VERSION "12.2.3"

NS_ :

BS_:

BU_: AVAS EPS FCAM_Chassis IDB_Chassis PAS_Chassis RCU_Chassis VCU_Chassis XGW_Chassis YSS

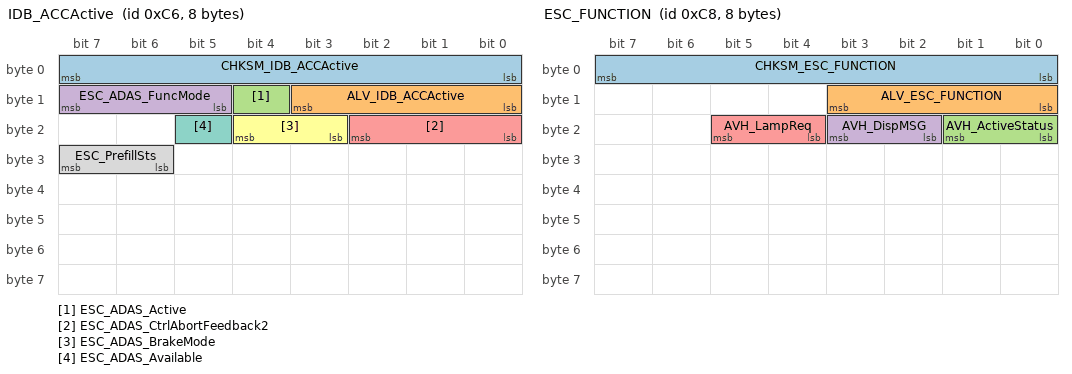
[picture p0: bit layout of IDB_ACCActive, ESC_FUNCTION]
BO_ 198 IDB_ACCActive: 8 IDB_Chassis
 SG_ CHKSM_IDB_ACCActive : 7|8@0+ (1,0) [0|255] ""  FCAM_Chassis,PAS_Chassis,VCU_Chassis
 SG_ ALV_IDB_ACCActive : 11|4@0+ (1,0) [0|14] ""  FCAM_Chassis,PAS_Chassis,VCU_Chassis
 SG_ ESC_ADAS_Active : 12|1@0+ (1,0) [0|1] ""  FCAM_Chassis,PAS_Chassis
 SG_ ESC_ADAS_FuncMode : 15|3@0+ (1,0) [0|7] ""  FCAM_Chassis,PAS_Chassis
 SG_ ESC_ADAS_CtrlAbortFeedback2 : 18|3@0+ (1,0) [0|7] ""  FCAM_Chassis,PAS_Chassis
 SG_ ESC_ADAS_BrakeMode : 20|2@0+ (1,0) [0|3] ""  FCAM_Chassis,PAS_Chassis
 SG_ ESC_ADAS_Available : 21|1@0+ (1,0) [0|1] ""  FCAM_Chassis,PAS_Chassis,VCU_Chassis
 SG_ ESC_PrefillSts : 31|2@0+ (1,0) [0|3] ""  FCAM_Chassis,PAS_Chassis

BO_ 200 ESC_FUNCTION: 8 IDB_Chassis
 SG_ CHKSM_ESC_FUNCTION : 7|8@0+ (1,0) [0|255] ""  VCU_Chassis,XGW_Chassis,RCU_Chassis
 SG_ ALV_ESC_FUNCTION : 11|4@0+ (1,0) [0|14] ""  VCU_Chassis,XGW_Chassis,RCU_Chassis
 SG_ AVH_ActiveStatus : 17|2@0+ (1,0) [0|3] ""  VCU_Chassis,XGW_Chassis,RCU_Chassis
 SG_ AVH_DispMSG : 19|2@0+ (1,0) [0|3] ""  VCU_Chassis,XGW_Chassis,RCU_Chassis
 SG_ AVH_LampReq : 21|2@0+ (1,0) [0|3] ""  VCU_Chassis,XGW_Chassis,RCU_Chassis

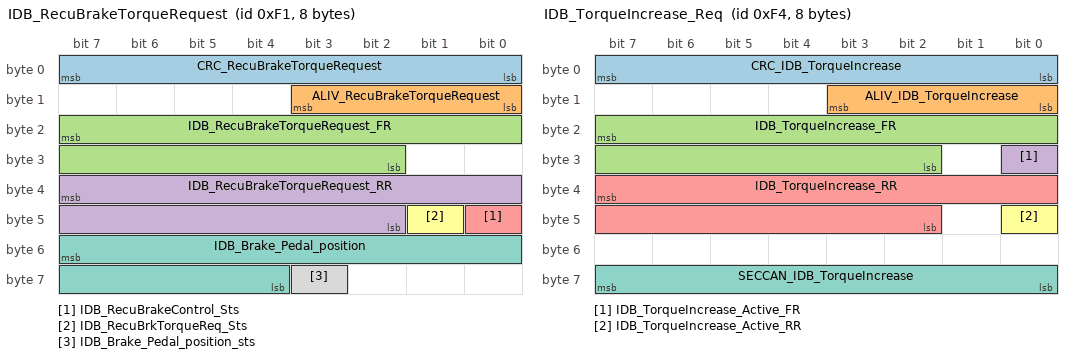
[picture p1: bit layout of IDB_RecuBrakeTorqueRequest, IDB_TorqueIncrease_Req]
BO_ 241 IDB_RecuBrakeTorqueRequest: 8 IDB_Chassis
 SG_ CRC_RecuBrakeTorqueRequest : 7|8@0+ (1,0) [0|255] ""  FCAM_Chassis,PAS_Chassis,RCU_Chassis,VCU_Chassis
 SG_ ALIV_RecuBrakeTorqueRequest : 11|4@0+ (1,0) [0|14] ""  FCAM_Chassis,PAS_Chassis,RCU_Chassis,VCU_Chassis
 SG_ IDB_RecuBrakeTorqueRequest_FR : 23|14@0+ (1,0) [0|8000] "Nm"  RCU_Chassis,VCU_Chassis
 SG_ IDB_RecuBrakeTorqueRequest_RR : 39|14@0+ (1,0) [0|8000] "Nm"  RCU_Chassis,VCU_Chassis
 SG_ IDB_RecuBrakeControl_Sts : 40|1@0+ (1,0) [0|1] ""  RCU_Chassis,VCU_Chassis
 SG_ IDB_RecuBrkTorqueReq_Sts : 41|1@0+ (1,0) [0|1] ""  VCU_Chassis
 SG_ IDB_Brake_Pedal_position : 55|12@0+ (0.0625,0) [0|100] "%"  FCAM_Chassis,RCU_Chassis,VCU_Chassis
 SG_ IDB_Brake_Pedal_position_sts : 59|1@0+ (1,0) [0|1] ""  FCAM_Chassis,PAS_Chassis,RCU_Chassis,VCU_Chassis

BO_ 244 IDB_TorqueIncrease_Req: 8 IDB_Chassis
 SG_ CRC_IDB_TorqueIncrease : 7|8@0+ (1,0) [0|255] ""  VCU_Chassis
 SG_ ALIV_IDB_TorqueIncrease : 11|4@0+ (1,0) [0|14] ""  VCU_Chassis
 SG_ IDB_TorqueIncrease_FR : 23|14@0- (1,0) [-8000|8000] "Nm"  VCU_Chassis
 SG_ IDB_TorqueIncrease_Active_FR : 24|1@0+ (1,0) [0|1] ""  VCU_Chassis
 SG_ IDB_TorqueIncrease_RR : 39|14@0- (1,0) [-8000|8000] "Nm"  VCU_Chassis
 SG_ IDB_TorqueIncrease_Active_RR : 40|1@0+ (1,0) [0|1] ""  VCU_Chassis
 SG_ SECCAN_IDB_TorqueIncrease : 63|8@0+ (1,0) [0|255] ""  VCU_Chassis

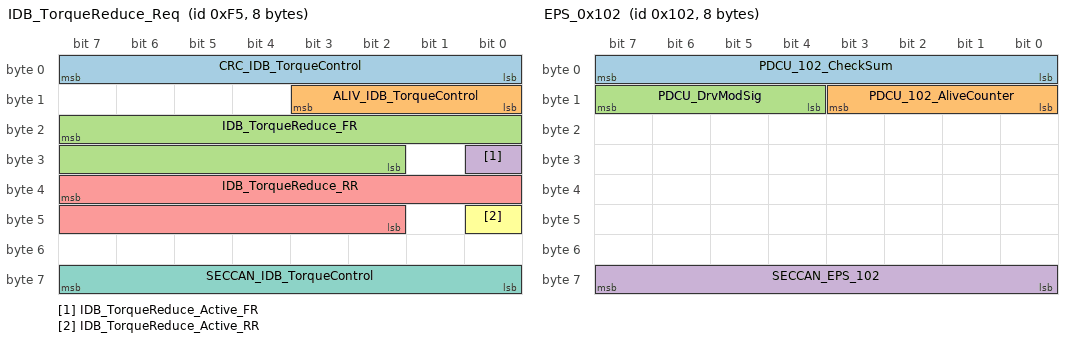
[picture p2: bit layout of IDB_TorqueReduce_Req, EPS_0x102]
BO_ 245 IDB_TorqueReduce_Req: 8 IDB_Chassis
 SG_ CRC_IDB_TorqueControl : 7|8@0+ (1,0) [0|255] ""  VCU_Chassis
 SG_ ALIV_IDB_TorqueControl : 11|4@0+ (1,0) [0|14] ""  VCU_Chassis
 SG_ IDB_TorqueReduce_FR : 23|14@0- (1,0) [-8000|8000] "Nm"  VCU_Chassis
 SG_ IDB_TorqueReduce_Active_FR : 24|1@0+ (1,0) [0|1] ""  VCU_Chassis
 SG_ IDB_TorqueReduce_RR : 39|14@0- (1,0) [-8000|8000] "Nm"  VCU_Chassis
 SG_ IDB_TorqueReduce_Active_RR : 40|1@0+ (1,0) [0|1] ""  VCU_Chassis
 SG_ SECCAN_IDB_TorqueControl : 63|8@0+ (1,0) [0|255] ""  VCU_Chassis

BO_ 257 MHU_DMS_DriverAttentionWarn: 8 XGW_Chassis
  SG_ DrowsDistractionLvl : 4|5@0+ (1,0) [0|31] "" Vector__XXX
  SG_ DriverAttentionWarn : 7|3@0+ (1,0) [0|7] "" Vector_XXX
  SG_ Haptic_Warning : 9|2@0+ (1,0) [0|3] "" EPS

BO_ 258 EPS_0x102: 8 VCU_Chassis
 SG_ PDCU_102_CheckSum : 7|8@0+ (1,0) [0|255] ""  EPS,FCAM_Chassis
 SG_ PDCU_102_AliveCounter : 11|4@0+ (1,0) [0|14] ""  EPS,FCAM_Chassis
 SG_ PDCU_DrvModSig : 15|4@0+ (1,0) [0|15] ""  EPS,FCAM_Chassis
 SG_ SECCAN_EPS_102 : 63|8@0+ (1,0) [0|255] ""  EPS

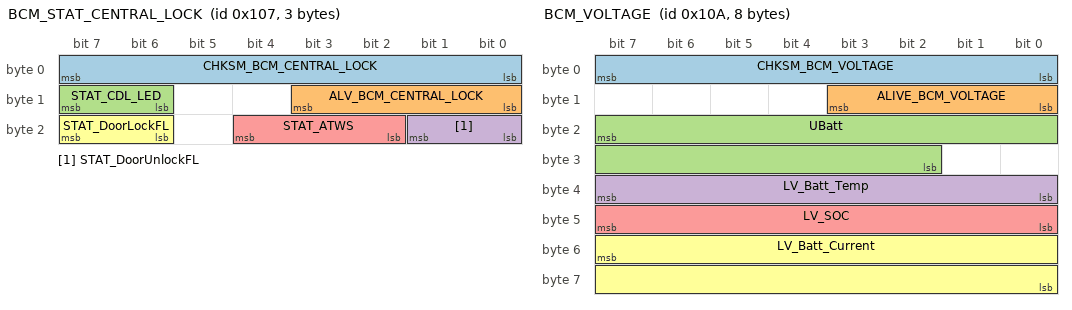
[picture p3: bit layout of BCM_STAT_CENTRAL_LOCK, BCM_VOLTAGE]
BO_ 263 BCM_STAT_CENTRAL_LOCK: 3 XGW_Chassis
 SG_ CHKSM_BCM_CENTRAL_LOCK : 7|8@0+ (1,0) [0|255] ""  VCU_Chassis
 SG_ ALV_BCM_CENTRAL_LOCK : 11|4@0+ (1,0) [0|14] ""  VCU_Chassis
 SG_ STAT_CDL_LED : 15|2@0+ (1,0) [0|3] ""  VCU_Chassis
 SG_ STAT_DoorUnlockFL : 17|2@0+ (1,0) [0|3] "Bit"  VCU_Chassis
 SG_ STAT_ATWS : 20|3@0+ (1,0) [0|7] "Bit"  VCU_Chassis
 SG_ STAT_DoorLockFL : 23|2@0+ (1,0) [0|3] "Bit"  VCU_Chassis

BO_ 266 BCM_VOLTAGE: 8 XGW_Chassis
 SG_ CHKSM_BCM_VOLTAGE : 7|8@0+ (1,0) [0|255] ""  AVAS,EPS,IDB_Chassis,RCU_Chassis,VCU_Chassis,YSS
 SG_ ALIVE_BCM_VOLTAGE : 11|4@0+ (1,0) [0|14] ""  AVAS,EPS,IDB_Chassis,RCU_Chassis,VCU_Chassis,YSS
 SG_ UBatt : 23|14@0+ (0.0009777,3) [3|18] "V"  AVAS,EPS,IDB_Chassis,RCU_Chassis,VCU_Chassis,YSS
 SG_ LV_Batt_Temp : 39|8@0+ (1,-40) [-40|105] "Degree C"  AVAS,EPS,IDB_Chassis,RCU_Chassis,VCU_Chassis,YSS
 SG_ LV_SOC : 47|8@0+ (1,0) [0|100] "%"  AVAS,EPS,IDB_Chassis,RCU_Chassis,VCU_Chassis,YSS
 SG_ LV_Batt_Current : 55|16@0+ (0.03125,-1536) [-1536|511.90625] "A"  AVAS,EPS,IDB_Chassis,RCU_Chassis,VCU_Chassis,YSS

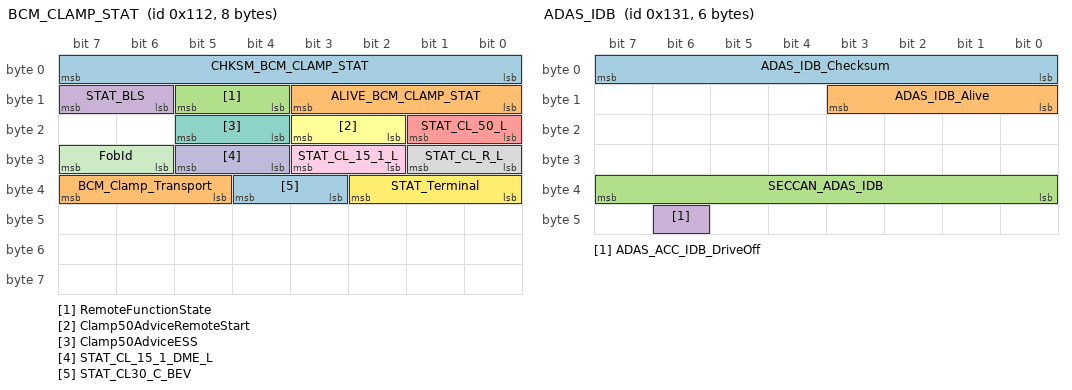
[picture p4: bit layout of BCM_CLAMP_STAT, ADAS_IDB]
BO_ 274 BCM_CLAMP_STAT: 8 XGW_Chassis
 SG_ CHKSM_BCM_CLAMP_STAT : 7|8@0+ (1,0) [0|255] ""  AVAS,EPS,IDB_Chassis,RCU_Chassis,VCU_Chassis,YSS
 SG_ ALIVE_BCM_CLAMP_STAT : 11|4@0+ (1,0) [0|14] ""  AVAS,EPS,IDB_Chassis,RCU_Chassis,VCU_Chassis,YSS
 SG_ RemoteFunctionState : 13|2@0+ (1,0) [0|3] ""  AVAS,EPS,IDB_Chassis,RCU_Chassis,VCU_Chassis,YSS
 SG_ STAT_BLS : 15|2@0+ (1,0) [0|3] ""  AVAS,EPS,IDB_Chassis,RCU_Chassis,VCU_Chassis,YSS
 SG_ STAT_CL_50_L : 17|2@0+ (1,0) [0|3] ""  AVAS,EPS,IDB_Chassis,RCU_Chassis,VCU_Chassis,YSS
 SG_ Clamp50AdviceRemoteStart : 19|2@0+ (1,0) [0|3] ""  AVAS,EPS,IDB_Chassis,RCU_Chassis,VCU_Chassis,YSS
 SG_ Clamp50AdviceESS : 21|2@0+ (1,0) [0|3] ""  AVAS,EPS,IDB_Chassis,RCU_Chassis,VCU_Chassis,YSS
 SG_ STAT_CL_R_L : 25|2@0+ (1,0) [0|3] ""  AVAS,EPS,IDB_Chassis,RCU_Chassis,VCU_Chassis,YSS
 SG_ STAT_CL_15_1_L : 27|2@0+ (1,0) [0|3] ""  AVAS,EPS,IDB_Chassis,RCU_Chassis,VCU_Chassis,YSS
 SG_ STAT_CL_15_1_DME_L : 29|2@0+ (1,0) [0|3] ""  AVAS,EPS,IDB_Chassis,RCU_Chassis,VCU_Chassis,YSS
 SG_ FobId : 31|2@0+ (1,0) [0|3] "Bit"  AVAS,EPS,IDB_Chassis,RCU_Chassis,VCU_Chassis,YSS
 SG_ STAT_Terminal : 34|3@0+ (1,0) [0|7] "Bit"  AVAS,EPS,IDB_Chassis,RCU_Chassis,VCU_Chassis,YSS
 SG_ STAT_CL30_C_BEV : 36|2@0+ (1,0) [0|3] "Bit"  AVAS,EPS,IDB_Chassis,RCU_Chassis,VCU_Chassis,YSS
 SG_ BCM_Clamp_Transport : 39|3@0+ (1,0) [0|7] ""  AVAS,EPS,IDB_Chassis,RCU_Chassis,VCU_Chassis,YSS

BO_ 275 IDB_BRAKE_PRESSURE: 5 IDB_Chassis
 SG_ MainCylinderPres : 7|16@0+ (0.01,0) [0|250] "bar"  FCAM_Chassis,VCU_Chassis
 SG_ STAT_MainCylinderPresValid : 21|2@0+ (1,0) [0|3] ""  FCAM_Chassis,VCU_Chassis
 SG_ BreakeVacuumPressure : 31|12@0- (0.1,0) [-100|10] "kPa"  VCU_Chassis

BO_ 305 ADAS_IDB: 6 FCAM_Chassis
 SG_ ADAS_IDB_Checksum : 7|8@0+ (1,0) [0|255] ""  IDB_Chassis
 SG_ ADAS_IDB_Alive : 11|4@0+ (1,0) [0|14] ""  IDB_Chassis
 SG_ SECCAN_ADAS_IDB : 39|8@0+ (1,0) [0|255] ""  IDB_Chassis
 SG_ ADAS_ACC_IDB_DriveOff : 46|1@0+ (1,0) [0|1] ""  IDB_Chassis

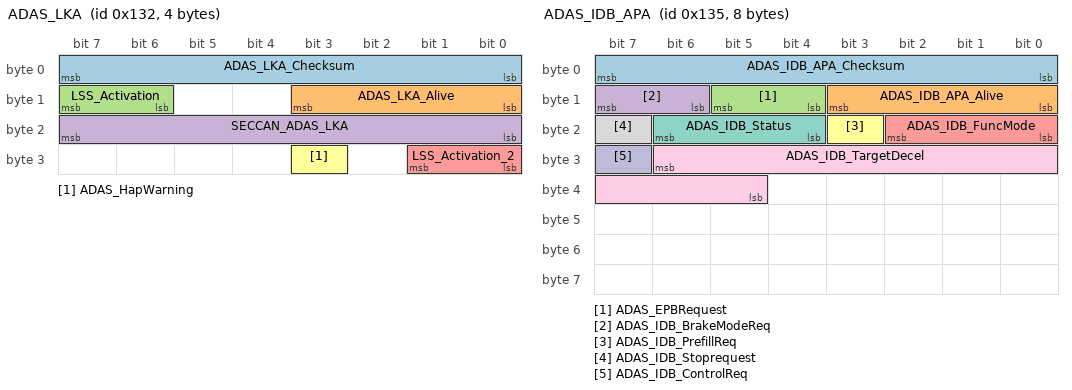
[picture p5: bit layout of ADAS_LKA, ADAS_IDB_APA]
BO_ 306 ADAS_LKA: 4 FCAM_Chassis
 SG_ ADAS_LKA_Checksum : 7|8@0+ (1,0) [0|255] ""  EPS
 SG_ ADAS_LKA_Alive : 11|4@0+ (1,0) [0|14] ""  EPS
 SG_ LSS_Activation : 15|2@0+ (1,0) [0|3] ""  EPS
 SG_ SECCAN_ADAS_LKA : 23|8@0+ (1,0) [0|255] ""  EPS
 SG_ LSS_Activation_2 : 25|2@0+ (1,0) [0|3] ""  EPS
 SG_ ADAS_HapWarning : 27|1@0+ (1,0) [0|1] ""  EPS

BO_ 309 ADAS_IDB_APA: 8 PAS_Chassis
 SG_ ADAS_IDB_APA_Checksum : 7|8@0+ (1,0) [0|255] ""  FCAM_Chassis,IDB_Chassis,RCU_Chassis,VCU_Chassis
 SG_ ADAS_IDB_APA_Alive : 11|4@0+ (1,0) [0|14] ""  FCAM_Chassis,IDB_Chassis,RCU_Chassis,VCU_Chassis
 SG_ ADAS_EPBRequest : 13|2@0+ (1,0) [0|3] ""  IDB_Chassis,RCU_Chassis,VCU_Chassis
 SG_ ADAS_IDB_BrakeModeReq : 15|2@0+ (1,0) [0|3] ""  IDB_Chassis
 SG_ ADAS_IDB_FuncMode : 18|3@0+ (1,0) [0|7] ""  IDB_Chassis
 SG_ ADAS_IDB_PrefillReq : 19|1@0+ (1,0) [0|1] ""  IDB_Chassis
 SG_ ADAS_IDB_Status : 22|3@0+ (1,0) [0|7] ""  FCAM_Chassis,IDB_Chassis
 SG_ ADAS_IDB_Stoprequest : 23|1@0+ (1,0) [0|1] ""  IDB_Chassis
 SG_ ADAS_IDB_TargetDecel : 30|10@0+ (0.01,0) [0|2.55] "m/s2"  IDB_Chassis
 SG_ ADAS_IDB_ControlReq : 31|1@0+ (1,0) [0|1] ""  IDB_Chassis

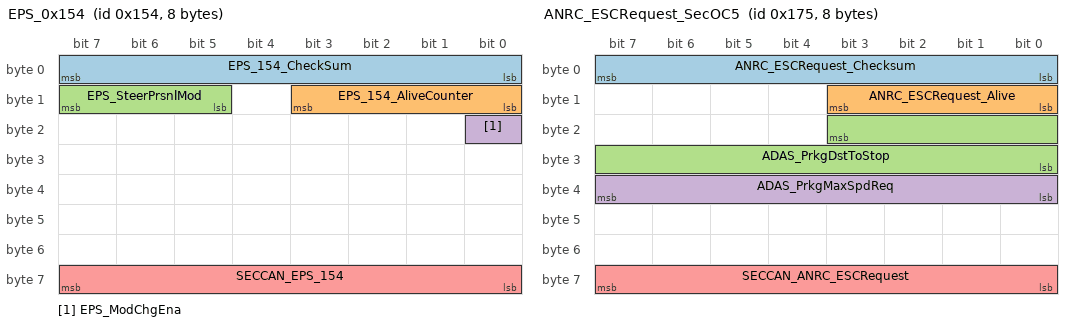
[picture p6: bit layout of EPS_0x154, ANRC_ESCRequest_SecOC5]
BO_ 340 EPS_0x154: 8 EPS
 SG_ EPS_154_CheckSum : 7|8@0+ (1,0) [0|255] ""  VCU_Chassis
 SG_ EPS_154_AliveCounter : 11|4@0+ (1,0) [0|14] ""  VCU_Chassis
 SG_ EPS_SteerPrsnlMod : 15|3@0+ (1,0) [0|7] ""  VCU_Chassis
 SG_ EPS_ModChgEna : 16|1@0+ (1,0) [0|1] ""  VCU_Chassis
 SG_ SECCAN_EPS_154 : 63|8@0+ (1,0) [0|255] ""  VCU_Chassis

BO_ 373 ANRC_ESCRequest_SecOC5: 8 PAS_Chassis
 SG_ ANRC_ESCRequest_Checksum : 7|8@0+ (1,0) [0|255] ""  IDB_Chassis
 SG_ ANRC_ESCRequest_Alive : 11|4@0+ (1,0) [0|14] ""  IDB_Chassis
 SG_ ADAS_PrkgDstToStop : 19|12@0+ (1,-100) [-100|3995] "cm"  IDB_Chassis
 SG_ ADAS_PrkgMaxSpdReq : 39|8@0+ (0.036,0) [0|9.18] "km/h"  IDB_Chassis
 SG_ SECCAN_ANRC_ESCRequest : 63|8@0+ (1,0) [0|255] ""  IDB_Chassis

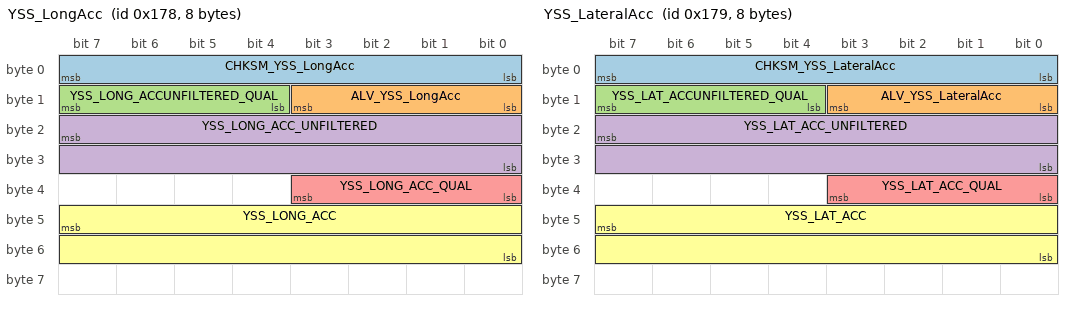
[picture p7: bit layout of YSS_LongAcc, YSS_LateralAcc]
BO_ 376 YSS_LongAcc: 8 YSS
 SG_ CHKSM_YSS_LongAcc : 7|8@0+ (1,0) [0|255] ""  FCAM_Chassis,IDB_Chassis,RCU_Chassis,VCU_Chassis,XGW_Chassis
 SG_ ALV_YSS_LongAcc : 11|4@0+ (1,0) [0|14] ""  FCAM_Chassis,IDB_Chassis,RCU_Chassis,VCU_Chassis,XGW_Chassis
 SG_ YSS_LONG_ACCUNFILTERED_QUAL : 15|4@0+ (1,0) [0|15] ""  FCAM_Chassis,IDB_Chassis,RCU_Chassis,VCU_Chassis,XGW_Chassis
 SG_ YSS_LONG_ACC_UNFILTERED : 23|16@0+ (0.002,-65.532) [-65.532|65.532] "m/s2"  FCAM_Chassis,IDB_Chassis,RCU_Chassis,VCU_Chassis,XGW_Chassis
 SG_ YSS_LONG_ACC_QUAL : 35|4@0+ (1,0) [0|15] ""  FCAM_Chassis,IDB_Chassis,RCU_Chassis,VCU_Chassis,XGW_Chassis
 SG_ YSS_LONG_ACC : 47|16@0+ (0.002,-65.532) [-65.532|65.532] "m/s2"  FCAM_Chassis,IDB_Chassis,RCU_Chassis,VCU_Chassis,XGW_Chassis

BO_ 377 YSS_LateralAcc: 8 YSS
 SG_ CHKSM_YSS_LateralAcc : 7|8@0+ (1,0) [0|255] ""  EPS,FCAM_Chassis,IDB_Chassis,RCU_Chassis,VCU_Chassis,XGW_Chassis
 SG_ ALV_YSS_LateralAcc : 11|4@0+ (1,0) [0|14] ""  EPS,FCAM_Chassis,IDB_Chassis,RCU_Chassis,VCU_Chassis,XGW_Chassis
 SG_ YSS_LAT_ACCUNFILTERED_QUAL : 15|4@0+ (1,0) [0|15] ""  EPS,FCAM_Chassis,IDB_Chassis,RCU_Chassis,VCU_Chassis,XGW_Chassis
 SG_ YSS_LAT_ACC_UNFILTERED : 23|16@0+ (0.002,-65.532) [-65.532|65.532] "m/s2"  EPS,FCAM_Chassis,IDB_Chassis,RCU_Chassis,VCU_Chassis,XGW_Chassis
 SG_ YSS_LAT_ACC_QUAL : 35|4@0+ (1,0) [0|15] ""  EPS,FCAM_Chassis,IDB_Chassis,RCU_Chassis,VCU_Chassis,XGW_Chassis
 SG_ YSS_LAT_ACC : 47|16@0+ (0.002,-65.532) [-65.532|65.532] "m/s2"  EPS,FCAM_Chassis,IDB_Chassis,RCU_Chassis,VCU_Chassis,XGW_Chassis

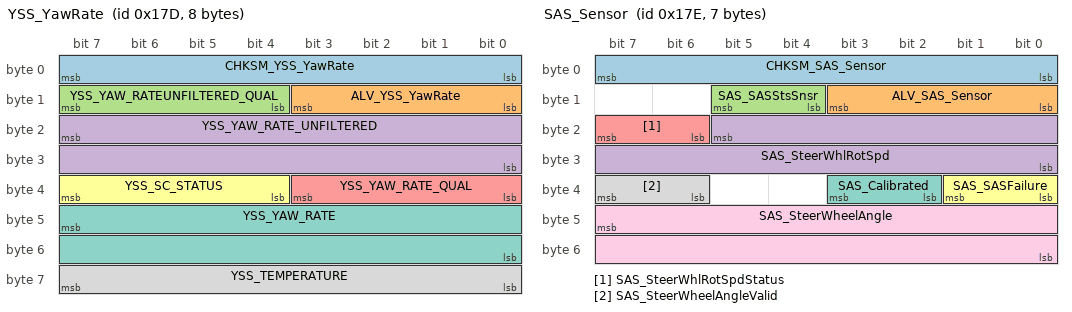
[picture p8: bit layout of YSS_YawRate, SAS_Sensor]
BO_ 381 YSS_YawRate: 8 YSS
 SG_ CHKSM_YSS_YawRate : 7|8@0+ (1,0) [0|255] ""  EPS,FCAM_Chassis,IDB_Chassis,PAS_Chassis,RCU_Chassis,VCU_Chassis,XGW_Chassis
 SG_ ALV_YSS_YawRate : 11|4@0+ (1,0) [0|14] ""  EPS,FCAM_Chassis,IDB_Chassis,PAS_Chassis,RCU_Chassis,VCU_Chassis,XGW_Chassis
 SG_ YSS_YAW_RATEUNFILTERED_QUAL : 15|4@0+ (1,0) [0|15] ""  EPS,FCAM_Chassis,IDB_Chassis,RCU_Chassis,VCU_Chassis,XGW_Chassis
 SG_ YSS_YAW_RATE_UNFILTERED : 23|16@0+ (0.005,-163.83) [-163.83|163.83] "°/s"  EPS,FCAM_Chassis,IDB_Chassis,RCU_Chassis,VCU_Chassis,XGW_Chassis
 SG_ YSS_YAW_RATE_QUAL : 35|4@0+ (1,0) [0|15] ""  EPS,FCAM_Chassis,IDB_Chassis,RCU_Chassis,VCU_Chassis,XGW_Chassis
 SG_ YSS_SC_STATUS : 39|4@0+ (1,0) [0|15] ""  EPS,FCAM_Chassis,IDB_Chassis,RCU_Chassis,VCU_Chassis,XGW_Chassis
 SG_ YSS_YAW_RATE : 47|16@0+ (0.005,-163.83) [-163.83|163.83] "°/s"  EPS,FCAM_Chassis,IDB_Chassis,PAS_Chassis,RCU_Chassis,VCU_Chassis,XGW_Chassis
 SG_ YSS_TEMPERATURE : 63|8@0+ (1,-40) [-40|115] "°C"  EPS,IDB_Chassis,RCU_Chassis,VCU_Chassis,XGW_Chassis

BO_ 382 SAS_Sensor: 7 EPS
 SG_ CHKSM_SAS_Sensor : 7|8@0+ (1,0) [0|255] ""  FCAM_Chassis,PAS_Chassis,IDB_Chassis,VCU_Chassis,XGW_Chassis
 SG_ ALV_SAS_Sensor : 11|4@0+ (1,0) [0|14] ""  FCAM_Chassis,PAS_Chassis,IDB_Chassis,VCU_Chassis,XGW_Chassis
 SG_ SAS_SASStsSnsr : 13|2@0+ (1,0) [0|1] ""  FCAM_Chassis,IDB_Chassis,VCU_Chassis,XGW_Chassis
 SG_ SAS_SteerWhlRotSpd : 21|14@0+ (0.125,-1024) [-1024|1023.875] "degree/s"  FCAM_Chassis,IDB_Chassis,VCU_Chassis,XGW_Chassis
 SG_ SAS_SteerWhlRotSpdStatus : 23|2@0+ (1,0) [0|1] ""  FCAM_Chassis,IDB_Chassis,VCU_Chassis,XGW_Chassis
 SG_ SAS_SASFailure : 33|2@0+ (1,0) [0|1] ""  FCAM_Chassis,PAS_Chassis,IDB_Chassis,VCU_Chassis,XGW_Chassis
 SG_ SAS_Calibrated : 35|2@0+ (1,0) [0|1] ""  FCAM_Chassis,PAS_Chassis,IDB_Chassis,VCU_Chassis,XGW_Chassis
 SG_ SAS_SteerWheelAngleValid : 39|2@0+ (1,0) [0|1] ""  FCAM_Chassis,PAS_Chassis,IDB_Chassis,VCU_Chassis,XGW_Chassis
 SG_ SAS_SteerWheelAngle : 47|16@0+ (0.0238,-780) [-780|779.7] "deg"  FCAM_Chassis,PAS_Chassis,IDB_Chassis,VCU_Chassis,XGW_Chassis

BO_ 383 EPS_ADAS_TOI: 8 EPS
 SG_ EPS_ADAS_function_feed_2 : 21|2@0+ (1,0) [0|3] ""  FCAM_Chassis
 SG_ EPS_ADAS_function_feed : 23|2@0+ (1,0) [0|3] ""  FCAM_Chassis
 SG_ SECCAN_EPS_ADAS_TOI : 63|8@0+ (1,0) [0|255] ""  FCAM_Chassis

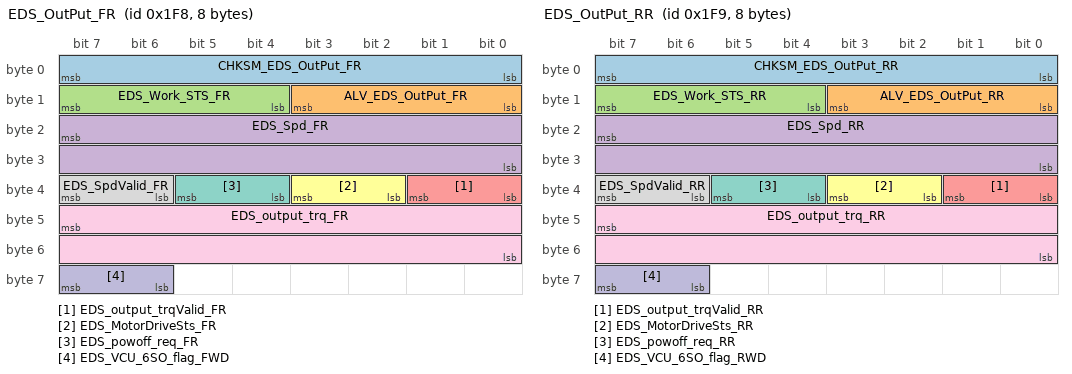
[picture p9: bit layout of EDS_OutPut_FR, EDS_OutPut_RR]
BO_ 504 EDS_OutPut_FR: 8 XGW_Chassis
 SG_ CHKSM_EDS_OutPut_FR : 7|8@0+ (1,0) [0|255] ""  AVAS,EPS,IDB_Chassis,RCU_Chassis,VCU_Chassis,YSS
 SG_ ALV_EDS_OutPut_FR : 11|4@0+ (1,0) [0|14] ""  AVAS,EPS,IDB_Chassis,RCU_Chassis,VCU_Chassis,YSS
 SG_ EDS_Work_STS_FR : 15|4@0+ (1,0) [0|15] ""  AVAS,EPS,IDB_Chassis,RCU_Chassis,VCU_Chassis,YSS
 SG_ EDS_Spd_FR : 23|16@0+ (1,-20000) [-20000|20000] "rpm"  AVAS,EPS,IDB_Chassis,RCU_Chassis,VCU_Chassis,YSS
 SG_ EDS_output_trqValid_FR : 33|2@0+ (1,0) [0|1] ""  AVAS,EPS,IDB_Chassis,RCU_Chassis,VCU_Chassis,YSS
 SG_ EDS_MotorDriveSts_FR : 35|2@0+ (1,0) [0|3] ""  AVAS,EPS,IDB_Chassis,RCU_Chassis,VCU_Chassis,YSS
 SG_ EDS_powoff_req_FR : 37|2@0+ (1,0) [0|1] ""  AVAS,EPS,IDB_Chassis,RCU_Chassis,VCU_Chassis,YSS
 SG_ EDS_SpdValid_FR : 39|2@0+ (1,0) [0|1] ""  AVAS,EPS,IDB_Chassis,RCU_Chassis,VCU_Chassis,YSS
 SG_ EDS_output_trq_FR : 47|16@0+ (1,-2000) [-2000|2000] "Nm"  AVAS,EPS,IDB_Chassis,RCU_Chassis,VCU_Chassis,YSS
 SG_ EDS_VCU_6SO_flag_FWD : 63|2@0+ (1,0) [0|1] ""  AVAS,EPS,IDB_Chassis,RCU_Chassis,VCU_Chassis,YSS

BO_ 505 EDS_OutPut_RR: 8 XGW_Chassis
 SG_ CHKSM_EDS_OutPut_RR : 7|8@0+ (1,0) [0|255] ""  AVAS,EPS,IDB_Chassis,RCU_Chassis,VCU_Chassis,YSS
 SG_ ALV_EDS_OutPut_RR : 11|4@0+ (1,0) [0|14] ""  AVAS,EPS,IDB_Chassis,RCU_Chassis,VCU_Chassis,YSS
 SG_ EDS_Work_STS_RR : 15|4@0+ (1,0) [0|15] ""  AVAS,EPS,IDB_Chassis,RCU_Chassis,VCU_Chassis,YSS
 SG_ EDS_Spd_RR : 23|16@0+ (1,-20000) [-20000|20000] "rpm"  AVAS,EPS,IDB_Chassis,RCU_Chassis,VCU_Chassis,YSS
 SG_ EDS_output_trqValid_RR : 33|2@0+ (1,0) [0|1] ""  AVAS,EPS,IDB_Chassis,RCU_Chassis,VCU_Chassis,YSS
 SG_ EDS_MotorDriveSts_RR : 35|2@0+ (1,0) [0|3] ""  AVAS,EPS,IDB_Chassis,RCU_Chassis,VCU_Chassis,YSS
 SG_ EDS_powoff_req_RR : 37|2@0+ (1,0) [0|1] ""  AVAS,EPS,IDB_Chassis,RCU_Chassis,VCU_Chassis,YSS
 SG_ EDS_SpdValid_RR : 39|2@0+ (1,0) [0|1] ""  AVAS,EPS,IDB_Chassis,RCU_Chassis,VCU_Chassis,YSS
 SG_ EDS_output_trq_RR : 47|16@0+ (1,-2000) [-2000|2000] "Nm"  AVAS,EPS,IDB_Chassis,RCU_Chassis,VCU_Chassis,YSS
 SG_ EDS_VCU_6SO_flag_RWD : 63|2@0+ (1,0) [0|1] ""  AVAS,EPS,IDB_Chassis,RCU_Chassis,VCU_Chassis,YSS

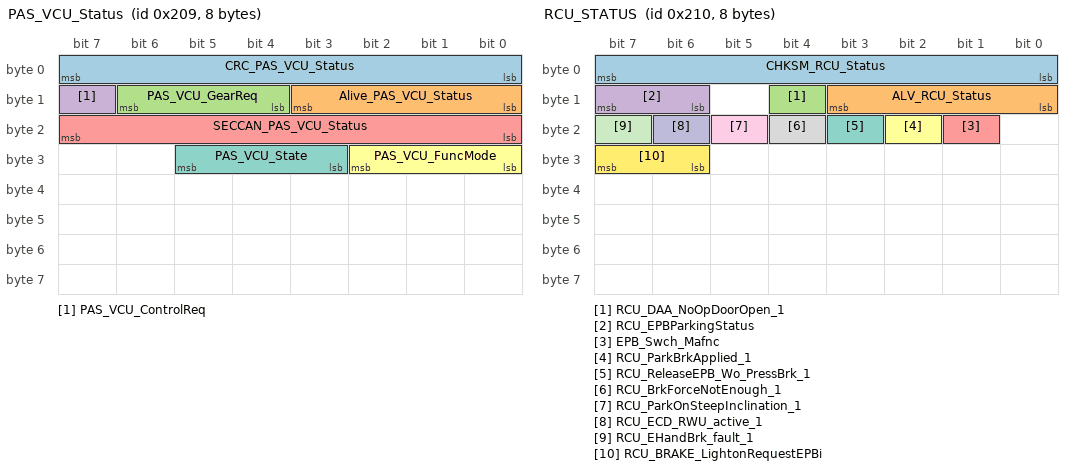
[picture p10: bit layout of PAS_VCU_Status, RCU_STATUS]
BO_ 521 PAS_VCU_Status: 8 PAS_Chassis
 SG_ CRC_PAS_VCU_Status : 7|8@0+ (1,0) [0|255] ""  VCU_Chassis
 SG_ Alive_PAS_VCU_Status : 11|4@0+ (1,0) [0|14] ""  VCU_Chassis
 SG_ PAS_VCU_GearReq : 14|3@0+ (1,0) [0|7] ""  VCU_Chassis
 SG_ PAS_VCU_ControlReq : 15|1@0+ (1,0) [0|1] ""  VCU_Chassis
 SG_ SECCAN_PAS_VCU_Status : 23|8@0+ (1,0) [0|255] ""  VCU_Chassis
 SG_ PAS_VCU_FuncMode : 26|3@0+ (1,0) [0|7] ""  VCU_Chassis
 SG_ PAS_VCU_State : 29|3@0+ (1,0) [0|7] ""  VCU_Chassis

BO_ 524 IC_ODO: 8 XGW_Chassis
 SG_ CHKSM_IC_ODO : 7|8@0+ (1,0) [0|255] ""  EPS,IDB_Chassis,RCU_Chassis,YSS
 SG_ ALIV_IC_ODO : 11|4@0+ (1,0) [0|14] ""  EPS,IDB_Chassis,RCU_Chassis,YSS
 SG_ MHU_Odometer_IC : 23|20@0+ (1,0) [0|999999] "km"  EPS,IDB_Chassis,RCU_Chassis,YSS

BO_ 525 IDB_STATUS: 8 IDB_Chassis
 SG_ CHKSM_IDB_STATUS : 7|8@0+ (1,0) [0|255] ""  AVAS,EPS,FCAM_Chassis,PAS_Chassis,RCU_Chassis,VCU_Chassis,XGW_Chassis,YSS
 SG_ ALV_IDB_STATUS : 11|4@0+ (1,0) [0|14] ""  AVAS,EPS,FCAM_Chassis,PAS_Chassis,RCU_Chassis,VCU_Chassis,XGW_Chassis,YSS
 SG_ ESPTransRequestType : 13|2@0+ (1,0) [0|3] ""  FCAM_Chassis,VCU_Chassis,XGW_Chassis
 SG_ ABSFault : 14|1@0+ (1,0) [0|1] ""  FCAM_Chassis,VCU_Chassis,XGW_Chassis
 SG_ ABSActive : 15|1@0+ (1,0) [0|1] ""  FCAM_Chassis,VCU_Chassis,XGW_Chassis
 SG_ VehicleSpd : 23|13@0+ (0.05625,0) [0|300] "km/h"  AVAS,EPS,FCAM_Chassis,PAS_Chassis,RCU_Chassis,VCU_Chassis,XGW_Chassis,YSS
 SG_ ESC_VehicleStandstill : 24|1@0+ (1,0) [0|1] ""  FCAM_Chassis,PAS_Chassis,XGW_Chassis
 SG_ MCPressureSts : 25|1@0+ (1,0) [0|1] ""  FCAM_Chassis,VCU_Chassis,XGW_Chassis
 SG_ VehicleSpdSts : 26|1@0+ (1,0) [0|1] ""  EPS,FCAM_Chassis,PAS_Chassis,VCU_Chassis,XGW_Chassis
 SG_ MCPressure : 39|8@0+ (2,-42.5) [-42.5|465.5] "bar"  FCAM_Chassis,VCU_Chassis,XGW_Chassis
 SG_ ESC_Braking_effort : 40|1@0+ (1,0) [0|1] ""  FCAM_Chassis,XGW_Chassis
 SG_ BRAKE_LightonRequestEPBi : 42|2@0+ (1,0) [0|3] ""  FCAM_Chassis,VCU_Chassis,XGW_Chassis
 SG_ VDCActive : 43|1@0+ (1,0) [0|1] ""  EPS,FCAM_Chassis,VCU_Chassis,XGW_Chassis
 SG_ TCSActive : 44|1@0+ (1,0) [0|1] ""  FCAM_Chassis,VCU_Chassis,XGW_Chassis
 SG_ TCSAvailable : 45|1@0+ (1,0) [0|1] ""  FCAM_Chassis,VCU_Chassis,XGW_Chassis
 SG_ IDBActive : 46|1@0+ (1,0) [0|1] ""  EPS,FCAM_Chassis,VCU_Chassis,XGW_Chassis
 SG_ IDBFault : 47|1@0+ (1,0) [0|1] ""  EPS,FCAM_Chassis,VCU_Chassis,XGW_Chassis
 SG_ ESC_VehicleHoldStat : 51|2@0+ (1,0) [0|3] ""  FCAM_Chassis,PAS_Chassis,XGW_Chassis
 SG_ IDB_Power_Stage : 55|4@0+ (1,0) [0|15] ""  FCAM_Chassis,VCU_Chassis,XGW_Chassis
 SG_ ESC_BrakeReleasedFailsafe : 56|1@0+ (1,0) [0|1] ""  FCAM_Chassis,XGW_Chassis

BO_ 528 RCU_STATUS: 8 RCU_Chassis
 SG_ CHKSM_RCU_Status : 7|8@0+ (1,0) [0|255] ""  FCAM_Chassis,IDB_Chassis,VCU_Chassis,PAS_Chassis,XGW_Chassis
 SG_ ALV_RCU_Status : 11|4@0+ (1,0) [0|14] ""  FCAM_Chassis,IDB_Chassis,PAS_Chassis,VCU_Chassis,XGW_Chassis
 SG_ RCU_DAA_NoOpDoorOpen_1 : 12|1@0+ (1,0) [0|1] ""  IDB_Chassis,XGW_Chassis
 SG_ RCU_EPBParkingStatus : 15|2@0+ (1,0) [0|3] ""  FCAM_Chassis,IDB_Chassis,PAS_Chassis,VCU_Chassis
 SG_ EPB_Swch_Mafnc : 17|1@0+ (1,0) [0|1] ""  IDB_Chassis,XGW_Chassis
 SG_ RCU_ParkBrkApplied_1 : 18|1@0+ (1,0) [0|1] ""  IDB_Chassis,XGW_Chassis
 SG_ RCU_ReleaseEPB_Wo_PressBrk_1 : 19|1@0+ (1,0) [0|1] ""  IDB_Chassis,XGW_Chassis
 SG_ RCU_BrkForceNotEnough_1 : 20|1@0+ (1,0) [0|1] ""  IDB_Chassis,XGW_Chassis
 SG_ RCU_ParkOnSteepInclination_1 : 21|1@0+ (1,0) [0|1] ""  IDB_Chassis,XGW_Chassis
 SG_ RCU_ECD_RWU_active_1 : 22|1@0+ (1,0) [0|1] ""  IDB_Chassis,XGW_Chassis
 SG_ RCU_EHandBrk_fault_1 : 23|1@0+ (1,0) [0|1] ""  IDB_Chassis,XGW_Chassis
 SG_ RCU_BRAKE_LightonRequestEPBi : 31|2@0+ (1,0) [0|3] ""  IDB_Chassis,VCU_Chassis,XGW_Chassis

BO_ 529 Post_Collision_Brake: 1 IDB_Chassis
 SG_ PcbCtrlFail : 6|1@0+ (1,0) [0|1] ""  RCU_Chassis
 SG_ PcbActiveFlg : 7|1@0+ (1,0) [0|1] ""  RCU_Chassis

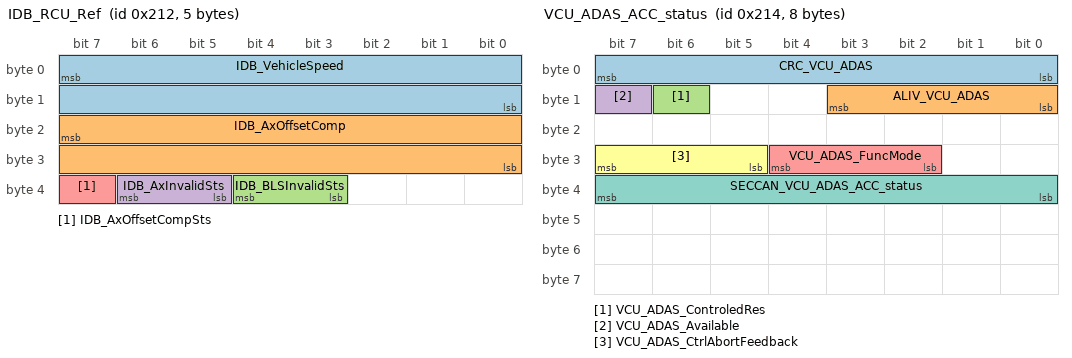
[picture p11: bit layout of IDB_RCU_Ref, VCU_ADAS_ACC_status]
BO_ 530 IDB_RCU_Ref: 5 IDB_Chassis
 SG_ IDB_VehicleSpeed : 7|16@0- (0.01563,0) [0|255] "km/h"  FCAM_Chassis,RCU_Chassis
 SG_ IDB_AxOffsetComp : 23|16@0- (0.00156,0) [-51.11808|51.11652] "g"  RCU_Chassis
 SG_ IDB_BLSInvalidSts : 36|2@0+ (1,0) [0|2] ""  RCU_Chassis
 SG_ IDB_AxInvalidSts : 38|2@0+ (1,0) [0|2] ""  RCU_Chassis
 SG_ IDB_AxOffsetCompSts : 39|1@0+ (1,0) [0|1] ""  RCU_Chassis

BO_ 532 VCU_ADAS_ACC_status: 8 VCU_Chassis
 SG_ CRC_VCU_ADAS : 7|8@0+ (1,0) [0|255] ""  PAS_Chassis
 SG_ ALIV_VCU_ADAS : 11|4@0+ (1,0) [0|14] ""  PAS_Chassis
 SG_ VCU_ADAS_ControledRes : 14|1@0+ (1,0) [0|1] ""  PAS_Chassis
 SG_ VCU_ADAS_Available : 15|1@0+ (1,0) [0|1] ""  PAS_Chassis
 SG_ VCU_ADAS_FuncMode : 28|3@0+ (1,0) [0|7] ""  PAS_Chassis
 SG_ VCU_ADAS_CtrlAbortFeedback : 31|3@0+ (1,0) [0|7] ""  PAS_Chassis
 SG_ SECCAN_VCU_ADAS_ACC_status : 39|8@0+ (1,0) [0|255] ""  PAS_Chassis

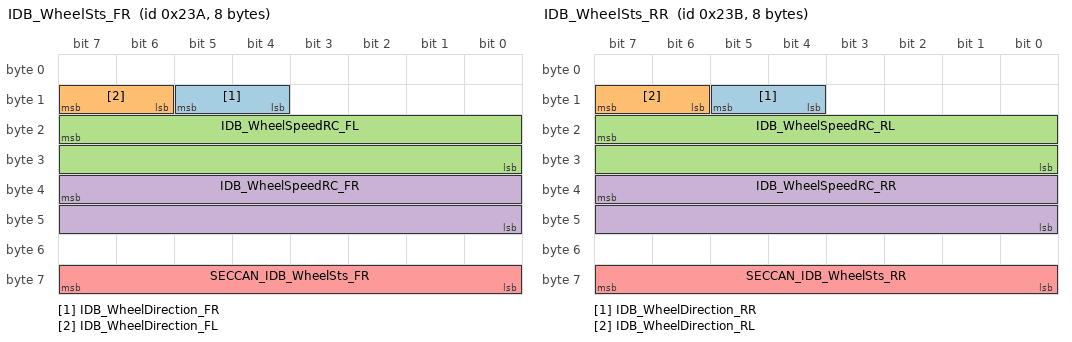
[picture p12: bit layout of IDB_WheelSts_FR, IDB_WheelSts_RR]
BO_ 570 IDB_WheelSts_FR: 8 IDB_Chassis
 SG_ IDB_WheelDirection_FR : 13|2@0+ (1,0) [0|3] ""  PAS_Chassis,XGW_Chassis
 SG_ IDB_WheelDirection_FL : 15|2@0+ (1,0) [0|3] ""  PAS_Chassis,XGW_Chassis
 SG_ IDB_WheelSpeedRC_FL : 23|16@0+ (1,0) [0|65534] ""  PAS_Chassis,XGW_Chassis
 SG_ IDB_WheelSpeedRC_FR : 39|16@0+ (1,0) [0|65534] ""  PAS_Chassis,XGW_Chassis
 SG_ SECCAN_IDB_WheelSts_FR : 63|8@0+ (1,0) [0|255] ""  PAS_Chassis,XGW_Chassis

BO_ 571 IDB_WheelSts_RR: 8 IDB_Chassis
 SG_ IDB_WheelDirection_RR : 13|2@0+ (1,0) [0|3] ""  PAS_Chassis,XGW_Chassis
 SG_ IDB_WheelDirection_RL : 15|2@0+ (1,0) [0|3] ""  PAS_Chassis,XGW_Chassis
 SG_ IDB_WheelSpeedRC_RL : 23|16@0+ (1,0) [0|65534] ""  PAS_Chassis,XGW_Chassis
 SG_ IDB_WheelSpeedRC_RR : 39|16@0+ (1,0) [0|65534] ""  PAS_Chassis,XGW_Chassis
 SG_ SECCAN_IDB_WheelSts_RR : 63|8@0+ (1,0) [0|255] ""  PAS_Chassis,XGW_Chassis

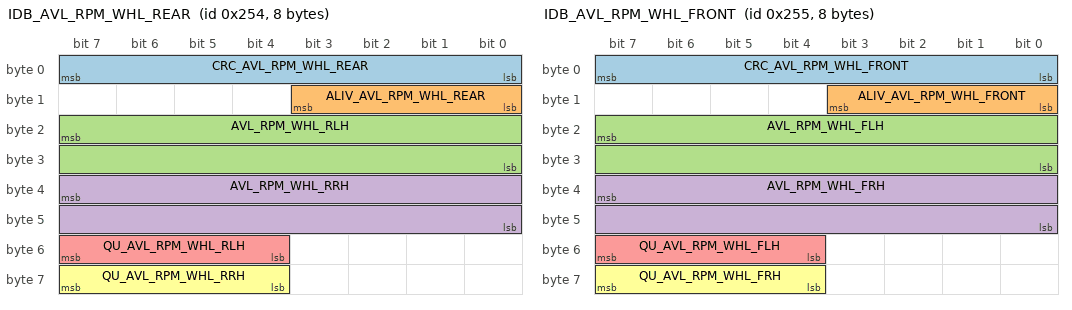
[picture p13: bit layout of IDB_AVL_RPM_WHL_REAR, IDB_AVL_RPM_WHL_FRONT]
BO_ 596 IDB_AVL_RPM_WHL_REAR: 8 IDB_Chassis
 SG_ CRC_AVL_RPM_WHL_REAR : 7|8@0+ (1,0) [0|255] ""  EPS,FCAM_Chassis,PAS_Chassis,RCU_Chassis,VCU_Chassis,XGW_Chassis
 SG_ ALIV_AVL_RPM_WHL_REAR : 11|4@0+ (1,0) [0|14] ""  EPS,FCAM_Chassis,PAS_Chassis,RCU_Chassis,VCU_Chassis,XGW_Chassis
 SG_ AVL_RPM_WHL_RLH : 23|16@0+ (0.0156,-511.9844) [-400|400] "rad/s"  EPS,FCAM_Chassis,RCU_Chassis,VCU_Chassis,XGW_Chassis
 SG_ AVL_RPM_WHL_RRH : 39|16@0+ (0.0156,-511.9844) [-400|400] "rad/s"  EPS,FCAM_Chassis,RCU_Chassis,VCU_Chassis,XGW_Chassis
 SG_ QU_AVL_RPM_WHL_RLH : 55|4@0+ (1,0) [0|15] "Bit"  EPS,FCAM_Chassis,PAS_Chassis,RCU_Chassis,VCU_Chassis,XGW_Chassis
 SG_ QU_AVL_RPM_WHL_RRH : 63|4@0+ (1,0) [0|15] "Bit"  EPS,FCAM_Chassis,PAS_Chassis,RCU_Chassis,VCU_Chassis,XGW_Chassis

BO_ 597 IDB_AVL_RPM_WHL_FRONT: 8 IDB_Chassis
 SG_ CRC_AVL_RPM_WHL_FRONT : 7|8@0+ (1,0) [0|255] ""  EPS,FCAM_Chassis,PAS_Chassis,RCU_Chassis,VCU_Chassis,XGW_Chassis
 SG_ ALIV_AVL_RPM_WHL_FRONT : 11|4@0+ (1,0) [0|14] ""  EPS,FCAM_Chassis,PAS_Chassis,RCU_Chassis,VCU_Chassis,XGW_Chassis
 SG_ AVL_RPM_WHL_FLH : 23|16@0+ (0.0156,-511.9844) [-400|400] "rad/s"  EPS,FCAM_Chassis,RCU_Chassis,VCU_Chassis,XGW_Chassis
 SG_ AVL_RPM_WHL_FRH : 39|16@0+ (0.0156,-511.9844) [-400|400] "rad/s"  EPS,FCAM_Chassis,RCU_Chassis,VCU_Chassis,XGW_Chassis
 SG_ QU_AVL_RPM_WHL_FLH : 55|4@0+ (1,0) [0|15] "Bit"  EPS,FCAM_Chassis,PAS_Chassis,RCU_Chassis,VCU_Chassis,XGW_Chassis
 SG_ QU_AVL_RPM_WHL_FRH : 63|4@0+ (1,0) [0|15] "Bit"  EPS,FCAM_Chassis,PAS_Chassis,RCU_Chassis,VCU_Chassis,XGW_Chassis

BO_ 617 VCU_HV_Status: 2 VCU_Chassis
 SG_ CHKSM_VCU_HV_Status : 7|8@0+ (1,0) [0|255] ""  EPS,FCAM_Chassis,IDB_Chassis,RCU_Chassis
 SG_ ALV_VCU_HV_Status : 11|4@0+ (1,0) [0|14] ""  EPS,FCAM_Chassis,IDB_Chassis,RCU_Chassis
 SG_ VCU_VehicleHVStatus : 15|2@0+ (1,0) [0|3] ""  EPS,FCAM_Chassis,IDB_Chassis,RCU_Chassis

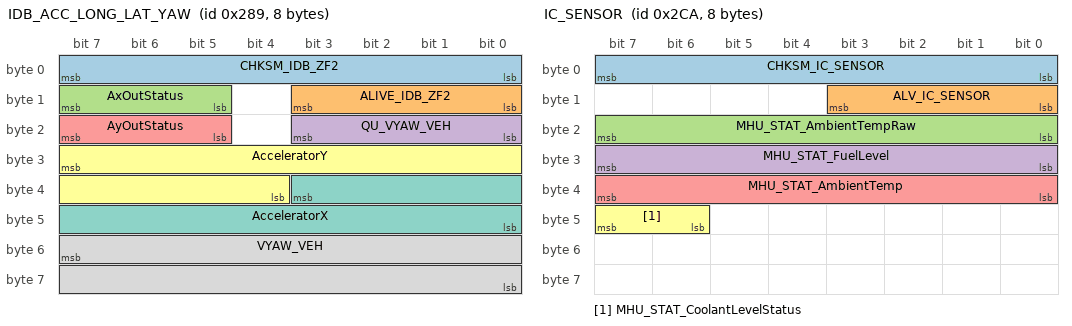
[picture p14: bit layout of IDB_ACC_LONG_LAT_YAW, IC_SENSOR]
BO_ 649 IDB_ACC_LONG_LAT_YAW: 8 IDB_Chassis
 SG_ CHKSM_IDB_ZF2 : 7|8@0+ (1,0) [0|255] ""  FCAM_Chassis,VCU_Chassis,XGW_Chassis
 SG_ ALIVE_IDB_ZF2 : 11|4@0+ (1,0) [0|14] ""  FCAM_Chassis,VCU_Chassis,XGW_Chassis
 SG_ AxOutStatus : 15|3@0+ (1,0) [0|7] ""  FCAM_Chassis,XGW_Chassis
 SG_ QU_VYAW_VEH : 19|4@0+ (1,0) [0|15] ""  XGW_Chassis
 SG_ AyOutStatus : 23|3@0+ (1,0) [0|7] ""  FCAM_Chassis,XGW_Chassis
 SG_ AcceleratorY : 31|12@0+ (0.02713,-21.5928) [-21.593|21.5928] "m/s²"  FCAM_Chassis,XGW_Chassis
 SG_ AcceleratorX : 35|12@0+ (0.02713,-21.5928) [-21.593|21.5928] "m/s²"  FCAM_Chassis,VCU_Chassis,XGW_Chassis
 SG_ VYAW_VEH : 55|16@0+ (0.005,-163.84) [-163.84|163.83] "°/s"  XGW_Chassis

BO_ 714 IC_SENSOR: 8 XGW_Chassis
 SG_ CHKSM_IC_SENSOR : 7|8@0+ (1,0) [0|255] ""  AVAS,EPS,IDB_Chassis,RCU_Chassis,VCU_Chassis,YSS
 SG_ ALV_IC_SENSOR : 11|4@0+ (1,0) [0|14] ""  AVAS,EPS,IDB_Chassis,RCU_Chassis,VCU_Chassis,YSS
 SG_ MHU_STAT_AmbientTempRaw : 23|8@0+ (0.5,-40) [-40|85] "°C"  AVAS,EPS,IDB_Chassis,RCU_Chassis,VCU_Chassis,YSS
 SG_ MHU_STAT_FuelLevel : 31|8@0+ (1,0) [0|100] "l"  AVAS,EPS,IDB_Chassis,RCU_Chassis,VCU_Chassis,YSS
 SG_ MHU_STAT_AmbientTemp : 39|8@0+ (0.5,-40) [-40|85] "Degree C"  AVAS,EPS,IDB_Chassis,RCU_Chassis,VCU_Chassis,YSS
 SG_ MHU_STAT_CoolantLevelStatus : 47|2@0+ (1,0) [0|3] ""  AVAS,EPS,IDB_Chassis,RCU_Chassis,VCU_Chassis,YSS

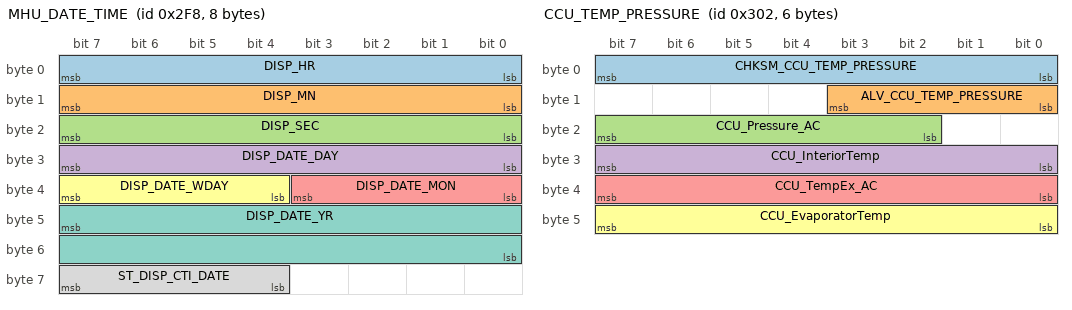
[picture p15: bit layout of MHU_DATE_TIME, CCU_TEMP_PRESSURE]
BO_ 760 MHU_DATE_TIME: 8 XGW_Chassis
 SG_ DISP_HR : 7|8@0+ (1,0) [0|23] "h"  AVAS,EPS,IDB_Chassis,RCU_Chassis,VCU_Chassis,YSS
 SG_ DISP_MN : 15|8@0+ (1,0) [0|59] "min"  AVAS,EPS,IDB_Chassis,RCU_Chassis,VCU_Chassis,YSS
 SG_ DISP_SEC : 23|8@0+ (1,0) [0|59] "s"  AVAS,EPS,IDB_Chassis,RCU_Chassis,VCU_Chassis,YSS
 SG_ DISP_DATE_DAY : 31|8@0+ (1,0) [1|31] "Day"  AVAS,EPS,IDB_Chassis,RCU_Chassis,VCU_Chassis,YSS
 SG_ DISP_DATE_MON : 35|4@0+ (1,0) [1|12] "Month"  AVAS,EPS,IDB_Chassis,RCU_Chassis,VCU_Chassis,YSS
 SG_ DISP_DATE_WDAY : 39|4@0+ (1,0) [0|15] ""  AVAS,EPS,IDB_Chassis,RCU_Chassis,VCU_Chassis,YSS
 SG_ DISP_DATE_YR : 47|16@0+ (1,0) [1|65534] "Year"  AVAS,EPS,IDB_Chassis,RCU_Chassis,VCU_Chassis,YSS
 SG_ ST_DISP_CTI_DATE : 63|4@0+ (1,0) [0|15] ""  AVAS,EPS,IDB_Chassis,RCU_Chassis,VCU_Chassis,YSS

BO_ 770 CCU_TEMP_PRESSURE: 6 XGW_Chassis
 SG_ CHKSM_CCU_TEMP_PRESSURE : 7|8@0+ (1,0) [0|255] ""  AVAS,EPS,IDB_Chassis,RCU_Chassis,VCU_Chassis,YSS
 SG_ ALV_CCU_TEMP_PRESSURE : 11|4@0+ (1,0) [0|14] ""  AVAS,EPS,IDB_Chassis,RCU_Chassis,VCU_Chassis,YSS
 SG_ CCU_Pressure_AC : 23|6@0+ (1,0) [0|62] "bar"  AVAS,EPS,IDB_Chassis,RCU_Chassis,VCU_Chassis,YSS
 SG_ CCU_InteriorTemp : 31|8@0+ (0.5,-40) [-40|85] "Degree C"  AVAS,EPS,IDB_Chassis,RCU_Chassis,VCU_Chassis,YSS
 SG_ CCU_TempEx_AC : 39|8@0+ (0.5,-40) [-40|85] "Degree C"  AVAS,EPS,IDB_Chassis,RCU_Chassis,VCU_Chassis,YSS
 SG_ CCU_EvaporatorTemp : 47|8@0+ (0.5,-40) [-40|85] "Degree C"  AVAS,EPS,IDB_Chassis,RCU_Chassis,VCU_Chassis,YSS

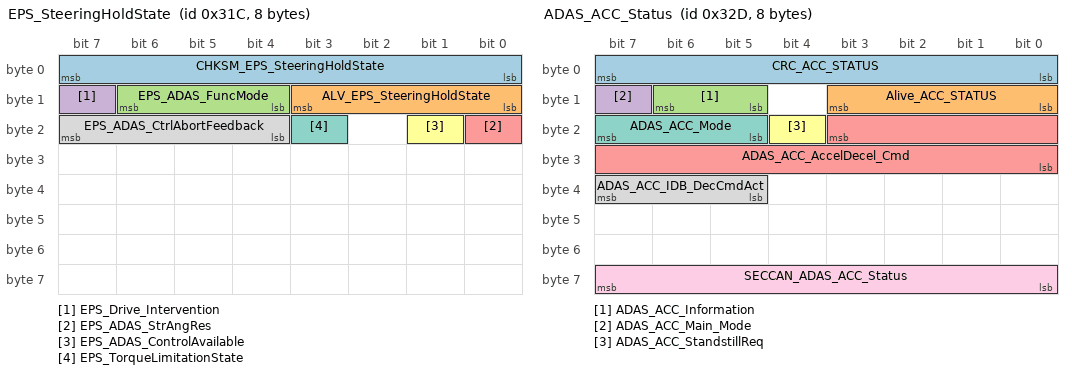
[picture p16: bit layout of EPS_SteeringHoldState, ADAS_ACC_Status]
BO_ 796 EPS_SteeringHoldState: 8 EPS
 SG_ CHKSM_EPS_SteeringHoldState : 7|8@0+ (1,0) [0|255] ""  FCAM_Chassis,PAS_Chassis
 SG_ ALV_EPS_SteeringHoldState : 11|4@0+ (1,0) [0|14] ""  FCAM_Chassis,PAS_Chassis
 SG_ EPS_ADAS_FuncMode : 14|3@0+ (1,0) [0|7] ""  FCAM_Chassis,PAS_Chassis
 SG_ EPS_Drive_Intervention : 15|1@0+ (1,0) [0|1] ""  FCAM_Chassis,PAS_Chassis
 SG_ EPS_ADAS_StrAngRes : 16|1@0+ (1,0) [0|1] ""  FCAM_Chassis,PAS_Chassis
 SG_ EPS_ADAS_ControlAvailable : 17|1@0+ (1,0) [0|1] ""  FCAM_Chassis,PAS_Chassis
 SG_ EPS_TorqueLimitationState : 19|1@0+ (1,0) [0|1] ""  FCAM_Chassis,PAS_Chassis
 SG_ EPS_ADAS_CtrlAbortFeedback : 23|4@0+ (1,0) [0|7] ""  FCAM_Chassis,PAS_Chassis

BO_ 813 ADAS_ACC_Status: 8 FCAM_Chassis
 SG_ CRC_ACC_STATUS : 7|8@0+ (1,0) [0|255] ""  IDB_Chassis
 SG_ Alive_ACC_STATUS : 11|4@0+ (1,0) [0|14] ""  IDB_Chassis
 SG_ ADAS_ACC_Information : 14|2@0+ (1,0) [0|3] ""  IDB_Chassis
 SG_ ADAS_ACC_Main_Mode : 15|1@0+ (1,0) [0|1] ""  IDB_Chassis
 SG_ ADAS_ACC_AccelDecel_Cmd : 19|12@0+ (0.005,-6) [-6|6] "m/s²"  IDB_Chassis
 SG_ ADAS_ACC_StandstillReq : 20|1@0+ (1,0) [0|1] ""  IDB_Chassis
 SG_ ADAS_ACC_Mode : 23|3@0+ (1,0) [0|7] ""  IDB_Chassis
 SG_ ADAS_ACC_IDB_DecCmdAct : 39|3@0+ (1,0) [0|1] ""  IDB_Chassis
 SG_ SECCAN_ADAS_ACC_Status : 63|8@0+ (1,0) [0|255] ""  IDB_Chassis

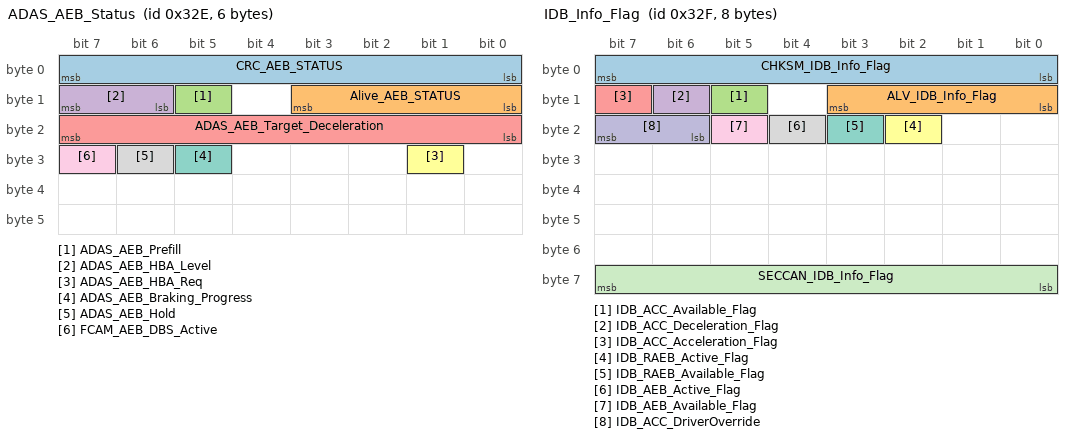
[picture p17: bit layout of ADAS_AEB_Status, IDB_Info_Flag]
BO_ 814 ADAS_AEB_Status: 6 FCAM_Chassis
 SG_ CRC_AEB_STATUS : 7|8@0+ (1,0) [0|255] ""  IDB_Chassis,XGW_Chassis
 SG_ Alive_AEB_STATUS : 11|4@0+ (1,0) [0|14] ""  IDB_Chassis,XGW_Chassis
 SG_ ADAS_AEB_Prefill : 13|1@0+ (1,0) [0|1] ""  IDB_Chassis
 SG_ ADAS_AEB_HBA_Level : 15|2@0+ (1,0) [0|3] ""  IDB_Chassis
 SG_ ADAS_AEB_Target_Deceleration : 23|8@0+ (0.1,-12.7) [-12.7|12.8] "m/s²"  IDB_Chassis
 SG_ ADAS_AEB_HBA_Req : 25|1@0+ (1,0) [0|1] ""  IDB_Chassis
 SG_ ADAS_AEB_Braking_Progress : 29|1@0+ (1,0) [0|1] ""  IDB_Chassis,PAS_Chassis,XGW_Chassis
 SG_ ADAS_AEB_Hold : 30|1@0+ (1,0) [0|1] ""  IDB_Chassis
 SG_ FCAM_AEB_DBS_Active : 31|1@0+ (1,0) [0|1] ""  IDB_Chassis

BO_ 815 IDB_Info_Flag: 8 IDB_Chassis
 SG_ CHKSM_IDB_Info_Flag : 7|8@0+ (1,0) [0|255] ""  FCAM_Chassis
 SG_ ALV_IDB_Info_Flag : 11|4@0+ (1,0) [0|14] ""  FCAM_Chassis
 SG_ IDB_ACC_Available_Flag : 13|1@0+ (1,0) [0|1] ""  FCAM_Chassis
 SG_ IDB_ACC_Deceleration_Flag : 14|1@0+ (1,0) [0|1] ""  FCAM_Chassis
 SG_ IDB_ACC_Acceleration_Flag : 15|1@0+ (1,0) [0|1] ""  FCAM_Chassis
 SG_ IDB_RAEB_Active_Flag : 18|1@0+ (1,0) [0|1] ""  FCAM_Chassis
 SG_ IDB_RAEB_Available_Flag : 19|1@0+ (1,0) [0|1] ""  FCAM_Chassis
 SG_ IDB_AEB_Active_Flag : 20|1@0+ (1,0) [0|1] ""  FCAM_Chassis
 SG_ IDB_AEB_Available_Flag : 21|1@0+ (1,0) [0|1] ""  FCAM_Chassis
 SG_ IDB_ACC_DriverOverride : 23|2@0+ (1,0) [0|3] ""  FCAM_Chassis
 SG_ SECCAN_IDB_Info_Flag : 63|8@0+ (1,0) [0|255] ""  FCAM_Chassis

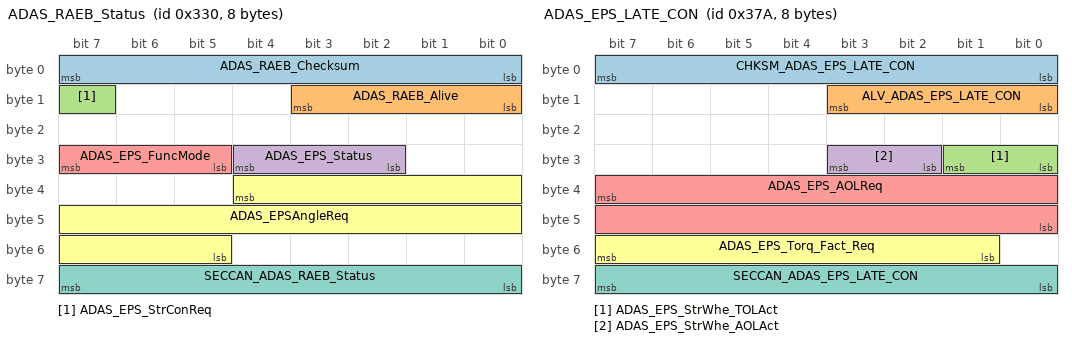
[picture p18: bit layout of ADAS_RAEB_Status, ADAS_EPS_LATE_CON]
BO_ 816 ADAS_RAEB_Status: 8 PAS_Chassis
 SG_ ADAS_RAEB_Checksum : 7|8@0+ (1,0) [0|255] ""  EPS
 SG_ ADAS_RAEB_Alive : 11|4@0+ (1,0) [0|14] ""  EPS
 SG_ ADAS_EPS_StrConReq : 15|1@0+ (1,0) [0|1] ""  EPS
 SG_ ADAS_EPS_Status : 28|3@0+ (1,0) [0|7] ""  EPS
 SG_ ADAS_EPS_FuncMode : 31|3@0+ (1,0) [0|7] ""  EPS
 SG_ ADAS_EPSAngleReq : 36|16@0+ (0.0238,-780) [-780|779.7] ""  EPS
 SG_ SECCAN_ADAS_RAEB_Status : 63|8@0+ (1,0) [0|255] ""  EPS

BO_ 817 IC_MILEAGE: 8 XGW_Chassis
 SG_ MILE_KM : 7|24@0+ (1,0) [0|999999] "km"  EPS
 SG_ FLLV_FUTA : 31|8@0+ (1,0) [0|254] "l"  EPS
 SG_ RNG : 51|12@0+ (1,0) [0|4094] "km"  EPS
 SG_ ST_FLLV_FUTA_SPAR : 55|2@0+ (1,0) [0|3] ""  EPS

BO_ 890 ADAS_EPS_LATE_CON: 8 FCAM_Chassis
 SG_ CHKSM_ADAS_EPS_LATE_CON : 7|8@0+ (1,0) [0|255] ""  EPS
 SG_ ALV_ADAS_EPS_LATE_CON : 11|4@0+ (1,0) [0|14] ""  EPS
 SG_ ADAS_EPS_StrWhe_TOLAct : 25|2@0+ (1,0) [0|3] ""  EPS
 SG_ ADAS_EPS_StrWhe_AOLAct : 27|2@0+ (1,0) [0|3] ""  EPS
 SG_ ADAS_EPS_AOLReq : 39|16@0+ (0.0238,-780) [-780|779.7] "deg"  EPS
 SG_ ADAS_EPS_Torq_Fact_Req : 55|7@0+ (0.01,0) [0|1] ""  EPS
 SG_ SECCAN_ADAS_EPS_LATE_CON : 63|8@0+ (1,0) [0|255] ""  EPS

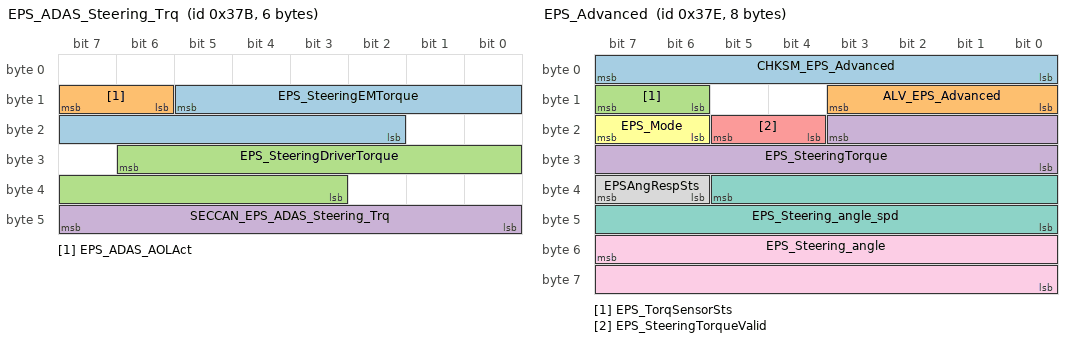
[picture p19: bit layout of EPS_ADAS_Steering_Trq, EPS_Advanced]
BO_ 891 EPS_ADAS_Steering_Trq: 6 EPS
 SG_ EPS_SteeringEMTorque : 13|12@0+ (0.01,-10.24) [-10.24|10.23] "Nm"  FCAM_Chassis
 SG_ EPS_ADAS_AOLAct : 15|2@0+ (1,0) [0|3] ""  FCAM_Chassis
 SG_ EPS_SteeringDriverTorque : 30|12@0+ (0.01,-10.24) [-10.24|10.23] "Nm"  FCAM_Chassis,PAS_Chassis
 SG_ SECCAN_EPS_ADAS_Steering_Trq : 47|8@0+ (1,0) [0|255] ""  FCAM_Chassis

BO_ 894 EPS_Advanced: 8 EPS
 SG_ CHKSM_EPS_Advanced : 7|8@0+ (1,0) [0|255] ""  FCAM_Chassis,IDB_Chassis
 SG_ ALV_EPS_Advanced : 11|4@0+ (1,0) [0|14] ""  FCAM_Chassis,IDB_Chassis
 SG_ EPS_TorqSensorSts : 15|2@0+ (1,0) [0|1] ""  IDB_Chassis
 SG_ EPS_SteeringTorque : 19|12@0+ (0.01,-10.24) [-10.24|10.23] "Nm"  FCAM_Chassis,IDB_Chassis
 SG_ EPS_SteeringTorqueValid : 21|2@0+ (1,0) [0|1] "" FCAM_Chassis
 SG_ EPS_Mode : 23|2@0+ (1,0) [0|3] ""  FCAM_Chassis,IDB_Chassis
 SG_ EPS_Steering_angle_spd : 37|14@0+ (0.125,-1024) [-1024|1023.875] "degree/s" FCAM_Chassis
 SG_ EPSAngRespSts : 39|2@0+ (1,0) [0|3] "" FCAM_Chassis
 SG_ EPS_Steering_angle : 55|16@0+ (0.0238,-780) [-780|779.733] "deg" FCAM_Chassis

CM_ "Chassis's communication database for FaceLift variant";
CM_ BU_ AVAS "Acoustic Vehicle Alarm System";
CM_ BU_ EPS "Electric power steering";
CM_ BU_ FCAM_Chassis "Front Camera ADAS Module";
CM_ BU_ IDB_Chassis "Intelligent Distribution Brake";
CM_ BU_ PAS_Chassis "Parking Assistant System";
CM_ BU_ RCU_Chassis "Redudant Control Unit";
CM_ BU_ VCU_Chassis "Vehicle Control Unit";
CM_ BU_ XGW_Chassis "Gateway";
CM_ BU_ YSS "Yaw-Rate Sensor";
CM_ BO_ 198 "IDB_ACCActive";
CM_ SG_ 198 CHKSM_IDB_ACCActive "Checksum.";
CM_ SG_ 198 ALV_IDB_ACCActive "Alive Counter.";
CM_ SG_ 198 ESC_ADAS_Active "ESC control state for APA";
CM_ SG_ 198 ESC_ADAS_FuncMode "ESC & APA Function Mode";
CM_ SG_ 198 ESC_ADAS_CtrlAbortFeedback2 "ESC Control Abort Reasons";
CM_ SG_ 198 ESC_ADAS_BrakeMode "ESC Displays the current brake mode";
CM_ SG_ 198 ESC_ADAS_Available "whether ESC can surpport APA contronl or not";
CM_ SG_ 198 ESC_PrefillSts "ESC Prefill Status";
CM_ BO_ 200 "Electronic Stability Control (ESC) function";
CM_ SG_ 200 CHKSM_ESC_FUNCTION "Checksum";
CM_ SG_ 200 ALV_ESC_FUNCTION "Alive Counter";
CM_ SG_ 200 AVH_ActiveStatus "Auto Hold Status";
CM_ SG_ 200 AVH_DispMSG "Auto Hold Text Message Display request";
CM_ SG_ 200 AVH_LampReq "Auto Hold Lamp (cluster tell-tale) request";
CM_ BO_ 241 "IDB Recu Brake Torque Request";
CM_ SG_ 241 CRC_RecuBrakeTorqueRequest "Checksum";
CM_ SG_ 241 ALIV_RecuBrakeTorqueRequest "Alive counter";
CM_ SG_ 241 IDB_RecuBrakeTorqueRequest_FR "The signal shows the recuperation torque request of the brake system (FR)";
CM_ SG_ 241 IDB_RecuBrakeTorqueRequest_RR "The signal shows the recuperation torque request of the brake system (RR)";
CM_ SG_ 241 IDB_RecuBrakeControl_Sts "Regen cooperation control enable status of IDB
This signal that IDB system is possible to regenerative braking cooperation control including status of VCU(Regen enable status of motor).";
CM_ SG_ 241 IDB_RecuBrkTorqueReq_Sts "Indicate Regenerative Braking function is active or not. This signal that regen cooperation is controlling(Target Regen Torque > 0)";
CM_ SG_ 241 IDB_Brake_Pedal_position "Brake pedal position";
CM_ SG_ 241 IDB_Brake_Pedal_position_sts "Qualifier for corresponding signal of Brake pedal position";
CM_ BO_ 244 "IDB Torque inscrease request";
CM_ SG_ 244 CRC_IDB_TorqueIncrease "Checksum";
CM_ SG_ 244 ALIV_IDB_TorqueIncrease "Alive counter";
CM_ SG_ 244 IDB_TorqueIncrease_FR "Target increased Emotor_Front torque (drag torque control)";
CM_ SG_ 244 IDB_TorqueIncrease_Active_FR "Emotor_Front torque increase active";
CM_ SG_ 244 IDB_TorqueIncrease_RR "Target increased Emotor_Rear torque (drag torque control)";
CM_ SG_ 244 IDB_TorqueIncrease_Active_RR "Emotor_Rear torque increase active";
CM_ SG_ 244 SECCAN_IDB_TorqueIncrease "Secret portion from Secure CAN algorithm";
CM_ BO_ 245 "IDB Torque Reduce request";
CM_ SG_ 245 CRC_IDB_TorqueControl "Checksum";
CM_ SG_ 245 ALIV_IDB_TorqueControl "Alive counter";
CM_ SG_ 245 IDB_TorqueReduce_FR "Target reduced Emotor_Front torque (TCS torque control)";
CM_ SG_ 245 IDB_TorqueReduce_Active_FR "Emotor_Front torque reduction active";
CM_ SG_ 245 IDB_TorqueReduce_RR "Target reduced Emotor_Rear torque (TCS torque control)";
CM_ SG_ 245 IDB_TorqueReduce_Active_RR "Emotor_Rear torque reduction active";
CM_ SG_ 245 SECCAN_IDB_TorqueControl "Secret portion from Secure CAN algorithm";
CM_ BO_ 257 "Driver Attention Monitoring System Warning Level";
CM_ SG_ 257 DrowsDistractionLvl "Drowsiness Distraction level";
CM_ SG_ 257 DriverAttentionWarn "Driver Attention Monitoring System Warning Level";
CM_ SG_ 257 Haptic_Warning "Haptic device operation command from DMS";
CM_ BO_ 258 "EPS_0x102";
CM_ SG_ 258 PDCU_102_CheckSum "CheckSum";
CM_ SG_ 258 PDCU_102_AliveCounter "AliveCounter";
CM_ SG_ 258 PDCU_DrvModSig "Driving Mode Signal";
CM_ SG_ 258 SECCAN_EPS_102 "Seed generated from Secure CAN algorithm";
CM_ BO_ 263 "BCM Status Central Lock";
CM_ SG_ 263 CHKSM_BCM_CENTRAL_LOCK "Checksum ";
CM_ SG_ 263 ALV_BCM_CENTRAL_LOCK "Alive counter";
CM_ SG_ 263 STAT_CDL_LED "Status of functional CDL button LED, value 2 represents implausible state";
CM_ SG_ 263 STAT_DoorUnlockFL "UnLock Status Driver Door not used for lock status";
CM_ SG_ 263 STAT_ATWS "Locking/UnLocking Status Anti theft Invalid value = 7";
CM_ SG_ 263 STAT_DoorLockFL "Lock Status Driver Door used as central lock information";
CM_ BO_ 266 "Low Voltage Battery";
CM_ SG_ 266 CHKSM_BCM_VOLTAGE "Checksum";
CM_ SG_ 266 ALIVE_BCM_VOLTAGE "Alive counter";
CM_ SG_ 266 UBatt "Battery Voltage";
CM_ SG_ 266 LV_Batt_Temp "Low voltage Battery Temperature";
CM_ SG_ 266 LV_SOC "State Of charge for Low Voltage Battery";
CM_ SG_ 266 LV_Batt_Current "Current of Low Voltage Battery";
CM_ BO_ 274 "Clamp status for BEV vehicle";
CM_ SG_ 274 CHKSM_BCM_CLAMP_STAT "Checksum";
CM_ SG_ 274 ALIVE_BCM_CLAMP_STAT "Alive counter";
CM_ SG_ 274 RemoteFunctionState "0x1(remote function) will be sent after PreRemoteStart=0x1 first time in ignition OFF state, and this signal will be kept 0x1 until SESAM exit remote state.";
CM_ SG_ 274 STAT_BLS "Signal represent plausibility of both HW Inputs for brake light switch.";
CM_ SG_ 274 STAT_CL_50_L "Logical clamp status";
CM_ SG_ 274 Clamp50AdviceRemoteStart "Engine Start announcement (Clamp 50) for remote start";
CM_ SG_ 274 Clamp50AdviceESS "Engine Start announcement (Clamp 50) for ESS";
CM_ SG_ 274 STAT_CL_R_L "Logical clamp status";
CM_ SG_ 274 STAT_CL_15_1_L "Logical clamp status";
CM_ SG_ 274 STAT_CL_15_1_DME_L "Logical clamp status";
CM_ SG_ 274 FobId "Information of FOB ID.";
CM_ SG_ 274 STAT_Terminal "Represent the status of physical terminal";
CM_ SG_ 274 STAT_CL30_C_BEV "Logical clamp status";
CM_ SG_ 274 BCM_Clamp_Transport "BCM_Clamp_Transport";
CM_ BO_ 275 "EPBi Brake presure";
CM_ SG_ 275 MainCylinderPres "Pressure of the braking system (Pressure if the master cylinder).";
CM_ SG_ 275 STAT_MainCylinderPresValid "Validity bit for the signal Brake Main Cylinder Presure";
CM_ SG_ 275 BreakeVacuumPressure "Breake vaccum pressure";
CM_ BO_ 305 "ADAS_IDB_1";
CM_ SG_ 305 ADAS_IDB_Checksum "Checksum";
CM_ SG_ 305 ADAS_IDB_Alive "Alive Counter";
CM_ SG_ 305 SECCAN_ADAS_IDB "Seed generated from Secure CAN algorithm";
CM_ SG_ 305 ADAS_ACC_IDB_DriveOff "DriveOff request flag";
CM_ BO_ 306 "ADAS Lane Keep Assist";
CM_ SG_ 306 ADAS_LKA_Checksum "Checksum";
CM_ SG_ 306 ADAS_LKA_Alive "Alive Counter";
CM_ SG_ 306 LSS_Activation "LSS Activation source";
CM_ SG_ 306 SECCAN_ADAS_LKA "Seed generated from Secure CAN algorithm";
CM_ SG_ 306 LSS_Activation_2 "Supplementory Lateral control mode signal";
CM_ SG_ 306 ADAS_HapWarning "Haptic device operation command";
CM_ BO_ 309 "ADAS IDB APA";
CM_ SG_ 309 ADAS_IDB_APA_Checksum "Checksum";
CM_ SG_ 309 ADAS_IDB_APA_Alive "Alive Counter";
CM_ SG_ 309 ADAS_EPBRequest "APA request IDB to apply the EPB,but not request release";
CM_ SG_ 309 ADAS_IDB_BrakeModeReq "APA request ESC carry out brake mode";
CM_ SG_ 309 ADAS_IDB_FuncMode "APA request IDB carry out function mode";
CM_ SG_ 309 ADAS_IDB_PrefillReq "APA request ESC carry out Prefill";
CM_ SG_ 309 ADAS_IDB_Status "ADAS_Status";
CM_ SG_ 309 ADAS_IDB_Stoprequest "ADAS request to stop the vehicle";
CM_ SG_ 309 ADAS_IDB_TargetDecel "APA send the target deceleration to IDB";
CM_ SG_ 309 ADAS_IDB_ControlReq "APA want to control ESC";
CM_ BO_ 340 "EPS_0x154";
CM_ SG_ 340 EPS_154_CheckSum "CheckSum";
CM_ SG_ 340 EPS_154_AliveCounter "AliveCounter";
CM_ SG_ 340 EPS_SteerPrsnlMod "Steer Personal Mode";
CM_ SG_ 340 EPS_ModChgEna "Mode Change Enable";
CM_ SG_ 340 SECCAN_EPS_154 "Seed generated from Secure CAN algorithm";
CM_ SG_ 373 ANRC_ESCRequest_Checksum "Checksum.";
CM_ SG_ 373 ANRC_ESCRequest_Alive "Alive Counter.";
CM_ SG_ 373 ADAS_PrkgDstToStop "Stopdistance request.";
CM_ SG_ 373 ADAS_PrkgMaxSpdReq "Target speed request.";
CM_ BO_ 376 "YSS_LongAcc";
CM_ SG_ 376 CHKSM_YSS_LongAcc "Checksum";
CM_ SG_ 376 ALV_YSS_LongAcc "Alive Counter";
CM_ SG_ 376 YSS_LONG_ACCUNFILTERED_QUAL "This signal contains the physical value of the Longitudinal acceleration with 0.002m/s2 LSB.";
CM_ SG_ 376 YSS_LONG_ACC_UNFILTERED "This signal contains the physical value of the Longitudinal acceleration with 0.002m/s2 LSB.";
CM_ SG_ 376 YSS_LONG_ACC_QUAL "This signal contains the qualifier of the Longitudinal acceleration.";
CM_ SG_ 376 YSS_LONG_ACC "This signal contains the physical value of the Longitudinal acceleration with 0.002m/s2 LSB.";
CM_ BO_ 377 "YSS_LateralAcc";
CM_ SG_ 377 CHKSM_YSS_LateralAcc "Checksum";
CM_ SG_ 377 ALV_YSS_LateralAcc "Alive Counter";
CM_ SG_ 377 YSS_LAT_ACCUNFILTERED_QUAL "This signal contains the qualifier of the Lateral acceleration.";
CM_ SG_ 377 YSS_LAT_ACC_UNFILTERED "This signal contains the physical value of the Lateral acceleration with 0.002m/s2 LSB.";
CM_ SG_ 377 YSS_LAT_ACC_QUAL "This signal contains the qualifier of the Lateral acceleration.";
CM_ SG_ 377 YSS_LAT_ACC "This signal contains the physical value of the Lateral acceleration with 0.002m/s2 LSB.";
CM_ BO_ 381 "YSS_YawRate";
CM_ SG_ 381 CHKSM_YSS_YawRate "Checksum";
CM_ SG_ 381 ALV_YSS_YawRate "Alive Counter";
CM_ SG_ 381 YSS_YAW_RATEUNFILTERED_QUAL "This signal contains the qualifier of the Yaw rate. ";
CM_ SG_ 381 YSS_YAW_RATE_UNFILTERED "This signal contains the physical value of the Yaw rate with 0.005°/s LSB.";
CM_ SG_ 381 YSS_YAW_RATE_QUAL "This signal contains the qualifier of the Yaw rate. ";
CM_ SG_ 381 YSS_SC_STATUS "This signal contains the state information for the SC. Each state has different priority, therefore the SC can have only one state at the same time.";
CM_ SG_ 381 YSS_YAW_RATE "This signal contains the physical value of the Yaw rate with 0.005°/s LSB. Table 2 contains some hexadecimal values with special meaning (e.g. initialization). The Yaw rate signal can have values from -163.830°/s (0x0000) to +163.830°/s (0xFFFC). The 0°/s value is assigned to (0x7FFE).";
CM_ SG_ 381 YSS_TEMPERATURE "This signal contains the physical value of the Temperature with 1°C LSB. Table 2 contains hexadecimal values with special meaning (e.g. initialization). The TEMPERATURE signal has no separate qualifier signal.";
CM_ BO_ 382 "Steering angle sensor";
CM_ SG_ 382 CHKSM_SAS_Sensor "Checksum";
CM_ SG_ 382 ALV_SAS_Sensor "Alive Counter";
CM_ SG_ 382 SAS_SASStsSnsr "The flag of  SAS status Punch Steering angle status";
CM_ SG_ 382 SAS_SteerWhlRotSpd "The current rotation speed of the steering wheel.";
CM_ SG_ 382 SAS_SteerWhlRotSpdStatus "The status of SteerWheelRotSpd";
CM_ SG_ 382 SAS_SASFailure "Angle sensor disabled.";
CM_ SG_ 382 SAS_Calibrated "SAS calibration state";
CM_ SG_ 382 SAS_SteerWheelAngleValid "Effective signal for steering angle";
CM_ SG_ 382 SAS_SteerWheelAngle "The current angle of the steering wheel(Positive, to left; Negative, to right)";
CM_ BO_ 383 "EPS ADAS TOI";
CM_ SG_ 383 EPS_ADAS_function_feed_2 "EPS_ADAS_function_feed";
CM_ SG_ 383 EPS_ADAS_function_feed "feedback of EPS on function activation";
CM_ SG_ 383 SECCAN_EPS_ADAS_TOI "Seed generated from Secure CAN algorithm";
CM_ BO_ 504 "MCU OutPut FR";
CM_ SG_ 504 CHKSM_EDS_OutPut_FR "Check sum";
CM_ SG_ 504 ALV_EDS_OutPut_FR "Alive Counter";
CM_ SG_ 504 EDS_Work_STS_FR "EDS Work status ";
CM_ SG_ 504 EDS_Spd_FR "Current motor speed";
CM_ SG_ 504 EDS_output_trqValid_FR "Indicate the valid flag of current motor torque";
CM_ SG_ 504 EDS_MotorDriveSts_FR "The drive state of EDS";
CM_ SG_ 504 EDS_powoff_req_FR "If there is a serious failure in the running process of EDS, the high voltage of VCU will be requested ";
CM_ SG_ 504 EDS_SpdValid_FR "Indicate the valid flag of current motor speed";
CM_ SG_ 504 EDS_output_trq_FR "Actual output torque of current EDS";
CM_ SG_ 504 EDS_VCU_6SO_flag_FWD "Indicate the valid flag of current front motor 6SO possible";
CM_ BO_ 505 "MCU OutPut RR";
CM_ SG_ 505 CHKSM_EDS_OutPut_RR "Check sum";
CM_ SG_ 505 ALV_EDS_OutPut_RR "Alive Counter";
CM_ SG_ 505 EDS_Work_STS_RR "Rear EDS Work status ";
CM_ SG_ 505 EDS_Spd_RR "current rear motor speed";
CM_ SG_ 505 EDS_output_trqValid_RR "Indicate the valid flag of current rear motor torque";
CM_ SG_ 505 EDS_MotorDriveSts_RR "The drive state of rear EDS";
CM_ SG_ 505 EDS_powoff_req_RR " If there is a serious failure in the running process of rear EDS, the high voltage of VCU will be requested ";
CM_ SG_ 505 EDS_SpdValid_RR "Indicate the valid flag of current rear motor speed";
CM_ SG_ 505 EDS_output_trq_RR "Actual output torque of current Rear motor ";
CM_ SG_ 505 EDS_VCU_6SO_flag_RWD "Indicate the valid flag of current rear motor 6SO possible";
CM_ SG_ 521 CRC_PAS_VCU_Status "Checksum.";
CM_ SG_ 521 Alive_PAS_VCU_Status "Alive Counter.";
CM_ SG_ 521 PAS_VCU_GearReq "APA Gear Position Request.";
CM_ SG_ 521 PAS_VCU_ControlReq "APA to VCU Handshake Request.";
CM_ SG_ 521 SECCAN_PAS_VCU_Status "Seed generated from Secure CAN algorithm.";
CM_ SG_ 521 PAS_VCU_FuncMode "APA request VCU carry out function mode.";
CM_ SG_ 521 PAS_VCU_State "APA Status.";
CM_ BO_ 524 "IC ODO";
CM_ SG_ 524 CHKSM_IC_ODO "Checksum";
CM_ SG_ 524 ALIV_IC_ODO "Alive Counter";
CM_ SG_ 524 MHU_Odometer_IC "Odometer information.";
CM_ BO_ 525 "IDB status";
CM_ SG_ 525 CHKSM_IDB_STATUS "Checksum";
CM_ SG_ 525 ALV_IDB_STATUS "Alive counter";
CM_ SG_ 525 ESPTransRequestType "ESP Request Type";
CM_ SG_ 525 ABSFault "ABS Fault Status";
CM_ SG_ 525 ABSActive "Further details when which bit will be set are defined within attached Excel file: Functions_Interventions File is at the moment under review at Bosch IDB side";
CM_ SG_ 525 VehicleSpd "Vehicle Speed";
CM_ SG_ 525 ESC_VehicleStandstill "Vehicle stationary detected";
CM_ SG_ 525 MCPressureSts "Main Cilinder Pressure Status";
CM_ SG_ 525 VehicleSpdSts "Vehicle Speed Status";
CM_ SG_ 525 MCPressure "MC Pressure";
CM_ SG_ 525 ESC_Braking_effort "Status of braking effort on wheel (used to know when the ESC need to apply a brake effort to ensure the deceleration)";
CM_ SG_ 525 BRAKE_LightonRequestEPBi "Brake lights on equested by EPBi";
CM_ SG_ 525 VDCActive "Vehicle dynamic control activation";
CM_ SG_ 525 TCSActive "Traction control system activation";
CM_ SG_ 525 TCSAvailable "Traction control system available";
CM_ SG_ 525 IDBActive "IDB activation";
CM_ SG_ 525 IDBFault "IDB fault ";
CM_ SG_ 525 ESC_VehicleHoldStat "Set if vehicle stationary for ACC is detected";
CM_ SG_ 525 IDB_Power_Stage "interchange prevention signal ";
CM_ SG_ 525 ESC_BrakeReleasedFailsafe "ESC has detected a skidding away and as a consequence is releasing the brakes. Driver is to be informed to take control over.";
CM_ BO_ 528 "RCU status";
CM_ SG_ 528 CHKSM_RCU_Status "Checksum";
CM_ SG_ 528 ALV_RCU_Status "Alive Counter";
CM_ SG_ 528 RCU_DAA_NoOpDoorOpen_1 "Drive Away Assist doesn't work due to Driver door?s open)";
CM_ SG_ 528 RCU_EPBParkingStatus "Electric Parking Brake Applied/Released";
CM_ SG_ 528 EPB_Swch_Mafnc "EPB switch is malfunction or brakes are incoherent";
CM_ SG_ 528 RCU_ParkBrkApplied_1 "Parking Brake applied";
CM_ SG_ 528 RCU_ReleaseEPB_Wo_PressBrk_1 "Driver Try to release EPB without press brake pedal. Alert driver press brake pedal to release EPB";
CM_ SG_ 528 RCU_BrkForceNotEnough_1 "Brake force not enough warning, Demand clamp force not achieved";
CM_ SG_ 528 RCU_ParkOnSteepInclination_1 "Vehicle parks on a steep inclination warning";
CM_ SG_ 528 RCU_ECD_RWU_active_1 "ECD/RWU active";
CM_ SG_ 528 RCU_EHandBrk_fault_1 "Park brake fault";
CM_ SG_ 528 RCU_BRAKE_LightonRequestEPBi "Brake lights on equested by EPBi";
CM_ BO_ 529 "Post_Collision_Brake";
CM_ SG_ 529 PcbCtrlFail "Post Collision Brake Control Failure";
CM_ SG_ 529 PcbActiveFlg "ESC PCB control activation";
CM_ BO_ 530 "Reference Values for RCU from IDB";
CM_ SG_ 530 IDB_VehicleSpeed "Estimated Reference Vehicle Speed";
CM_ SG_ 530 IDB_AxOffsetComp "Offset compensated longitudinal acceleration";
CM_ SG_ 530 IDB_BLSInvalidSts "BLS plausibiliy monitoring results from IDB.";
CM_ SG_ 530 IDB_AxInvalidSts "Longitudinal G plausibiliy monitoring results from IDB.";
CM_ SG_ 530 IDB_AxOffsetCompSts "Offset compensated longitudinal acceleration status";
CM_ BO_ 532 "VCU_ADAS_ACC_status";
CM_ SG_ 532 CRC_VCU_ADAS "Checksum";
CM_ SG_ 532 ALIV_VCU_ADAS "Alive counter";
CM_ SG_ 532 VCU_ADAS_ControledRes "VCU Handshake Request Feedback ";
CM_ SG_ 532 VCU_ADAS_Available "VCU Availability for APA Control ";
CM_ SG_ 532 VCU_ADAS_FuncMode "VCU & APA Function Mode";
CM_ SG_ 532 VCU_ADAS_CtrlAbortFeedback "VCU Active Abort Feedback ";
CM_ BO_ 570 "IDB Front Wheel Status";
CM_ SG_ 570 IDB_WheelDirection_FR "IDB Front Right Wheel Direction";
CM_ SG_ 570 IDB_WheelDirection_FL "IDB Front Left Wheel Direction";
CM_ SG_ 570 IDB_WheelSpeedRC_FL "IDB Front Left Wheel Speed Pulse";
CM_ SG_ 570 IDB_WheelSpeedRC_FR "IDB Front Right Wheel Speed Pulse";
CM_ SG_ 570 SECCAN_IDB_WheelSts_FR "Seed portion from Secure CAN algorithm.";
CM_ BO_ 571 "IDB Rear Wheel Status";
CM_ SG_ 571 IDB_WheelDirection_RR "IDB Rear Right Wheel Direction";
CM_ SG_ 571 IDB_WheelDirection_RL "IDB Rear Left Wheel Direction";
CM_ SG_ 571 IDB_WheelSpeedRC_RL "IDB Rear Left Wheel Speed Pulse";
CM_ SG_ 571 IDB_WheelSpeedRC_RR "IDB Rear Right Wheel Speed Pulse";
CM_ SG_ 571 SECCAN_IDB_WheelSts_RR "Seed portion from Secure CAN algorithm.";
CM_ BO_ 596 "Wheel Speed Rear";
CM_ SG_ 596 CRC_AVL_RPM_WHL_REAR "Checksum";
CM_ SG_ 596 ALIV_AVL_RPM_WHL_REAR "Alive Counter";
CM_ SG_ 596 AVL_RPM_WHL_RLH "Measured speed of the rear left single wheel.";
CM_ SG_ 596 AVL_RPM_WHL_RRH "Measured speed of the rear right single wheel.";
CM_ SG_ 596 QU_AVL_RPM_WHL_RLH "status qualifier to signal actual-value_RPM_wheel_HL.";
CM_ SG_ 596 QU_AVL_RPM_WHL_RRH "status qualifier to signal actual-value_RPM_wheel_HR.";
CM_ BO_ 597 "Wheel Speed Front";
CM_ SG_ 597 CRC_AVL_RPM_WHL_FRONT "Checksum";
CM_ SG_ 597 ALIV_AVL_RPM_WHL_FRONT "Alive Counter";
CM_ SG_ 597 AVL_RPM_WHL_FLH "Measured speed of the front left single wheel.";
CM_ SG_ 597 AVL_RPM_WHL_FRH "Measured speed of the front right single wheel.";
CM_ SG_ 597 QU_AVL_RPM_WHL_FLH "status qualifier to signal actual-value_RPM_wheel_VL.";
CM_ SG_ 597 QU_AVL_RPM_WHL_FRH "status qualifier to signal actual-value_RPM_wheel_VL.";
CM_ BO_ 617 "High voltage status";
CM_ SG_ 617 CHKSM_VCU_HV_Status "Checksum";
CM_ SG_ 617 ALV_VCU_HV_Status "Alive Counter";
CM_ SG_ 617 VCU_VehicleHVStatus "Vehicle High voltage Ready State";
CM_ BO_ 649 "Acc Long Lat yaw";
CM_ SG_ 649 CHKSM_IDB_ZF2 "Checksum";
CM_ SG_ 649 ALIVE_IDB_ZF2 "Alive counter";
CM_ SG_ 649 AxOutStatus "Longitudinal acceleration status";
CM_ SG_ 649 QU_VYAW_VEH "Qualifier yaw velocity vehicle. All not defined values are reserved.";
CM_ SG_ 649 AyOutStatus "Lateral acceleration status";
CM_ SG_ 649 AcceleratorY "Lateral acceleration";
CM_ SG_ 649 AcceleratorX "Longitudinal acceleration";
CM_ SG_ 649 VYAW_VEH "Yaw velocity vehicle";
CM_ BO_ 714 "Tester control BMS";
CM_ SG_ 714 CHKSM_IC_SENSOR "Checksum";
CM_ SG_ 714 ALV_IC_SENSOR "Alive Counter";
CM_ SG_ 714 MHU_STAT_AmbientTempRaw "Ambient Temperature Raw";
CM_ SG_ 714 MHU_STAT_FuelLevel "Fuel Level 3 to 63 l  (only for ICE)";
CM_ SG_ 714 MHU_STAT_AmbientTemp "Ambient Temperature filtered";
CM_ SG_ 714 MHU_STAT_CoolantLevelStatus "Low level coolant indicator";
CM_ BO_ 760 "MHU Date Time";
CM_ SG_ 760 DISP_HR "The signal / parameter indicates the current hour.";
CM_ SG_ 760 DISP_MN "The signal / parameter indicates the current minute.";
CM_ SG_ 760 DISP_SEC "The signal / parameter indicates the current second.";
CM_ SG_ 760 DISP_DATE_DAY "The signal / parameter indicates the current day.";
CM_ SG_ 760 DISP_DATE_MON "The signal / parameter indicates the current month.";
CM_ SG_ 760 DISP_DATE_WDAY "The signal   parameter indicates the current day of the week.";
CM_ SG_ 760 DISP_DATE_YR "The signal / parameter indicates the current year.";
CM_ SG_ 760 ST_DISP_CTI_DATE "The signal / parameter indicates the state of the switch summer winter time.";
CM_ BO_ 770 "CCU temprature and pressure";
CM_ SG_ 770 CHKSM_CCU_TEMP_PRESSURE "Checksum";
CM_ SG_ 770 ALV_CCU_TEMP_PRESSURE "Alive Counter";
CM_ SG_ 770 CCU_Pressure_AC "The compressor line pressure.";
CM_ SG_ 770 CCU_InteriorTemp "CCU interiour  temperature. Invalid = 251-255";
CM_ SG_ 770 CCU_TempEx_AC "Outside temperature calculated by CCU";
CM_ SG_ 770 CCU_EvaporatorTemp "Actual evaporator temperature of the HVAC unit. Invalid = 251-255";
CM_ BO_ 796 "EPS SteeringHoldState";
CM_ SG_ 796 CHKSM_EPS_SteeringHoldState "Checksum.";
CM_ SG_ 796 ALV_EPS_SteeringHoldState "Alive Counter.";
CM_ SG_ 796 EPS_ADAS_FuncMode "EPS & APA Function Mode";
CM_ SG_ 796 EPS_Drive_Intervention "The driver handle the Steering";
CM_ SG_ 796 EPS_ADAS_StrAngRes "EPS Response to APA";
CM_ SG_ 796 EPS_ADAS_ControlAvailable "EPS Status on FAPA Control Availability";
CM_ SG_ 796 EPS_TorqueLimitationState "Torque limitation state";
CM_ SG_ 796 EPS_ADAS_CtrlAbortFeedback "EPS Active Disengagement Reason";
CM_ BO_ 813 "ADAS_ACC_Status";
CM_ SG_ 813 CRC_ACC_STATUS "Checksum";
CM_ SG_ 813 Alive_ACC_STATUS "Alive Counter";
CM_ SG_ 813 ADAS_ACC_Information "ACC Fail Information in ADAS side";
CM_ SG_ 813 ADAS_ACC_Main_Mode "Main switch status of ACC";
CM_ SG_ 813 ADAS_ACC_AccelDecel_Cmd "Target Acceleration/Deceleration of ACC";
CM_ SG_ 813 ADAS_ACC_StandstillReq "Standstill request flag (it is only for ACC)";
CM_ SG_ 813 ADAS_ACC_Mode "ACC control state";
CM_ SG_ 813 ADAS_ACC_IDB_DecCmdAct "Flag which indicates that the deceleration command from ADAS is valid or not";
CM_ SG_ 813 SECCAN_ADAS_ACC_Status "Secret portion from Secure CAN algorithm";
CM_ BO_ 814 "ADAS_AEB_Status";
CM_ SG_ 814 CRC_AEB_STATUS "Checksum";
CM_ SG_ 814 Alive_AEB_STATUS "Alive Counter";
CM_ SG_ 814 ADAS_AEB_Prefill "Request to activate Pre-fill function";
CM_ SG_ 814 ADAS_AEB_HBA_Level "Request to activate HBA (Hydraulic Boost Assist) function.";
CM_ SG_ 814 ADAS_AEB_Target_Deceleration "Deceleration command value of Pre, Full-Brake function";
CM_ SG_ 814 ADAS_AEB_HBA_Req "Request to activate HBA (Hydraulic Boost Assist) function.";
CM_ SG_ 814 ADAS_AEB_Braking_Progress "Request to activate Brake";
CM_ SG_ 814 ADAS_AEB_Hold "Request flag for vehicle stop";
CM_ SG_ 814 FCAM_AEB_DBS_Active "Indicate the DBS function activation";
CM_ BO_ 815 "IDB_Info_Flag";
CM_ SG_ 815 CHKSM_IDB_Info_Flag "Checksum";
CM_ SG_ 815 ALV_IDB_Info_Flag "Alive counter";
CM_ SG_ 815 IDB_ACC_Available_Flag "ACC available or not";
CM_ SG_ 815 IDB_ACC_Deceleration_Flag "Deceleration flag for ACC";
CM_ SG_ 815 IDB_ACC_Acceleration_Flag "Acceleration flag for ACC";
CM_ SG_ 815 IDB_RAEB_Active_Flag "RAEB active or not";
CM_ SG_ 815 IDB_RAEB_Available_Flag "RAEB available or not";
CM_ SG_ 815 IDB_AEB_Active_Flag "AEB active or not";
CM_ SG_ 815 IDB_AEB_Available_Flag "AEB available or not";
CM_ SG_ 815 IDB_ACC_DriverOverride "Information of Driver pedal override.";
CM_ SG_ 815 SECCAN_IDB_Info_Flag "Secret portion from Secure CAN algorithm";
CM_ BO_ 816 "ADAS_RAEB_Status";
CM_ SG_ 816 ADAS_RAEB_Checksum "Checksum";
CM_ SG_ 816 ADAS_RAEB_Alive "Alive Counter";
CM_ SG_ 816 ADAS_EPS_StrConReq "ADAS_EPS steering Control Request";
CM_ SG_ 816 ADAS_EPS_Status "ADAS_Status";
CM_ SG_ 816 ADAS_EPS_FuncMode "APA request EPS carry out function mode";
CM_ SG_ 816 ADAS_EPSAngleReq "APA request EPS to change angle (left?+?,right?-? )";
CM_ SG_ 816 SECCAN_ADAS_RAEB_Status " ";
CM_ BO_ 817 "IC_MILEAGE";
CM_ SG_ 817 MILE_KM "Mileage information";
CM_ SG_ 817 FLLV_FUTA "The fuel level of  tank. 255 value invalid";
CM_ SG_ 817 RNG "Calculated range of IPC";
CM_ SG_ 817 ST_FLLV_FUTA_SPAR "State of the tank reserve indicator";
CM_ BO_ 890 "Steering Angle Request for ADAS lateral control features";
CM_ SG_ 890 CHKSM_ADAS_EPS_LATE_CON "Checksum";
CM_ SG_ 890 ALV_ADAS_EPS_LATE_CON "Alive Counter";
CM_ SG_ 890 ADAS_EPS_StrWhe_TOLAct "Active TOL request for torque overlay control";
CM_ SG_ 890 ADAS_EPS_StrWhe_AOLAct "Active AOL request for Angle overlay control";
CM_ SG_ 890 ADAS_EPS_AOLReq "Steering Angle Request for ADAS lateral control features";
CM_ SG_ 890 ADAS_EPS_Torq_Fact_Req "ADAS_EPS_Torq_Fact_Req";
CM_ SG_ 890 SECCAN_ADAS_EPS_LATE_CON "Seed generated from Secure CAN algorithm";
CM_ BO_ 891 "Status from EPS to ADAS";
CM_ SG_ 891 EPS_SteeringEMTorque "Steering motor torque (Positive, to left; Negative, to right)";
CM_ SG_ 891 EPS_ADAS_AOLAct "AngleOverLay Activation/Deactivation";
CM_ SG_ 891 EPS_SteeringDriverTorque "Steering driver torque (Positive, to left; Negative, to right)";
CM_ SG_ 891 SECCAN_EPS_ADAS_Steering_Trq "Seed generated from Secure CAN algorithm";
CM_ BO_ 894 "EPS advanced information";
CM_ SG_ 894 CHKSM_EPS_Advanced "Checksum";
CM_ SG_ 894 ALV_EPS_Advanced "Alive Counter";
CM_ SG_ 894 EPS_TorqSensorSts "Validation bit of torsion bar torque";
CM_ SG_ 894 EPS_SteeringTorque "Steering torque (Positive, to left; Negative, to right)";
CM_ SG_ 894 EPS_SteeringTorqueValid "validity of steering torque";
CM_ SG_ 894 EPS_Mode "Electric steering mode ";
CM_ SG_ 894 EPS_Steering_angle_spd "EPS_Steering_angle_spd";
CM_ SG_ 894 EPSAngRespSts "Electric steering mode";
CM_ SG_ 894 EPS_Steering_angle "EPS steering wheel ange (Positive, to left; Negative, to right)";
BA_DEF_ BO_  "GenMsgSendType" ENUM  "Cyclic","NotUsed","NotUsed","NotUsed","NotUsed","NotUsed","NotUsed","IfActive","NoMsgSendType","NotUsed";
BA_DEF_ BO_  "GenMsgILSupport" ENUM  "No","Yes";
BA_DEF_ BO_  "DiagResponse" ENUM  "No","Yes";
BA_DEF_ BO_  "DiagRequest" ENUM  "No","Yes";
BA_DEF_ BO_  "NmAsrMessage" ENUM  "No","Yes";
BA_DEF_ BO_  "DiagState" ENUM  "No","Yes";
BA_DEF_ BO_  "DiagUudtResponse" ENUM  "False","True";
BA_DEF_ BO_  "GenMsgStartDelayTime" INT 0 65535;
BA_DEF_ BO_  "GenMsgDelayTime" INT 0 0;
BA_DEF_ BO_  "GenMsgNrOfRepetition" INT 0 0;
BA_DEF_ BO_  "GenMsgCycleTimeFast" INT 0 0;
BA_DEF_ BO_  "GenMsgCycleTime" INT 0 0;
BA_DEF_ BU_  "NmStationAddress" HEX 0 0;
BA_DEF_ BU_  "Address" HEX 0 255;
BA_DEF_ BU_  "TpSTMin" INT 0 255;
BA_DEF_ BU_  "ILUsed" ENUM  "No","Yes";
BA_DEF_ BU_  "NmAsrNode" ENUM  "No","Yes";
BA_DEF_ BU_  "NmAsrNodeIdentifier" HEX 0 255;
BA_DEF_ BU_  "NmAsrCanMsgCycleOffset" INT 0 65535;
BA_DEF_ BU_  "NmAsrCanMsgReducedTime" INT 320 640;
BA_DEF_ SG_  "GenSigSendType" ENUM  "Cyclic","OnWrite","OnWriteWithRepetition","OnChange","OnChangeWithRepetition","IfActive","IfActiveWithRepetition","NoSigSendType","NotUsed","NotUsed","NotUsed","NotUsed","NotUsed";
BA_DEF_ SG_  "InvalidValue" STRING ;
BA_DEF_ SG_  "GenSigStartValue" INT 0 0;
BA_DEF_ SG_  "GenSigTimeoutTime_ALL" INT 0 65535;
BA_DEF_  "DBName" STRING ;
BA_DEF_  "NmAsrBaseAddress" HEX 0 2047;
BA_DEF_  "NmAsrMessageCount" INT 1 256;
BA_DEF_  "NmAsrTimeoutTime" INT 0 65535;
BA_DEF_  "NmAsrWaitBusSleepTime" INT 0 65535;
BA_DEF_  "NmAsrRepeatMessageTime" INT 0 65535;
BA_DEF_  "NmAsrCanMsgCycleTime" INT 0 65535;
BA_DEF_  "Baudrate" INT 0 1000000;
BA_DEF_  "BusType" STRING ;
BA_DEF_  "NmType" STRING ;
BA_DEF_  "Manufacturer" STRING ;
BA_DEF_ BU_  "ECU" STRING ;
BA_DEF_DEF_  "GenMsgSendType" "NoMsgSendType";
BA_DEF_DEF_  "GenMsgILSupport" "Yes";
BA_DEF_DEF_  "DiagResponse" "No";
BA_DEF_DEF_  "DiagRequest" "No";
BA_DEF_DEF_  "NmAsrMessage" "No";
BA_DEF_DEF_  "DiagState" "No";
BA_DEF_DEF_  "DiagUudtResponse" "False";
BA_DEF_DEF_  "GenMsgStartDelayTime" 0;
BA_DEF_DEF_  "GenMsgDelayTime" 0;
BA_DEF_DEF_  "GenMsgNrOfRepetition" 0;
BA_DEF_DEF_  "GenMsgCycleTimeFast" 0;
BA_DEF_DEF_  "GenMsgCycleTime" 0;
BA_DEF_DEF_  "NmStationAddress" 0;
BA_DEF_DEF_  "Address" 0;
BA_DEF_DEF_  "TpSTMin" 20;
BA_DEF_DEF_  "ILUsed" "Yes";
BA_DEF_DEF_  "NmAsrNode" "Yes";
BA_DEF_DEF_  "NmAsrNodeIdentifier" 0;
BA_DEF_DEF_  "NmAsrCanMsgCycleOffset" 0;
BA_DEF_DEF_  "NmAsrCanMsgReducedTime" 320;
BA_DEF_DEF_  "GenSigSendType" "Cyclic";
BA_DEF_DEF_  "InvalidValue" "";
BA_DEF_DEF_  "GenSigStartValue" 0;
BA_DEF_DEF_  "GenSigTimeoutTime_ALL" 0;
BA_DEF_DEF_  "DBName" "";
BA_DEF_DEF_  "NmAsrBaseAddress" 1280;
BA_DEF_DEF_  "NmAsrMessageCount" 128;
BA_DEF_DEF_  "NmAsrTimeoutTime" 2000;
BA_DEF_DEF_  "NmAsrWaitBusSleepTime" 1500;
BA_DEF_DEF_  "NmAsrRepeatMessageTime" 3200;
BA_DEF_DEF_  "NmAsrCanMsgCycleTime" 640;
BA_DEF_DEF_  "Baudrate" 500000;
BA_DEF_DEF_  "BusType" "";
BA_DEF_DEF_  "NmType" "";
BA_DEF_DEF_  "Manufacturer" "VinFast";
BA_DEF_DEF_  "ECU" "";
BA_ "NmType" "NmAsr";
BA_ "BusType" "CAN";
BA_ "DBName" "Chassis";
BA_ "NmStationAddress" BU_ AVAS 42;
BA_ "NmAsrNodeIdentifier" BU_ AVAS 42;
BA_ "NmAsrCanMsgReducedTime" BU_ AVAS 425;
BA_ "NmAsrCanMsgCycleOffset" BU_ AVAS 210;
BA_ "ECU" BU_ AVAS "AVAS";
BA_ "Address" BU_ AVAS 42;
BA_ "NmStationAddress" BU_ EPS 40;
BA_ "NmAsrNodeIdentifier" BU_ EPS 40;
BA_ "NmAsrCanMsgReducedTime" BU_ EPS 420;
BA_ "NmAsrCanMsgCycleOffset" BU_ EPS 200;
BA_ "ECU" BU_ EPS "EPS_ChassisCAN";
BA_ "Address" BU_ EPS 40;
BA_ "NmStationAddress" BU_ FCAM_Chassis 22;
BA_ "NmAsrNodeIdentifier" BU_ FCAM_Chassis 22;
BA_ "ECU" BU_ FCAM_Chassis "FCAM_ChassisCAN";
BA_ "Address" BU_ FCAM_Chassis 22;
BA_ "NmAsrCanMsgCycleOffset" BU_ FCAM_Chassis 110;
BA_ "NmStationAddress" BU_ IDB_Chassis 41;
BA_ "NmAsrNodeIdentifier" BU_ IDB_Chassis 41;
BA_ "NmAsrCanMsgCycleOffset" BU_ IDB_Chassis 205;
BA_ "ECU" BU_ IDB_Chassis "IDB_ChassisCAN";
BA_ "Address" BU_ IDB_Chassis 41;
BA_ "NmStationAddress" BU_ PAS_Chassis 23;
BA_ "Address" BU_ PAS_Chassis 23;
BA_ "NmAsrNodeIdentifier" BU_ PAS_Chassis 23;
BA_ "ECU" BU_ PAS_Chassis "PAS_ChassisCAN";
BA_ "NmAsrCanMsgCycleOffset" BU_ PAS_Chassis 115;
BA_ "NmStationAddress" BU_ RCU_Chassis 39;
BA_ "NmAsrNodeIdentifier" BU_ RCU_Chassis 39;
BA_ "NmAsrCanMsgCycleOffset" BU_ RCU_Chassis 195;
BA_ "ECU" BU_ RCU_Chassis "RCU";
BA_ "Address" BU_ RCU_Chassis 39;
BA_ "NmStationAddress" BU_ VCU_Chassis 44;
BA_ "NmAsrNodeIdentifier" BU_ VCU_Chassis 44;
BA_ "NmAsrCanMsgReducedTime" BU_ VCU_Chassis 430;
BA_ "NmAsrCanMsgCycleOffset" BU_ VCU_Chassis 220;
BA_ "ECU" BU_ VCU_Chassis "VCU_Chassis";
BA_ "Address" BU_ VCU_Chassis 44;
BA_ "NmStationAddress" BU_ XGW_Chassis 2;
BA_ "NmAsrNodeIdentifier" BU_ XGW_Chassis 2;
BA_ "NmAsrCanMsgReducedTime" BU_ XGW_Chassis 325;
BA_ "NmAsrCanMsgCycleOffset" BU_ XGW_Chassis 10;
BA_ "ECU" BU_ XGW_Chassis "XGW_ChassisCAN";
BA_ "Address" BU_ XGW_Chassis 2;
BA_ "NmStationAddress" BU_ YSS 15;
BA_ "NmAsrNodeIdentifier" BU_ YSS 15;
BA_ "NmAsrCanMsgCycleOffset" BU_ YSS 75;
BA_ "ECU" BU_ YSS "YSS";
BA_ "Address" BU_ YSS 15;
BA_ "GenMsgCycleTime" BO_ 198 20;
BA_ "GenMsgSendType" BO_ 198 0;
BA_ "GenMsgSendType" BO_ 200 0;
BA_ "GenMsgCycleTime" BO_ 200 100;
BA_ "GenMsgSendType" BO_ 241 0;
BA_ "GenMsgCycleTime" BO_ 241 20;
BA_ "GenMsgSendType" BO_ 244 0;
BA_ "GenMsgCycleTime" BO_ 244 10;
BA_ "GenMsgSendType" BO_ 245 0;
BA_ "GenMsgCycleTime" BO_ 245 10;
BA_ "GenMsgCycleTime" BO_ 257 100;
BA_ "GenMsgSendType" BO_ 257 0;
BA_ "GenMsgSendType" BO_ 258 0;
BA_ "GenMsgCycleTime" BO_ 258 40;
BA_ "GenMsgSendType" BO_ 263 0;
BA_ "GenMsgCycleTime" BO_ 263 100;
BA_ "GenMsgSendType" BO_ 266 0;
BA_ "GenMsgCycleTime" BO_ 266 500;
BA_ "GenMsgSendType" BO_ 274 0;
BA_ "GenMsgNrOfRepetition" BO_ 274 3;
BA_ "GenMsgCycleTimeFast" BO_ 274 20;
BA_ "GenMsgCycleTime" BO_ 274 100;
BA_ "GenMsgSendType" BO_ 275 0;
BA_ "GenMsgCycleTime" BO_ 275 10;
BA_ "GenMsgSendType" BO_ 305 0;
BA_ "GenMsgCycleTime" BO_ 305 20;
BA_ "GenMsgSendType" BO_ 306 0;
BA_ "GenMsgCycleTime" BO_ 306 20;
BA_ "GenMsgSendType" BO_ 309 0;
BA_ "GenMsgCycleTime" BO_ 309 20;
BA_ "GenMsgSendType" BO_ 340 0;
BA_ "GenMsgCycleTime" BO_ 340 40;
BA_ "GenMsgCycleTime" BO_ 373 20;
BA_ "GenMsgSendType" BO_ 373 0;
BA_ "GenMsgSendType" BO_ 376 0;
BA_ "GenMsgCycleTime" BO_ 376 10;
BA_ "GenMsgSendType" BO_ 377 0;
BA_ "GenMsgCycleTime" BO_ 377 10;
BA_ "GenMsgSendType" BO_ 381 0;
BA_ "GenMsgCycleTime" BO_ 381 10;
BA_ "GenMsgSendType" BO_ 382 0;
BA_ "GenMsgCycleTime" BO_ 382 10;
BA_ "GenMsgSendType" BO_ 383 0;
BA_ "GenMsgCycleTime" BO_ 383 20;
BA_ "GenMsgSendType" BO_ 504 0;
BA_ "GenMsgCycleTime" BO_ 504 20;
BA_ "GenMsgSendType" BO_ 505 0;
BA_ "GenMsgCycleTime" BO_ 505 20;
BA_ "GenMsgCycleTime" BO_ 521 20;
BA_ "GenMsgSendType" BO_ 521 0;
BA_ "GenMsgSendType" BO_ 524 0;
BA_ "GenMsgCycleTime" BO_ 524 100;
BA_ "GenMsgSendType" BO_ 525 0;
BA_ "GenMsgCycleTime" BO_ 525 20;
BA_ "GenMsgSendType" BO_ 528 0;
BA_ "GenMsgCycleTime" BO_ 528 40;
BA_ "GenMsgSendType" BO_ 529 0;
BA_ "GenMsgCycleTime" BO_ 529 20;
BA_ "GenMsgSendType" BO_ 530 0;
BA_ "GenMsgILSupport" BO_ 530 0;
BA_ "GenMsgCycleTime" BO_ 530 20;
BA_ "DiagState" BO_ 530 1;
BA_ "GenMsgSendType" BO_ 532 0;
BA_ "GenMsgCycleTime" BO_ 532 20;
BA_ "GenMsgSendType" BO_ 570 0;
BA_ "GenMsgCycleTime" BO_ 570 20;
BA_ "GenMsgSendType" BO_ 571 0;
BA_ "GenMsgCycleTime" BO_ 571 20;
BA_ "GenMsgSendType" BO_ 596 0;
BA_ "GenMsgCycleTime" BO_ 596 20;
BA_ "GenMsgSendType" BO_ 597 0;
BA_ "GenMsgCycleTime" BO_ 597 20;
BA_ "GenMsgSendType" BO_ 617 0;
BA_ "GenMsgCycleTime" BO_ 617 40;
BA_ "GenMsgSendType" BO_ 649 0;
BA_ "GenMsgCycleTime" BO_ 649 20;
BA_ "GenMsgSendType" BO_ 714 0;
BA_ "GenMsgCycleTime" BO_ 714 100;
BA_ "GenMsgSendType" BO_ 760 0;
BA_ "GenMsgCycleTime" BO_ 760 1000;
BA_ "GenMsgSendType" BO_ 770 0;
BA_ "GenMsgCycleTime" BO_ 770 1000;
BA_ "GenMsgSendType" BO_ 796 0;
BA_ "GenMsgCycleTime" BO_ 796 10;
BA_ "GenMsgSendType" BO_ 813 0;
BA_ "GenMsgCycleTime" BO_ 813 20;
BA_ "GenMsgSendType" BO_ 814 0;
BA_ "GenMsgCycleTime" BO_ 814 20;
BA_ "GenMsgSendType" BO_ 815 0;
BA_ "GenMsgCycleTime" BO_ 815 20;
BA_ "GenMsgSendType" BO_ 816 0;
BA_ "GenMsgCycleTime" BO_ 816 20;
BA_ "GenMsgSendType" BO_ 817 0;
BA_ "GenMsgCycleTime" BO_ 817 100;
BA_ "GenMsgSendType" BO_ 890 0;
BA_ "GenMsgCycleTime" BO_ 890 10;
BA_ "GenMsgSendType" BO_ 891 0;
BA_ "GenMsgCycleTime" BO_ 891 20;
BA_ "GenMsgSendType" BO_ 894 0;
BA_ "GenMsgCycleTime" BO_ 894 10;
BA_ "GenSigTimeoutTime_ALL" SG_ 198 CHKSM_IDB_ACCActive 200;
BA_ "InvalidValue" SG_ 198 ALV_IDB_ACCActive "Fh";
BA_ "GenSigTimeoutTime_ALL" SG_ 198 ALV_IDB_ACCActive 200;
BA_ "GenSigTimeoutTime_ALL" SG_ 198 ESC_ADAS_Active 200;
BA_ "GenSigTimeoutTime_ALL" SG_ 198 ESC_ADAS_FuncMode 200;
BA_ "GenSigTimeoutTime_ALL" SG_ 198 ESC_ADAS_CtrlAbortFeedback2 200;
BA_ "GenSigTimeoutTime_ALL" SG_ 198 ESC_ADAS_BrakeMode 200;
BA_ "GenSigTimeoutTime_ALL" SG_ 198 ESC_ADAS_Available 200;
BA_ "GenSigTimeoutTime_ALL" SG_ 198 ESC_PrefillSts 200;
BA_ "InvalidValue" SG_ 200 CHKSM_ESC_FUNCTION "-";
BA_ "GenSigTimeoutTime_ALL" SG_ 200 CHKSM_ESC_FUNCTION 500;
BA_ "InvalidValue" SG_ 200 ALV_ESC_FUNCTION "Fh";
BA_ "GenSigTimeoutTime_ALL" SG_ 200 ALV_ESC_FUNCTION 500;
BA_ "GenSigTimeoutTime_ALL" SG_ 200 AVH_ActiveStatus 500;
BA_ "GenSigTimeoutTime_ALL" SG_ 200 AVH_DispMSG 500;
BA_ "GenSigTimeoutTime_ALL" SG_ 200 AVH_LampReq 500;
BA_ "GenSigTimeoutTime_ALL" SG_ 241 CRC_RecuBrakeTorqueRequest 200;
BA_ "InvalidValue" SG_ 241 ALIV_RecuBrakeTorqueRequest "Fh";
BA_ "GenSigTimeoutTime_ALL" SG_ 241 ALIV_RecuBrakeTorqueRequest 200;
BA_ "GenSigTimeoutTime_ALL" SG_ 241 IDB_RecuBrakeTorqueRequest_FR 200;
BA_ "GenSigTimeoutTime_ALL" SG_ 241 IDB_RecuBrakeTorqueRequest_RR 200;
BA_ "GenSigTimeoutTime_ALL" SG_ 241 IDB_RecuBrakeControl_Sts 200;
BA_ "GenSigTimeoutTime_ALL" SG_ 241 IDB_RecuBrkTorqueReq_Sts 200;
BA_ "GenSigTimeoutTime_ALL" SG_ 241 IDB_Brake_Pedal_position 200;
BA_ "GenSigTimeoutTime_ALL" SG_ 241 IDB_Brake_Pedal_position_sts 200;
BA_ "GenSigTimeoutTime_ALL" SG_ 244 CRC_IDB_TorqueIncrease 100;
BA_ "InvalidValue" SG_ 244 ALIV_IDB_TorqueIncrease "Fh";
BA_ "GenSigTimeoutTime_ALL" SG_ 244 ALIV_IDB_TorqueIncrease 100;
BA_ "GenSigTimeoutTime_ALL" SG_ 244 IDB_TorqueIncrease_FR 100;
BA_ "GenSigTimeoutTime_ALL" SG_ 244 IDB_TorqueIncrease_Active_FR 100;
BA_ "GenSigTimeoutTime_ALL" SG_ 244 IDB_TorqueIncrease_RR 100;
BA_ "GenSigTimeoutTime_ALL" SG_ 244 IDB_TorqueIncrease_Active_RR 100;
BA_ "GenSigTimeoutTime_ALL" SG_ 244 SECCAN_IDB_TorqueIncrease 100;
BA_ "GenSigTimeoutTime_ALL" SG_ 245 CRC_IDB_TorqueControl 100;
BA_ "InvalidValue" SG_ 245 ALIV_IDB_TorqueControl "Fh";
BA_ "GenSigTimeoutTime_ALL" SG_ 245 ALIV_IDB_TorqueControl 100;
BA_ "GenSigTimeoutTime_ALL" SG_ 245 IDB_TorqueReduce_FR 100;
BA_ "GenSigTimeoutTime_ALL" SG_ 245 IDB_TorqueReduce_Active_FR 100;
BA_ "GenSigTimeoutTime_ALL" SG_ 245 IDB_TorqueReduce_RR 100;
BA_ "GenSigTimeoutTime_ALL" SG_ 245 IDB_TorqueReduce_Active_RR 100;
BA_ "GenSigTimeoutTime_ALL" SG_ 245 SECCAN_IDB_TorqueControl 100;
BA_ "GenSigTimeoutTime_ALL" SG_ 257 DrowsDistractionLvl 500;
BA_ "InvalidValue" SG_ 257 DrowsDistractionLvl "9h";
BA_ "GenSigTimeoutTime_ALL" SG_ 257 DriverAttentionWarn 500;
BA_ "InvalidValue" SG_ 257 DriverAttentionWarn "7h";
BA_ "GenSigTimeoutTime_ALL" SG_ 257 Haptic_Warning 500;
BA_ "InvalidValue" SG_ 257 Haptic_Warning "3h";
BA_ "GenSigTimeoutTime_ALL" SG_ 258 PDCU_102_CheckSum 400;
BA_ "InvalidValue" SG_ 258 PDCU_102_AliveCounter "Fh";
BA_ "GenSigTimeoutTime_ALL" SG_ 258 PDCU_102_AliveCounter 400;
BA_ "GenSigTimeoutTime_ALL" SG_ 258 PDCU_DrvModSig 400;
BA_ "GenSigTimeoutTime_ALL" SG_ 258 SECCAN_EPS_102 400;
BA_ "GenSigTimeoutTime_ALL" SG_ 263 CHKSM_BCM_CENTRAL_LOCK 500;
BA_ "InvalidValue" SG_ 263 ALV_BCM_CENTRAL_LOCK "Fh";
BA_ "GenSigTimeoutTime_ALL" SG_ 263 ALV_BCM_CENTRAL_LOCK 500;
BA_ "InvalidValue" SG_ 263 STAT_CDL_LED "3h";
BA_ "GenSigTimeoutTime_ALL" SG_ 263 STAT_CDL_LED 500;
BA_ "InvalidValue" SG_ 263 STAT_DoorUnlockFL "3h";
BA_ "GenSigTimeoutTime_ALL" SG_ 263 STAT_DoorUnlockFL 500;
BA_ "InvalidValue" SG_ 263 STAT_ATWS "7h";
BA_ "GenSigTimeoutTime_ALL" SG_ 263 STAT_ATWS 500;
BA_ "InvalidValue" SG_ 263 STAT_DoorLockFL "3h";
BA_ "GenSigTimeoutTime_ALL" SG_ 263 STAT_DoorLockFL 500;
BA_ "GenSigTimeoutTime_ALL" SG_ 266 CHKSM_BCM_VOLTAGE 2500;
BA_ "InvalidValue" SG_ 266 ALIVE_BCM_VOLTAGE "Fh";
BA_ "GenSigTimeoutTime_ALL" SG_ 266 ALIVE_BCM_VOLTAGE 2500;
BA_ "InvalidValue" SG_ 266 UBatt "3FFFh";
BA_ "GenSigTimeoutTime_ALL" SG_ 266 UBatt 2500;
BA_ "GenSigStartValue" SG_ 266 UBatt 9205;
BA_ "InvalidValue" SG_ 266 LV_Batt_Temp "FFh";
BA_ "GenSigTimeoutTime_ALL" SG_ 266 LV_Batt_Temp 2500;
BA_ "GenSigStartValue" SG_ 266 LV_Batt_Temp 40;
BA_ "InvalidValue" SG_ 266 LV_SOC "FFh";
BA_ "GenSigTimeoutTime_ALL" SG_ 266 LV_SOC 2500;
BA_ "InvalidValue" SG_ 266 LV_Batt_Current "FFFFh";
BA_ "GenSigTimeoutTime_ALL" SG_ 266 LV_Batt_Current 2500;
BA_ "GenSigStartValue" SG_ 266 LV_Batt_Current 49152;
BA_ "GenSigTimeoutTime_ALL" SG_ 274 CHKSM_BCM_CLAMP_STAT 500;
BA_ "InvalidValue" SG_ 274 ALIVE_BCM_CLAMP_STAT "Fh";
BA_ "GenSigTimeoutTime_ALL" SG_ 274 ALIVE_BCM_CLAMP_STAT 500;
BA_ "InvalidValue" SG_ 274 RemoteFunctionState "3h";
BA_ "GenSigTimeoutTime_ALL" SG_ 274 RemoteFunctionState 500;
BA_ "GenSigSendType" SG_ 274 RemoteFunctionState 4;
BA_ "InvalidValue" SG_ 274 STAT_BLS "3h";
BA_ "GenSigTimeoutTime_ALL" SG_ 274 STAT_BLS 500;
BA_ "InvalidValue" SG_ 274 STAT_CL_50_L "3h";
BA_ "GenSigTimeoutTime_ALL" SG_ 274 STAT_CL_50_L 500;
BA_ "InvalidValue" SG_ 274 Clamp50AdviceRemoteStart "3h";
BA_ "GenSigTimeoutTime_ALL" SG_ 274 Clamp50AdviceRemoteStart 500;
BA_ "GenSigSendType" SG_ 274 Clamp50AdviceRemoteStart 4;
BA_ "InvalidValue" SG_ 274 Clamp50AdviceESS "3h";
BA_ "GenSigTimeoutTime_ALL" SG_ 274 Clamp50AdviceESS 500;
BA_ "GenSigSendType" SG_ 274 Clamp50AdviceESS 4;
BA_ "InvalidValue" SG_ 274 STAT_CL_R_L "3h";
BA_ "GenSigTimeoutTime_ALL" SG_ 274 STAT_CL_R_L 500;
BA_ "InvalidValue" SG_ 274 STAT_CL_15_1_L "3h";
BA_ "GenSigTimeoutTime_ALL" SG_ 274 STAT_CL_15_1_L 500;
BA_ "InvalidValue" SG_ 274 STAT_CL_15_1_DME_L "3h";
BA_ "GenSigTimeoutTime_ALL" SG_ 274 STAT_CL_15_1_DME_L 500;
BA_ "InvalidValue" SG_ 274 FobId "3h";
BA_ "GenSigTimeoutTime_ALL" SG_ 274 FobId 500;
BA_ "InvalidValue" SG_ 274 STAT_Terminal "7h";
BA_ "GenSigTimeoutTime_ALL" SG_ 274 STAT_Terminal 500;
BA_ "InvalidValue" SG_ 274 STAT_CL30_C_BEV "3h";
BA_ "GenSigTimeoutTime_ALL" SG_ 274 STAT_CL30_C_BEV 500;
BA_ "InvalidValue" SG_ 274 BCM_Clamp_Transport "7h";
BA_ "GenSigTimeoutTime_ALL" SG_ 274 BCM_Clamp_Transport 500;
BA_ "InvalidValue" SG_ 275 MainCylinderPres "FFFFh";
BA_ "GenSigTimeoutTime_ALL" SG_ 275 MainCylinderPres 100;
BA_ "InvalidValue" SG_ 275 STAT_MainCylinderPresValid "3h";
BA_ "GenSigTimeoutTime_ALL" SG_ 275 STAT_MainCylinderPresValid 100;
BA_ "InvalidValue" SG_ 275 BreakeVacuumPressure "7FFh";
BA_ "GenSigTimeoutTime_ALL" SG_ 275 BreakeVacuumPressure 100;
BA_ "GenSigTimeoutTime_ALL" SG_ 305 ADAS_IDB_Checksum 200;
BA_ "InvalidValue" SG_ 305 ADAS_IDB_Alive "Fh";
BA_ "GenSigTimeoutTime_ALL" SG_ 305 ADAS_IDB_Alive 200;
BA_ "GenSigTimeoutTime_ALL" SG_ 305 SECCAN_ADAS_IDB 200;
BA_ "GenSigTimeoutTime_ALL" SG_ 305 ADAS_ACC_IDB_DriveOff 200;
BA_ "GenSigTimeoutTime_ALL" SG_ 306 ADAS_LKA_Checksum 200;
BA_ "InvalidValue" SG_ 306 ADAS_LKA_Alive "Fh";
BA_ "GenSigTimeoutTime_ALL" SG_ 306 ADAS_LKA_Alive 200;
BA_ "GenSigTimeoutTime_ALL" SG_ 306 LSS_Activation 200;
BA_ "GenSigTimeoutTime_ALL" SG_ 306 SECCAN_ADAS_LKA 200;
BA_ "GenSigTimeoutTime_ALL" SG_ 306 LSS_Activation_2 200;
BA_ "GenSigTimeoutTime_ALL" SG_ 306 ADAS_HapWarning 200;
BA_ "GenSigTimeoutTime_ALL" SG_ 309 ADAS_IDB_APA_Checksum 200;
BA_ "InvalidValue" SG_ 309 ADAS_IDB_APA_Alive "Fh";
BA_ "GenSigTimeoutTime_ALL" SG_ 309 ADAS_IDB_APA_Alive 200;
BA_ "GenSigTimeoutTime_ALL" SG_ 309 ADAS_EPBRequest 200;
BA_ "GenSigTimeoutTime_ALL" SG_ 309 ADAS_IDB_BrakeModeReq 200;
BA_ "GenSigTimeoutTime_ALL" SG_ 309 ADAS_IDB_FuncMode 200;
BA_ "GenSigTimeoutTime_ALL" SG_ 309 ADAS_IDB_PrefillReq 200;
BA_ "GenSigTimeoutTime_ALL" SG_ 309 ADAS_IDB_Status 200;
BA_ "GenSigTimeoutTime_ALL" SG_ 309 ADAS_IDB_Stoprequest 200;
BA_ "GenSigTimeoutTime_ALL" SG_ 309 ADAS_IDB_TargetDecel 200;
BA_ "GenSigTimeoutTime_ALL" SG_ 309 ADAS_IDB_ControlReq 200;
BA_ "GenSigTimeoutTime_ALL" SG_ 340 EPS_154_CheckSum 400;
BA_ "InvalidValue" SG_ 340 EPS_154_AliveCounter "Fh";
BA_ "GenSigTimeoutTime_ALL" SG_ 340 EPS_154_AliveCounter 400;
BA_ "GenSigTimeoutTime_ALL" SG_ 340 EPS_SteerPrsnlMod 400;
BA_ "GenSigTimeoutTime_ALL" SG_ 340 EPS_ModChgEna 400;
BA_ "GenSigTimeoutTime_ALL" SG_ 340 SECCAN_EPS_154 400;
BA_ "GenSigTimeoutTime_ALL" SG_ 373 ANRC_ESCRequest_Checksum 100;
BA_ "GenSigTimeoutTime_ALL" SG_ 373 ANRC_ESCRequest_Alive 100;
BA_ "InvalidValue" SG_ 373 ANRC_ESCRequest_Alive "Fh";
BA_ "GenSigStartValue" SG_ 373 ADAS_PrkgDstToStop 100;
BA_ "GenSigTimeoutTime_ALL" SG_ 373 ADAS_PrkgDstToStop 100;
BA_ "InvalidValue" SG_ 373 ADAS_PrkgDstToStop "FFFh";
BA_ "GenSigTimeoutTime_ALL" SG_ 373 ADAS_PrkgMaxSpdReq 100;
BA_ "InvalidValue" SG_ 373 ADAS_PrkgMaxSpdReq "FFh";
BA_ "GenSigTimeoutTime_ALL" SG_ 373 SECCAN_ANRC_ESCRequest 100;
BA_ "GenSigTimeoutTime_ALL" SG_ 376 CHKSM_YSS_LongAcc 100;
BA_ "InvalidValue" SG_ 376 ALV_YSS_LongAcc "Fh";
BA_ "GenSigTimeoutTime_ALL" SG_ 376 ALV_YSS_LongAcc 100;
BA_ "GenSigTimeoutTime_ALL" SG_ 376 YSS_LONG_ACCUNFILTERED_QUAL 100;
BA_ "InvalidValue" SG_ 376 YSS_LONG_ACC_UNFILTERED "FFFFh";
BA_ "GenSigTimeoutTime_ALL" SG_ 376 YSS_LONG_ACC_UNFILTERED 100;
BA_ "GenSigTimeoutTime_ALL" SG_ 376 YSS_LONG_ACC_QUAL 100;
BA_ "InvalidValue" SG_ 376 YSS_LONG_ACC "FFFFh";
BA_ "GenSigTimeoutTime_ALL" SG_ 376 YSS_LONG_ACC 100;
BA_ "GenSigTimeoutTime_ALL" SG_ 377 CHKSM_YSS_LateralAcc 100;
BA_ "InvalidValue" SG_ 377 ALV_YSS_LateralAcc "Fh";
BA_ "GenSigTimeoutTime_ALL" SG_ 377 ALV_YSS_LateralAcc 100;
BA_ "GenSigTimeoutTime_ALL" SG_ 377 YSS_LAT_ACCUNFILTERED_QUAL 100;
BA_ "InvalidValue" SG_ 377 YSS_LAT_ACC_UNFILTERED "FFFh";
BA_ "GenSigTimeoutTime_ALL" SG_ 377 YSS_LAT_ACC_UNFILTERED 100;
BA_ "GenSigTimeoutTime_ALL" SG_ 377 YSS_LAT_ACC_QUAL 100;
BA_ "InvalidValue" SG_ 377 YSS_LAT_ACC "FFFFh";
BA_ "GenSigTimeoutTime_ALL" SG_ 377 YSS_LAT_ACC 100;
BA_ "GenSigTimeoutTime_ALL" SG_ 381 CHKSM_YSS_YawRate 100;
BA_ "InvalidValue" SG_ 381 ALV_YSS_YawRate "Fh";
BA_ "GenSigTimeoutTime_ALL" SG_ 381 ALV_YSS_YawRate 100;
BA_ "GenSigTimeoutTime_ALL" SG_ 381 YSS_YAW_RATEUNFILTERED_QUAL 100;
BA_ "InvalidValue" SG_ 381 YSS_YAW_RATE_UNFILTERED "FFFh";
BA_ "GenSigTimeoutTime_ALL" SG_ 381 YSS_YAW_RATE_UNFILTERED 100;
BA_ "GenSigTimeoutTime_ALL" SG_ 381 YSS_YAW_RATE_QUAL 100;
BA_ "GenSigTimeoutTime_ALL" SG_ 381 YSS_SC_STATUS 100;
BA_ "InvalidValue" SG_ 381 YSS_YAW_RATE "FFFFh";
BA_ "GenSigTimeoutTime_ALL" SG_ 381 YSS_YAW_RATE 100;
BA_ "InvalidValue" SG_ 381 YSS_TEMPERATURE "FFh";
BA_ "GenSigTimeoutTime_ALL" SG_ 381 YSS_TEMPERATURE 100;
BA_ "GenSigStartValue" SG_ 381 YSS_TEMPERATURE 40;
BA_ "GenSigTimeoutTime_ALL" SG_ 382 CHKSM_SAS_Sensor 200;
BA_ "InvalidValue" SG_ 382 ALV_SAS_Sensor "Fh";
BA_ "GenSigTimeoutTime_ALL" SG_ 382 ALV_SAS_Sensor 200;
BA_ "GenSigTimeoutTime_ALL" SG_ 382 SAS_SASStsSnsr 200;
BA_ "InvalidValue" SG_ 382 SAS_SteerWhlRotSpd "3FFFh";
BA_ "GenSigTimeoutTime_ALL" SG_ 382 SAS_SteerWhlRotSpd 200;
BA_ "GenSigStartValue" SG_ 382 SAS_SteerWhlRotSpd 8192;
BA_ "GenSigTimeoutTime_ALL" SG_ 382 SAS_SteerWhlRotSpdStatus 200;
BA_ "GenSigTimeoutTime_ALL" SG_ 382 SAS_SASFailure 200;
BA_ "GenSigTimeoutTime_ALL" SG_ 382 SAS_Calibrated 200;
BA_ "InvalidValue" SG_ 382 SAS_SteerWheelAngleValid "3h";
BA_ "GenSigTimeoutTime_ALL" SG_ 382 SAS_SteerWheelAngleValid 200;
BA_ "InvalidValue" SG_ 382 SAS_SteerWheelAngle "FFFFh";
BA_ "GenSigTimeoutTime_ALL" SG_ 382 SAS_SteerWheelAngle 100;
BA_ "GenSigTimeoutTime_ALL" SG_ 383 EPS_ADAS_function_feed_2 200;
BA_ "GenSigTimeoutTime_ALL" SG_ 383 EPS_ADAS_function_feed 200;
BA_ "GenSigTimeoutTime_ALL" SG_ 383 SECCAN_EPS_ADAS_TOI 200;
BA_ "GenSigTimeoutTime_ALL" SG_ 504 CHKSM_EDS_OutPut_FR 400;
BA_ "InvalidValue" SG_ 504 ALV_EDS_OutPut_FR "Fh";
BA_ "GenSigTimeoutTime_ALL" SG_ 504 ALV_EDS_OutPut_FR 400;
BA_ "InvalidValue" SG_ 504 EDS_Work_STS_FR "Fh";
BA_ "GenSigTimeoutTime_ALL" SG_ 504 EDS_Work_STS_FR 200;
BA_ "InvalidValue" SG_ 504 EDS_Spd_FR "FFFFh";
BA_ "GenSigTimeoutTime_ALL" SG_ 504 EDS_Spd_FR 200;
BA_ "GenSigStartValue" SG_ 504 EDS_Spd_FR 20000;
BA_ "GenSigTimeoutTime_ALL" SG_ 504 EDS_output_trqValid_FR 200;
BA_ "InvalidValue" SG_ 504 EDS_MotorDriveSts_FR "3h";
BA_ "GenSigTimeoutTime_ALL" SG_ 504 EDS_MotorDriveSts_FR 400;
BA_ "GenSigTimeoutTime_ALL" SG_ 504 EDS_powoff_req_FR 200;
BA_ "GenSigTimeoutTime_ALL" SG_ 504 EDS_SpdValid_FR 400;
BA_ "InvalidValue" SG_ 504 EDS_output_trq_FR "FFFFh";
BA_ "GenSigTimeoutTime_ALL" SG_ 504 EDS_output_trq_FR 200;
BA_ "GenSigStartValue" SG_ 504 EDS_output_trq_FR 2000;
BA_ "GenSigTimeoutTime_ALL" SG_ 504 EDS_VCU_6SO_flag_FWD 400;
BA_ "GenSigTimeoutTime_ALL" SG_ 505 CHKSM_EDS_OutPut_RR 400;
BA_ "InvalidValue" SG_ 505 ALV_EDS_OutPut_RR "Fh";
BA_ "GenSigTimeoutTime_ALL" SG_ 505 ALV_EDS_OutPut_RR 200;
BA_ "InvalidValue" SG_ 505 EDS_Work_STS_RR "Fh";
BA_ "GenSigTimeoutTime_ALL" SG_ 505 EDS_Work_STS_RR 200;
BA_ "InvalidValue" SG_ 505 EDS_Spd_RR "FFFFh";
BA_ "GenSigTimeoutTime_ALL" SG_ 505 EDS_Spd_RR 200;
BA_ "GenSigStartValue" SG_ 505 EDS_Spd_RR 20000;
BA_ "GenSigTimeoutTime_ALL" SG_ 505 EDS_output_trqValid_RR 200;
BA_ "InvalidValue" SG_ 505 EDS_MotorDriveSts_RR "3h";
BA_ "GenSigTimeoutTime_ALL" SG_ 505 EDS_MotorDriveSts_RR 200;
BA_ "GenSigTimeoutTime_ALL" SG_ 505 EDS_powoff_req_RR 200;
BA_ "GenSigTimeoutTime_ALL" SG_ 505 EDS_SpdValid_RR 200;
BA_ "InvalidValue" SG_ 505 EDS_output_trq_RR "FFFFh";
BA_ "GenSigTimeoutTime_ALL" SG_ 505 EDS_output_trq_RR 200;
BA_ "GenSigStartValue" SG_ 505 EDS_output_trq_RR 2000;
BA_ "GenSigTimeoutTime_ALL" SG_ 505 EDS_VCU_6SO_flag_RWD 200;
BA_ "GenSigTimeoutTime_ALL" SG_ 521 CRC_PAS_VCU_Status 200;
BA_ "GenSigTimeoutTime_ALL" SG_ 521 Alive_PAS_VCU_Status 200;
BA_ "InvalidValue" SG_ 521 Alive_PAS_VCU_Status "Fh";
BA_ "GenSigTimeoutTime_ALL" SG_ 521 PAS_VCU_GearReq 200;
BA_ "GenSigTimeoutTime_ALL" SG_ 521 PAS_VCU_ControlReq 200;
BA_ "GenSigTimeoutTime_ALL" SG_ 521 SECCAN_PAS_VCU_Status 200;
BA_ "GenSigTimeoutTime_ALL" SG_ 521 PAS_VCU_FuncMode 200;
BA_ "GenSigTimeoutTime_ALL" SG_ 521 PAS_VCU_State 200;
BA_ "GenSigTimeoutTime_ALL" SG_ 524 CHKSM_IC_ODO 500;
BA_ "InvalidValue" SG_ 524 ALIV_IC_ODO "Fh";
BA_ "GenSigTimeoutTime_ALL" SG_ 524 ALIV_IC_ODO 500;
BA_ "InvalidValue" SG_ 524 MHU_Odometer_IC "FFFFFh";
BA_ "GenSigTimeoutTime_ALL" SG_ 524 MHU_Odometer_IC 500;
BA_ "GenSigTimeoutTime_ALL" SG_ 525 CHKSM_IDB_STATUS 200;
BA_ "InvalidValue" SG_ 525 ALV_IDB_STATUS "Fh";
BA_ "GenSigTimeoutTime_ALL" SG_ 525 ALV_IDB_STATUS 200;
BA_ "GenSigTimeoutTime_ALL" SG_ 525 ESPTransRequestType 200;
BA_ "GenSigTimeoutTime_ALL" SG_ 525 ABSFault 200;
BA_ "GenSigTimeoutTime_ALL" SG_ 525 ABSActive 200;
BA_ "GenSigTimeoutTime_ALL" SG_ 525 VehicleSpd 200;
BA_ "GenSigTimeoutTime_ALL" SG_ 525 ESC_VehicleStandstill 200;
BA_ "GenSigTimeoutTime_ALL" SG_ 525 MCPressureSts 200;
BA_ "GenSigTimeoutTime_ALL" SG_ 525 VehicleSpdSts 200;
BA_ "InvalidValue" SG_ 525 MCPressure "FFh";
BA_ "GenSigTimeoutTime_ALL" SG_ 525 MCPressure 200;
BA_ "GenSigStartValue" SG_ 525 MCPressure 21;
BA_ "InvalidValue" SG_ 525 ESC_Braking_effort "1";
BA_ "GenSigTimeoutTime_ALL" SG_ 525 ESC_Braking_effort 200;
BA_ "GenSigTimeoutTime_ALL" SG_ 525 BRAKE_LightonRequestEPBi 200;
BA_ "GenSigTimeoutTime_ALL" SG_ 525 VDCActive 200;
BA_ "GenSigTimeoutTime_ALL" SG_ 525 TCSActive 200;
BA_ "GenSigTimeoutTime_ALL" SG_ 525 TCSAvailable 200;
BA_ "GenSigTimeoutTime_ALL" SG_ 525 IDBActive 200;
BA_ "GenSigTimeoutTime_ALL" SG_ 525 IDBFault 200;
BA_ "GenSigTimeoutTime_ALL" SG_ 525 ESC_VehicleHoldStat 200;
BA_ "GenSigTimeoutTime_ALL" SG_ 525 IDB_Power_Stage 200;
BA_ "GenSigTimeoutTime_ALL" SG_ 525 ESC_BrakeReleasedFailsafe 200;
BA_ "GenSigTimeoutTime_ALL" SG_ 528 CHKSM_RCU_Status 400;
BA_ "InvalidValue" SG_ 528 ALV_RCU_Status "Fh";
BA_ "GenSigTimeoutTime_ALL" SG_ 528 ALV_RCU_Status 400;
BA_ "GenSigTimeoutTime_ALL" SG_ 528 RCU_DAA_NoOpDoorOpen_1 400;
BA_ "InvalidValue" SG_ 528 RCU_EPBParkingStatus "3h";
BA_ "GenSigTimeoutTime_ALL" SG_ 528 RCU_EPBParkingStatus 400;
BA_ "GenSigTimeoutTime_ALL" SG_ 528 EPB_Swch_Mafnc 400;
BA_ "GenSigTimeoutTime_ALL" SG_ 528 RCU_ParkBrkApplied_1 400;
BA_ "GenSigTimeoutTime_ALL" SG_ 528 RCU_ReleaseEPB_Wo_PressBrk_1 400;
BA_ "GenSigTimeoutTime_ALL" SG_ 528 RCU_BrkForceNotEnough_1 400;
BA_ "GenSigTimeoutTime_ALL" SG_ 528 RCU_ParkOnSteepInclination_1 400;
BA_ "GenSigTimeoutTime_ALL" SG_ 528 RCU_ECD_RWU_active_1 400;
BA_ "GenSigTimeoutTime_ALL" SG_ 528 RCU_EHandBrk_fault_1 400;
BA_ "GenSigTimeoutTime_ALL" SG_ 528 RCU_BRAKE_LightonRequestEPBi 400;
BA_ "GenSigTimeoutTime_ALL" SG_ 529 PcbCtrlFail 200;
BA_ "GenSigTimeoutTime_ALL" SG_ 529 PcbActiveFlg 200;
BA_ "InvalidValue" SG_ 530 IDB_VehicleSpeed "FFFFh";
BA_ "GenSigTimeoutTime_ALL" SG_ 530 IDB_VehicleSpeed 200;
BA_ "GenSigTimeoutTime_ALL" SG_ 530 IDB_AxOffsetComp 200;
BA_ "GenSigTimeoutTime_ALL" SG_ 530 IDB_BLSInvalidSts 200;
BA_ "GenSigTimeoutTime_ALL" SG_ 530 IDB_AxInvalidSts 200;
BA_ "GenSigTimeoutTime_ALL" SG_ 530 IDB_AxOffsetCompSts 200;
BA_ "GenSigTimeoutTime_ALL" SG_ 532 CRC_VCU_ADAS 200;
BA_ "InvalidValue" SG_ 532 ALIV_VCU_ADAS "Fh";
BA_ "GenSigTimeoutTime_ALL" SG_ 532 ALIV_VCU_ADAS 200;
BA_ "GenSigTimeoutTime_ALL" SG_ 532 VCU_ADAS_ControledRes 200;
BA_ "GenSigTimeoutTime_ALL" SG_ 532 VCU_ADAS_Available 200;
BA_ "GenSigTimeoutTime_ALL" SG_ 532 VCU_ADAS_FuncMode 200;
BA_ "GenSigTimeoutTime_ALL" SG_ 532 VCU_ADAS_CtrlAbortFeedback 200;
BA_ "InvalidValue" SG_ 570 IDB_WheelDirection_FR "3h";
BA_ "GenSigTimeoutTime_ALL" SG_ 570 IDB_WheelDirection_FR 200;
BA_ "InvalidValue" SG_ 570 IDB_WheelDirection_FL "3h";
BA_ "GenSigTimeoutTime_ALL" SG_ 570 IDB_WheelDirection_FL 200;
BA_ "InvalidValue" SG_ 570 IDB_WheelSpeedRC_FL "FFFEh";
BA_ "GenSigTimeoutTime_ALL" SG_ 570 IDB_WheelSpeedRC_FL 200;
BA_ "InvalidValue" SG_ 570 IDB_WheelSpeedRC_FR "FFFEh";
BA_ "GenSigTimeoutTime_ALL" SG_ 570 IDB_WheelSpeedRC_FR 200;
BA_ "InvalidValue" SG_ 571 IDB_WheelDirection_RR "3h";
BA_ "GenSigTimeoutTime_ALL" SG_ 571 IDB_WheelDirection_RR 200;
BA_ "InvalidValue" SG_ 571 IDB_WheelDirection_RL "3h";
BA_ "GenSigTimeoutTime_ALL" SG_ 571 IDB_WheelDirection_RL 200;
BA_ "InvalidValue" SG_ 571 IDB_WheelSpeedRC_RL "FFFEh";
BA_ "GenSigTimeoutTime_ALL" SG_ 571 IDB_WheelSpeedRC_RL 200;
BA_ "InvalidValue" SG_ 571 IDB_WheelSpeedRC_RR "FFFEh";
BA_ "GenSigTimeoutTime_ALL" SG_ 571 IDB_WheelSpeedRC_RR 200;
BA_ "GenSigTimeoutTime_ALL" SG_ 596 CRC_AVL_RPM_WHL_REAR 200;
BA_ "InvalidValue" SG_ 596 ALIV_AVL_RPM_WHL_REAR "Fh";
BA_ "GenSigTimeoutTime_ALL" SG_ 596 ALIV_AVL_RPM_WHL_REAR 200;
BA_ "GenSigTimeoutTime_ALL" SG_ 596 AVL_RPM_WHL_RLH 200;
BA_ "GenSigStartValue" SG_ 596 AVL_RPM_WHL_RLH 32819;
BA_ "GenSigTimeoutTime_ALL" SG_ 596 AVL_RPM_WHL_RRH 200;
BA_ "GenSigStartValue" SG_ 596 AVL_RPM_WHL_RRH 32819;
BA_ "InvalidValue" SG_ 596 QU_AVL_RPM_WHL_RLH "Fh";
BA_ "GenSigTimeoutTime_ALL" SG_ 596 QU_AVL_RPM_WHL_RLH 200;
BA_ "InvalidValue" SG_ 596 QU_AVL_RPM_WHL_RRH "Fh";
BA_ "GenSigTimeoutTime_ALL" SG_ 596 QU_AVL_RPM_WHL_RRH 200;
BA_ "GenSigTimeoutTime_ALL" SG_ 597 CRC_AVL_RPM_WHL_FRONT 200;
BA_ "InvalidValue" SG_ 597 ALIV_AVL_RPM_WHL_FRONT "Fh";
BA_ "GenSigTimeoutTime_ALL" SG_ 597 ALIV_AVL_RPM_WHL_FRONT 200;
BA_ "GenSigTimeoutTime_ALL" SG_ 597 AVL_RPM_WHL_FLH 200;
BA_ "GenSigStartValue" SG_ 597 AVL_RPM_WHL_FLH 32819;
BA_ "GenSigTimeoutTime_ALL" SG_ 597 AVL_RPM_WHL_FRH 200;
BA_ "GenSigStartValue" SG_ 597 AVL_RPM_WHL_FRH 32819;
BA_ "InvalidValue" SG_ 597 QU_AVL_RPM_WHL_FLH "Fh";
BA_ "GenSigTimeoutTime_ALL" SG_ 597 QU_AVL_RPM_WHL_FLH 200;
BA_ "InvalidValue" SG_ 597 QU_AVL_RPM_WHL_FRH "Fh";
BA_ "GenSigTimeoutTime_ALL" SG_ 597 QU_AVL_RPM_WHL_FRH 200;
BA_ "GenSigTimeoutTime_ALL" SG_ 617 CHKSM_VCU_HV_Status 400;
BA_ "InvalidValue" SG_ 617 ALV_VCU_HV_Status "Fh";
BA_ "GenSigTimeoutTime_ALL" SG_ 617 ALV_VCU_HV_Status 400;
BA_ "GenSigTimeoutTime_ALL" SG_ 617 VCU_VehicleHVStatus 400;
BA_ "GenSigTimeoutTime_ALL" SG_ 649 CHKSM_IDB_ZF2 200;
BA_ "InvalidValue" SG_ 649 ALIVE_IDB_ZF2 "Fh";
BA_ "GenSigTimeoutTime_ALL" SG_ 649 ALIVE_IDB_ZF2 200;
BA_ "InvalidValue" SG_ 649 AxOutStatus "1h";
BA_ "GenSigTimeoutTime_ALL" SG_ 649 AxOutStatus 200;
BA_ "InvalidValue" SG_ 649 QU_VYAW_VEH "Fh";
BA_ "GenSigTimeoutTime_ALL" SG_ 649 QU_VYAW_VEH 200;
BA_ "GenSigStartValue" SG_ 649 QU_VYAW_VEH 8;
BA_ "InvalidValue" SG_ 649 AyOutStatus "1h";
BA_ "GenSigTimeoutTime_ALL" SG_ 649 AyOutStatus 200;
BA_ "InvalidValue" SG_ 649 AcceleratorY "FFFh";
BA_ "GenSigTimeoutTime_ALL" SG_ 649 AcceleratorY 200;
BA_ "GenSigStartValue" SG_ 649 AcceleratorY 795;
BA_ "InvalidValue" SG_ 649 AcceleratorX "FFFh";
BA_ "GenSigTimeoutTime_ALL" SG_ 649 AcceleratorX 200;
BA_ "InvalidValue" SG_ 649 VYAW_VEH "FFFFh";
BA_ "GenSigTimeoutTime_ALL" SG_ 649 VYAW_VEH 200;
BA_ "GenSigStartValue" SG_ 649 VYAW_VEH 32768;
BA_ "GenSigTimeoutTime_ALL" SG_ 714 CHKSM_IC_SENSOR 500;
BA_ "InvalidValue" SG_ 714 ALV_IC_SENSOR "Fh";
BA_ "GenSigTimeoutTime_ALL" SG_ 714 ALV_IC_SENSOR 500;
BA_ "InvalidValue" SG_ 714 MHU_STAT_AmbientTempRaw "FFh";
BA_ "GenSigTimeoutTime_ALL" SG_ 714 MHU_STAT_AmbientTempRaw 500;
BA_ "GenSigStartValue" SG_ 714 MHU_STAT_AmbientTempRaw 80;
BA_ "InvalidValue" SG_ 714 MHU_STAT_FuelLevel "FFh";
BA_ "GenSigTimeoutTime_ALL" SG_ 714 MHU_STAT_FuelLevel 500;
BA_ "InvalidValue" SG_ 714 MHU_STAT_AmbientTemp "FFh";
BA_ "GenSigTimeoutTime_ALL" SG_ 714 MHU_STAT_AmbientTemp 500;
BA_ "GenSigStartValue" SG_ 714 MHU_STAT_AmbientTemp 80;
BA_ "InvalidValue" SG_ 714 MHU_STAT_CoolantLevelStatus "3h";
BA_ "GenSigTimeoutTime_ALL" SG_ 714 MHU_STAT_CoolantLevelStatus 500;
BA_ "InvalidValue" SG_ 760 DISP_HR "FFh";
BA_ "GenSigTimeoutTime_ALL" SG_ 760 DISP_HR 5000;
BA_ "InvalidValue" SG_ 760 DISP_MN "FFh";
BA_ "GenSigTimeoutTime_ALL" SG_ 760 DISP_MN 5000;
BA_ "InvalidValue" SG_ 760 DISP_SEC "FFh";
BA_ "GenSigTimeoutTime_ALL" SG_ 760 DISP_SEC 5000;
BA_ "InvalidValue" SG_ 760 DISP_DATE_DAY "FFh";
BA_ "GenSigTimeoutTime_ALL" SG_ 760 DISP_DATE_DAY 5000;
BA_ "GenSigStartValue" SG_ 760 DISP_DATE_DAY 1;
BA_ "InvalidValue" SG_ 760 DISP_DATE_MON "Fh";
BA_ "GenSigTimeoutTime_ALL" SG_ 760 DISP_DATE_MON 5000;
BA_ "GenSigStartValue" SG_ 760 DISP_DATE_MON 1;
BA_ "InvalidValue" SG_ 760 DISP_DATE_WDAY "Fh";
BA_ "GenSigTimeoutTime_ALL" SG_ 760 DISP_DATE_WDAY 5000;
BA_ "InvalidValue" SG_ 760 DISP_DATE_YR "FFFFh";
BA_ "GenSigTimeoutTime_ALL" SG_ 760 DISP_DATE_YR 5000;
BA_ "GenSigStartValue" SG_ 760 DISP_DATE_YR 1;
BA_ "InvalidValue" SG_ 760 ST_DISP_CTI_DATE "Fh";
BA_ "GenSigTimeoutTime_ALL" SG_ 760 ST_DISP_CTI_DATE 5000;
BA_ "GenSigTimeoutTime_ALL" SG_ 770 CHKSM_CCU_TEMP_PRESSURE 5000;
BA_ "InvalidValue" SG_ 770 ALV_CCU_TEMP_PRESSURE "Fh";
BA_ "GenSigTimeoutTime_ALL" SG_ 770 ALV_CCU_TEMP_PRESSURE 5000;
BA_ "InvalidValue" SG_ 770 CCU_Pressure_AC "3Fh";
BA_ "GenSigTimeoutTime_ALL" SG_ 770 CCU_Pressure_AC 5000;
BA_ "InvalidValue" SG_ 770 CCU_InteriorTemp "FFh";
BA_ "GenSigTimeoutTime_ALL" SG_ 770 CCU_InteriorTemp 5000;
BA_ "GenSigStartValue" SG_ 770 CCU_InteriorTemp 80;
BA_ "InvalidValue" SG_ 770 CCU_TempEx_AC "FFh";
BA_ "GenSigTimeoutTime_ALL" SG_ 770 CCU_TempEx_AC 5000;
BA_ "GenSigStartValue" SG_ 770 CCU_TempEx_AC 80;
BA_ "InvalidValue" SG_ 770 CCU_EvaporatorTemp "FFh";
BA_ "GenSigTimeoutTime_ALL" SG_ 770 CCU_EvaporatorTemp 5000;
BA_ "GenSigStartValue" SG_ 770 CCU_EvaporatorTemp 80;
BA_ "GenSigTimeoutTime_ALL" SG_ 796 CHKSM_EPS_SteeringHoldState 100;
BA_ "InvalidValue" SG_ 796 ALV_EPS_SteeringHoldState "Fh";
BA_ "GenSigTimeoutTime_ALL" SG_ 796 ALV_EPS_SteeringHoldState 100;
BA_ "InvalidValue" SG_ 796 EPS_ADAS_FuncMode " -";
BA_ "GenSigTimeoutTime_ALL" SG_ 796 EPS_ADAS_FuncMode 100;
BA_ "GenSigTimeoutTime_ALL" SG_ 796 EPS_Drive_Intervention 100;
BA_ "GenSigTimeoutTime_ALL" SG_ 796 EPS_ADAS_StrAngRes 100;
BA_ "GenSigTimeoutTime_ALL" SG_ 796 EPS_ADAS_ControlAvailable 100;
BA_ "InvalidValue" SG_ 796 EPS_TorqueLimitationState "1";
BA_ "GenSigTimeoutTime_ALL" SG_ 796 EPS_TorqueLimitationState 100;
BA_ "GenSigTimeoutTime_ALL" SG_ 796 EPS_ADAS_CtrlAbortFeedback 100;
BA_ "GenSigTimeoutTime_ALL" SG_ 813 CRC_ACC_STATUS 200;
BA_ "InvalidValue" SG_ 813 Alive_ACC_STATUS "Fh";
BA_ "GenSigTimeoutTime_ALL" SG_ 813 Alive_ACC_STATUS 200;
BA_ "GenSigTimeoutTime_ALL" SG_ 813 ADAS_ACC_Information 200;
BA_ "GenSigTimeoutTime_ALL" SG_ 813 ADAS_ACC_Main_Mode 200;
BA_ "GenSigTimeoutTime_ALL" SG_ 813 ADAS_ACC_AccelDecel_Cmd 200;
BA_ "GenSigStartValue" SG_ 813 ADAS_ACC_AccelDecel_Cmd 1200;
BA_ "GenSigTimeoutTime_ALL" SG_ 813 ADAS_ACC_StandstillReq 200;
BA_ "InvalidValue" SG_ 813 ADAS_ACC_Mode "7h";
BA_ "GenSigTimeoutTime_ALL" SG_ 813 ADAS_ACC_Mode 200;
BA_ "InvalidValue" SG_ 813 ADAS_ACC_IDB_DecCmdAct "7h";
BA_ "GenSigTimeoutTime_ALL" SG_ 813 ADAS_ACC_IDB_DecCmdAct 200;
BA_ "GenSigTimeoutTime_ALL" SG_ 813 SECCAN_ADAS_ACC_Status 200;
BA_ "GenSigTimeoutTime_ALL" SG_ 814 CRC_AEB_STATUS 200;
BA_ "InvalidValue" SG_ 814 Alive_AEB_STATUS "Fh";
BA_ "GenSigTimeoutTime_ALL" SG_ 814 Alive_AEB_STATUS 200;
BA_ "GenSigTimeoutTime_ALL" SG_ 814 ADAS_AEB_Prefill 200;
BA_ "GenSigTimeoutTime_ALL" SG_ 814 ADAS_AEB_HBA_Level 200;
BA_ "GenSigTimeoutTime_ALL" SG_ 814 ADAS_AEB_Target_Deceleration 200;
BA_ "GenSigTimeoutTime_ALL" SG_ 814 ADAS_AEB_HBA_Req 200;
BA_ "GenSigTimeoutTime_ALL" SG_ 814 ADAS_AEB_Braking_Progress 200;
BA_ "GenSigTimeoutTime_ALL" SG_ 814 ADAS_AEB_Hold 200;
BA_ "GenSigTimeoutTime_ALL" SG_ 814 FCAM_AEB_DBS_Active 200;
BA_ "GenSigTimeoutTime_ALL" SG_ 815 CHKSM_IDB_Info_Flag 200;
BA_ "InvalidValue" SG_ 815 ALV_IDB_Info_Flag "Fh";
BA_ "GenSigTimeoutTime_ALL" SG_ 815 ALV_IDB_Info_Flag 200;
BA_ "GenSigTimeoutTime_ALL" SG_ 815 IDB_ACC_Available_Flag 200;
BA_ "GenSigTimeoutTime_ALL" SG_ 815 IDB_ACC_Deceleration_Flag 200;
BA_ "GenSigTimeoutTime_ALL" SG_ 815 IDB_ACC_Acceleration_Flag 200;
BA_ "GenSigTimeoutTime_ALL" SG_ 815 IDB_RAEB_Active_Flag 200;
BA_ "GenSigTimeoutTime_ALL" SG_ 815 IDB_RAEB_Available_Flag 200;
BA_ "GenSigTimeoutTime_ALL" SG_ 815 IDB_AEB_Active_Flag 200;
BA_ "GenSigTimeoutTime_ALL" SG_ 815 IDB_AEB_Available_Flag 200;
BA_ "GenSigTimeoutTime_ALL" SG_ 815 IDB_ACC_DriverOverride 200;
BA_ "GenSigTimeoutTime_ALL" SG_ 815 SECCAN_IDB_Info_Flag 200;
BA_ "GenSigTimeoutTime_ALL" SG_ 816 ADAS_RAEB_Checksum 200;
BA_ "InvalidValue" SG_ 816 ADAS_RAEB_Alive "Fh";
BA_ "GenSigTimeoutTime_ALL" SG_ 816 ADAS_RAEB_Alive 200;
BA_ "GenSigTimeoutTime_ALL" SG_ 816 ADAS_EPS_StrConReq 200;
BA_ "GenSigTimeoutTime_ALL" SG_ 816 ADAS_EPS_Status 200;
BA_ "GenSigTimeoutTime_ALL" SG_ 816 ADAS_EPS_FuncMode 200;
BA_ "GenSigTimeoutTime_ALL" SG_ 816 ADAS_EPSAngleReq 200;
BA_ "InvalidValue" SG_ 817 MILE_KM "FFFFFFh";
BA_ "GenSigTimeoutTime_ALL" SG_ 817 MILE_KM 500;
BA_ "InvalidValue" SG_ 817 FLLV_FUTA "FFh";
BA_ "GenSigTimeoutTime_ALL" SG_ 817 FLLV_FUTA 500;
BA_ "InvalidValue" SG_ 817 RNG "FFFh";
BA_ "GenSigTimeoutTime_ALL" SG_ 817 RNG 500;
BA_ "InvalidValue" SG_ 817 ST_FLLV_FUTA_SPAR "3h";
BA_ "GenSigTimeoutTime_ALL" SG_ 817 ST_FLLV_FUTA_SPAR 500;
BA_ "GenSigTimeoutTime_ALL" SG_ 890 CHKSM_ADAS_EPS_LATE_CON 100;
BA_ "InvalidValue" SG_ 890 ALV_ADAS_EPS_LATE_CON "Fh";
BA_ "GenSigTimeoutTime_ALL" SG_ 890 ALV_ADAS_EPS_LATE_CON 100;
BA_ "GenSigTimeoutTime_ALL" SG_ 890 ADAS_EPS_StrWhe_TOLAct 100;
BA_ "GenSigTimeoutTime_ALL" SG_ 890 ADAS_EPS_StrWhe_AOLAct 100;
BA_ "GenSigTimeoutTime_ALL" SG_ 890 ADAS_EPS_AOLReq 100;
BA_ "GenSigTimeoutTime_ALL" SG_ 890 ADAS_EPS_Torq_Fact_Req 100;
BA_ "GenSigTimeoutTime_ALL" SG_ 890 SECCAN_ADAS_EPS_LATE_CON 100;
BA_ "GenSigTimeoutTime_ALL" SG_ 891 EPS_SteeringEMTorque 200;
BA_ "GenSigStartValue" SG_ 891 EPS_SteeringEMTorque 1024;
BA_ "GenSigTimeoutTime_ALL" SG_ 891 EPS_ADAS_AOLAct 200;
BA_ "InvalidValue" SG_ 891 EPS_SteeringDriverTorque "FFFh";
BA_ "GenSigTimeoutTime_ALL" SG_ 891 EPS_SteeringDriverTorque 200;
BA_ "GenSigStartValue" SG_ 891 EPS_SteeringDriverTorque 1024;
BA_ "GenSigTimeoutTime_ALL" SG_ 891 SECCAN_EPS_ADAS_Steering_Trq 200;
BA_ "GenSigTimeoutTime_ALL" SG_ 894 CHKSM_EPS_Advanced 100;
BA_ "InvalidValue" SG_ 894 ALV_EPS_Advanced "Fh";
BA_ "GenSigTimeoutTime_ALL" SG_ 894 ALV_EPS_Advanced 100;
BA_ "GenSigTimeoutTime_ALL" SG_ 894 EPS_TorqSensorSts 100;
BA_ "InvalidValue" SG_ 894 EPS_SteeringTorque "FFFh";
BA_ "GenSigTimeoutTime_ALL" SG_ 894 EPS_SteeringTorque 100;
BA_ "GenSigStartValue" SG_ 894 EPS_SteeringTorque 1024;
BA_ "GenSigTimeoutTime_ALL" SG_ 894 EPS_SteeringTorqueValid 100;
BA_ "InvalidValue" SG_ 894 EPS_Mode "3h";
BA_ "GenSigTimeoutTime_ALL" SG_ 894 EPS_Mode 100;
BA_ "GenSigTimeoutTime_ALL" SG_ 894 EPS_Steering_angle_spd 100;
BA_ "InvalidValue" SG_ 894 EPSAngRespSts "3h";
BA_ "GenSigTimeoutTime_ALL" SG_ 894 EPSAngRespSts 100;
BA_ "GenSigTimeoutTime_ALL" SG_ 894 EPS_Steering_angle 100;
VAL_ 198 ESC_ADAS_Active 0 "No Active" 1 "Active" ;
VAL_ 198 ESC_ADAS_FuncMode 0 "Function Not Active" 1 "APA Mode" 2 "RP Mode" 3 "SM Mode" 4 "RAEB Mode" ;
VAL_ 198 ESC_ADAS_CtrlAbortFeedback2 0 "Normal" 1 "Vehicle Block" 2 "Improper handshake" 3 "over speed" 4 "unexpected EPB action" 5 "other sub ESC function active" 6 "Slope Over" 7 "Failure" ;
VAL_ 198 ESC_ADAS_BrakeMode 0 "Function Not Active" 1 "Comfort Brake Active" 2 "Emergency Brake Active" ;
VAL_ 198 ESC_ADAS_Available 0 "Available" 1 "Not Available" ;
VAL_ 198 ESC_PrefillSts 0 "no prefill" 1 "prefilling" 2 "prefilled" ;
VAL_ 200 AVH_ActiveStatus 0 "AVH Inactive" 1 "AVH Active" 2 "AVH being released" 3 "Reserved" ;
VAL_ 200 AVH_DispMSG 0 "Off (none)" 1 "AUTO HOLD to be deactivated Press Brake Pedal" 2 "Reserved" 3 "Reserved" ;
VAL_ 200 AVH_LampReq 0 "AVH Off" 1 "AVH failure (Yellow)" 2 "AVH ACTIVE (Green)" 3 "AVH READY (White)" ;
VAL_ 241 IDB_RecuBrakeControl_Sts 0 "Enable" 1 "Disable" ;
VAL_ 241 IDB_RecuBrkTorqueReq_Sts 0 "Not Active" 1 "Active" ;
VAL_ 241 IDB_Brake_Pedal_position_sts 0 "Valid" 1 "Invalid" ;
VAL_ 244 IDB_TorqueIncrease_Active_FR 0 "Not Active" 1 "Active" ;
VAL_ 244 IDB_TorqueIncrease_Active_RR 0 "Not Active" 1 "Active" ;
VAL_ 245 IDB_TorqueReduce_Active_FR 0 "Not Active" 1 "Active" ;
VAL_ 245 IDB_TorqueReduce_Active_RR 0 "Not Active" 1 "Active" ;
VAL_ 257 DrowsDistractionLvl 0 "No warning" 1 "Drowsiness warning level 1" 2 "Drowsiness warning level 2" 3 "Sleep warning level 1" 4 "Sleep warning level 2" 5 "Sleep warning level 3" 6 "Distraction warning level 1" 7 "Distraction warning level 2" 8 "Reserved" 9 "invalid";
VAL_ 257 DriverAttentionWarn 0 "Unavailable" 1 "Unknown" 2 "NoWarning" 3 "Distractive" 4 "Warninglevel1" 5 "Warninglevel2" 6 "Reserved" 7 "Signal invalid";
VAL_ 257 Haptic_Warning 0 "Deactivation" 1 "Activation" 2 "Reserved" 3 "Signal Invalid" ;
VAL_ 258 PDCU_DrvModSig 0 "Normal Mode" 1 "Eco Mode" 2 "Sport Mode" 3 " Reserved" 4 " Reserved" 5 " Reserved" 6 " Reserved" 7 " Reserved" ;
VAL_ 263 STAT_CDL_LED 0 "OFF" 1 "ON" 2 "blinking" 3 "Signal invalid" ;
VAL_ 263 STAT_DoorUnlockFL 0 "Locked" 1 "Unlocked" 2 "Reserved" 3 "Signal invalid" ;
VAL_ 263 STAT_ATWS 0 "Secured" 1 "Unsecured" 2 "Alarm" 3 "Partly secured" 4 "Reserved" 5 "Reserved" 6 "Reserved" 7 "Signal invalid" ;
VAL_ 263 STAT_DoorLockFL 0 "Unlocked" 1 "Locked" 2 "Reserved" 3 "Signal invalid" ;
VAL_ 274 RemoteFunctionState 0 "Normal function" 1 "Remote function" 2 "Reserved" 3 "Signal Invalid" ;
VAL_ 274 STAT_BLS 0 "BLS not pressed" 1 "BLS pressed" 2 "Reserved" 3 "Signal invalid" ;
VAL_ 274 STAT_CL_50_L 0 "OFF" 1 "ON" 2 "Failure" 3 "Signal invalid" ;
VAL_ 274 Clamp50AdviceRemoteStart 0 "Engine Start announcement not active" 1 "Engine Start announcement active" 2 "Reserved" 3 "Invalid" ;
VAL_ 274 Clamp50AdviceESS 0 "Engine Start announcement not active" 1 "Engine Start announcement active" 2 "Reserved" 3 "Invalid" ;
VAL_ 274 STAT_CL_R_L 0 "OFF" 1 "ON" 2 "Failure" 3 "Signal invalid" ;
VAL_ 274 STAT_CL_15_1_L 0 "OFF" 1 "ON" 2 "Failure" 3 "Signal invalid" ;
VAL_ 274 STAT_CL_15_1_DME_L 0 "OFF" 1 "ON" 2 "Failure" 3 "Signal invalid" ;
VAL_ 274 FobId 0 "Key not available" 1 "FOB_1" 2 "FOB_2" 3 "Signal invalid" ;
VAL_ 274 STAT_Terminal 0 "OFF(Comfort Enable)" 1 "ACC (Park)" 2 "ON (Driver Present)" 3 "Engine start (eMotor running)" 4 "SW Update OTA" 5 "Reserved" 6 "Reserved" 7 "Signal Invalid" ;
VAL_ 274 STAT_CL30_C_BEV 0 "OFF" 1 "ON" 2 "Failure" 3 "Signal invalid" ;
VAL_ 274 BCM_Clamp_Transport 0 "Transport Disabled" 1 "Transport E-Motor Running" 2 "Transport Driver Present" 3 "Ttransport ACC" 4 "Transport OFF" 5 "Init" 6 "Reserved " 7 "Reserved " ;
VAL_ 275 STAT_MainCylinderPresValid 0 "Valid" 1 "Reserved" 2 "Reserved" 3 "Signal invalid" ;
VAL_ 305 ADAS_ACC_IDB_DriveOff 0 "No request" 1 "DriveOff is required" ;
VAL_ 306 LSS_Activation 0 "LKA activation" 1 "ELK activation" 2 "TJA activation" 3 "No activation" ;
VAL_ 306 LSS_Activation_2 0 "HWA activation" 1 "ESA activation" 2 "No activation" 3 "Reserved" ;
VAL_ 306 ADAS_HapWarning 0 "Deactivation" 1 "Activation" ;
VAL_ 309 ADAS_EPBRequest 0 "No request" 1 "Request apply" 2 "Request Release" 3 "Reserved" ;
VAL_ 309 ADAS_IDB_BrakeModeReq 0 "No request" 1 "Comfortable Brake" 2 "Emergency Brake" ;
VAL_ 309 ADAS_IDB_FuncMode 0 "Function Not Active" 1 "FAPA Mode" 2 "RP Mode" 3 "SM Mode" 4 "RAEB Mode";
VAL_ 309 ADAS_IDB_PrefillReq 0 "No Request" 1 "Request" ;
VAL_ 309 ADAS_IDB_Status 0 "Off" 1 "standby" 2 "Enable" 3 "Active" 4 "Finished" 5 "Suspend" 6 "Abort" 7 "Failed" ;
VAL_ 309 ADAS_IDB_Stoprequest 0 "No Request" 1 "Request" ;
VAL_ 309 ADAS_IDB_ControlReq 0 "No Request" 1 "Request" ;
VAL_ 340 EPS_SteerPrsnlMod 0 "Normal Mode" 1 "Eco Mode" 2 "Sport Mode" 3 "Reserved" 4 "Reserved" 5 "Reserved" 6 "Reserved" 7 "Reserved" ;
VAL_ 340 EPS_ModChgEna 0 "Disable" 1 "Enable" ;
VAL_ 373 ADAS_PrkgDstToStop 4095 "Invalid" ;
VAL_ 373 ADAS_PrkgMaxSpdReq 255 "Invalid" ;
VAL_ 376 YSS_LONG_ACCUNFILTERED_QUAL 2 "VALID" 4 "SUBSITUTE" 6 "IN VALID" 14 "NOT AVAILABLE" 15 "UNFILLED" ;
VAL_ 376 YSS_LONG_ACC_QUAL 2 "VALID" 4 "SUBSITUTE" 6 "IN VALID" 14 "NOT AVAILABLE" 15 "UNFILLED" ;
VAL_ 377 YSS_LAT_ACCUNFILTERED_QUAL 2 "VALID" 4 "SUBSITUTE" 6 "IN VALID" 14 "NOT AVAILABLE" 15 "UNFILLED" ;
VAL_ 377 YSS_LAT_ACC_QUAL 2 "VALID" 4 "SUBSITUTE" 6 "IN VALID" 14 "NOT AVAILABLE" 15 "UNFILLED" ;
VAL_ 381 YSS_YAW_RATEUNFILTERED_QUAL 2 "VALID" 4 "SUBSITUTE" 6 "IN VALID" 14 "NOT AVAILABLE" 15 "UNFILLED" ;
VAL_ 381 YSS_YAW_RATE_QUAL 2 "VALID" 4 "SUBSITUTE" 6 "IN VALID" 14 "NOT AVAILABLE" 15 "UNFILLED" ;
VAL_ 381 YSS_SC_STATUS 0 "No Mistake" 2 "Under Voltage" 3 "Over Voltage" 13 "Function Not Available" 14 "Function Error" 15 "Un-Filled" ;
VAL_ 382 SAS_SASStsSnsr 0 "sensor value  Invalid" 1 "sensor value  valid" ;
VAL_ 382 SAS_SteerWhlRotSpdStatus 0 "Invalid" 1 "Valid" ;
VAL_ 382 SAS_SASFailure 0 "Failure" 1 "No Failure" ;
VAL_ 382 SAS_Calibrated 0 "Not Calibrated" 1 "Calibrated" ;
VAL_ 382 SAS_SteerWheelAngleValid 0 "Valid" 1 "Invalid" ;
VAL_ 383 EPS_ADAS_function_feed_2 0 "HWA activation" 1 "ESA activation" 2 "No activation" 3 "Reserved" ;
VAL_ 383 EPS_ADAS_function_feed 0 "LKA activation" 1 "ELK activation" 2 "TJA activation" 3 "No activation" ;
VAL_ 504 EDS_Work_STS_FR 0 "default" 1 "init" 2 "standby" 3 "precharge" 4 "normal" 5 "HVReady" 6 "6SO" 11 "shut down" 12 "after run" 13 "Failure" 14 "power off" 15 "invaild" ;
VAL_ 504 EDS_output_trqValid_FR 0 "invalid" 1 "valid" ;
VAL_ 504 EDS_MotorDriveSts_FR 0 "Zero control" 1 "Drive control" 2 "regen control" 3 "Invaild" ;
VAL_ 504 EDS_powoff_req_FR 0 "(No request)" 1 "(Request high voltage power down)" ;
VAL_ 504 EDS_SpdValid_FR 0 "invalid" 1 "valid" ;
VAL_ 504 EDS_VCU_6SO_flag_FWD 0 "OFF" 1 "ON" ;
VAL_ 505 EDS_Work_STS_RR 0 "default" 1 "init" 2 "standby" 3 "precharge" 4 "normal" 5 "HVReady" 6 "6SO" 11 "shut down" 12 "after run" 13 "Failure" 14 "power off" 15 "invaild" ;
VAL_ 505 EDS_output_trqValid_RR 0 "invalid" 1 "valid" ;
VAL_ 505 EDS_MotorDriveSts_RR 0 "Zero control" 1 "Drive control" 2 "regen control" 3 "Invaild" ;
VAL_ 505 EDS_powoff_req_RR 0 "(No request)" 1 "(Request high voltage power down)" ;
VAL_ 505 EDS_SpdValid_RR 0 "invalid" 1 "valid" ;
VAL_ 505 EDS_VCU_6SO_flag_RWD 0 "OFF" 1 "ON" ;
VAL_ 521 PAS_VCU_GearReq 0 "No request" 1 "R" 2 "N" 3 "D" 4 "P" ;
VAL_ 521 PAS_VCU_ControlReq 0 "No request" 1 "Request" ;
VAL_ 521 PAS_VCU_FuncMode 0 "Function Not Active" 1 "FAPA Mode" 2 "RP Mode" 3 "SM Mode" ;
VAL_ 521 PAS_VCU_State 0 "Off" 1 "Standby" 2 "Enable" 3 "Active" 4 "Finished" 5 "Suspend" 6 "Abort" 7 "Failed" ;
VAL_ 525 ESPTransRequestType 0 "No action" 1 "Inhibit upshift" 2 "Inhibit downshift" 3 "Hold gear" ;
VAL_ 525 ABSFault 0 "No fault" 1 "Fault" ;
VAL_ 525 ABSActive 0 "Inactive" 1 "Active" ;
VAL_ 525 ESC_VehicleStandstill 0 "NO_VEHICLE_STANDSTILL" 1 "VEHICLE_STANDSTILL" ;
VAL_ 525 MCPressureSts 0 "Valid" 1 "Invalid" ;
VAL_ 525 VehicleSpdSts 0 "Valid" 1 "Invalid" ;
VAL_ 525 ESC_Braking_effort 0 "No brake force generated" 1 "Brake force generated" ;
VAL_ 525 BRAKE_LightonRequestEPBi 0 "Brake light OFF" 1 "Brake light ON" 2 "Reserved" 3 "Signal not available" ;
VAL_ 525 VDCActive 0 "Inactive" 1 "Active" ;
VAL_ 525 TCSActive 0 "Inactive" 1 "Active" ;
VAL_ 525 TCSAvailable 0 "Avialable" 1 "Unavailable" ;
VAL_ 525 IDBActive 0 "Inactive" 1 "Active" ;
VAL_ 525 IDBFault 0 "No fault" 1 "Fault" ;
VAL_ 525 ESC_VehicleHoldStat 0 "No vehicle hold" 1 "vehicle hold" 2 "reserved" 3 "reserved" ;
VAL_ 525 IDB_Power_Stage 0 "Motor Max Power 150Kw" 1 "Motor Max Power 300Kw" 2 "Reserved" 3 "Reserved" 15 "Invalid" ;
VAL_ 525 ESC_BrakeReleasedFailsafe 0 "No need to release brakes because of failsafe situation" 1 "ESC is releasing the brakes because of failsafe" ;
VAL_ 528 RCU_DAA_NoOpDoorOpen_1 0 "No Error" 1 "Error" ;
VAL_ 528 RCU_EPBParkingStatus 0 "Both brakes released" 1 "both brakes applied" 2 "Both brakes in operation (applying/releasing)" 3 "unknown" ;
VAL_ 528 EPB_Swch_Mafnc 0 "No Error" 1 "Error" ;
VAL_ 528 RCU_ParkBrkApplied_1 0 "No Error" 1 "Error" ;
VAL_ 528 RCU_ReleaseEPB_Wo_PressBrk_1 0 "No Error" 1 "Error" ;
VAL_ 528 RCU_BrkForceNotEnough_1 0 "No Error" 1 "Error" ;
VAL_ 528 RCU_ParkOnSteepInclination_1 0 "No Error" 1 "Error" ;
VAL_ 528 RCU_ECD_RWU_active_1 0 "No Error" 1 "Error" ;
VAL_ 528 RCU_EHandBrk_fault_1 0 "No Error" 1 "Error" ;
VAL_ 528 RCU_BRAKE_LightonRequestEPBi 0 "Brake light OFF" 1 "Brake light ON" 2 "Reserved" 3 "Signal not available" ;
VAL_ 529 PcbCtrlFail 0 "PCB NORMAL STATE" 1 "PCB FAIL STATE" ;
VAL_ 529 PcbActiveFlg 0 "PCB NOT ACTIVATE" 1 "PCB ACTIVATE" ;
VAL_ 530 IDB_BLSInvalidSts 0 "Normal" 1 "Fail" 2 "Suspect" ;
VAL_ 530 IDB_AxInvalidSts 0 "Normal" 1 "Fail" 2 "Suspect" ;
VAL_ 532 VCU_ADAS_ControledRes 0 "Inactive" 1 "Active" ;
VAL_ 532 VCU_ADAS_Available 0 "Available" 1 "Not Available" ;
VAL_ 532 VCU_ADAS_FuncMode 0 "Function Not Active" 1 "APA Mode" 2 "RP Mode" 3 "SM Mode" ;
VAL_ 532 VCU_ADAS_CtrlAbortFeedback 0 "normal" 1 "vehicle block" 2 "Reserved" 3 "over speed" 4 "cannot change Gear" 5 "Driver intervence(gear)" ;
VAL_ 570 IDB_WheelDirection_FR 0 "Standstill" 1 "Forward" 2 "Backward" 3 "Invalid" ;
VAL_ 570 IDB_WheelDirection_FL 0 "Standstill" 1 "Forward" 2 "Backward" 3 "Invalid" ;
VAL_ 571 IDB_WheelDirection_RR 0 "Standstill" 1 "Forward" 2 "Backward" 3 "Invalid" ;
VAL_ 571 IDB_WheelDirection_RL 0 "Standstill" 1 "Forward" 2 "Backward" 3 "Invalid" ;
VAL_ 596 QU_AVL_RPM_WHL_RLH 1 "Signal value is valid and secured and checked for plausibility" 2 "Reserved" 3 "Reserved" 4 "Substitute value is set in the useful signal" 6 "Signal value is invalid (Electrical fault, can be repaired)" 7 "Reserved" 8 "initialization" 9 "Reserved" 10 "Reserved" 11 "Signal quality or monitoring restricted, state / status temporary" 12 "Substitute value is set in the useful signal State / status temporary" 14 "Signal value is invalid (Electrical fault, can not repaired)" 15 "Signal invalid" ;
VAL_ 596 QU_AVL_RPM_WHL_RRH 1 "Signal value is valid and secured and checked for plausibility" 2 "Reserved" 3 "Reserved" 4 "Substitute value is set in the useful signal" 6 "Signal value is invalid (Electrical fault, can be repaired)" 7 "Reserved" 8 "initialization" 9 "Reserved" 10 "Reserved" 11 "Signal quality or monitoring restricted, state / status temporary" 12 "Substitute value is set in the useful signal State / status temporary" 14 "Signal value is invalid (Electrical fault, can not repaired)" 15 "Signal invalid" ;
VAL_ 597 QU_AVL_RPM_WHL_FLH 1 "Signal value is valid and secured and checked for plausibility" 2 "Reserved" 3 "Reserved" 4 "Substitute value is set in the useful signal" 6 "Signal value is invalid (Electrical fault, can be repaired)" 7 "Reserved" 8 "initialization" 9 "Reserved" 10 "Reserved" 11 "Signal quality or monitoring restricted, state / status temporary" 12 "Substitute value is set in the useful signal State / status temporary" 14 "Signal value is invalid (Electrical fault, can not repaired)" 15 "Signal invalid" ;
VAL_ 597 QU_AVL_RPM_WHL_FRH 1 "Signal value is valid and secured and checked for plausibility" 2 "Reserved" 3 "Reserved" 4 "Substitute value is set in the useful signal" 6 "Signal value is invalid (Electrical fault, can be repaired)" 7 "Reserved" 8 "initialization" 9 "Reserved" 10 "Reserved" 11 "Signal quality or monitoring restricted, state / status temporary" 12 "Substitute value is set in the useful signal State / status temporary" 14 "Signal value is invalid (Electrical fault, can not repaired)" 15 "Signal invalid" ;
VAL_ 617 VCU_VehicleHVStatus 0 "Not ready" 1 "HV On" 2 "ReadyToDrive" 3 "Reserved" ;
VAL_ 649 AxOutStatus 0 "Valid" 1 "Invalid" ;
VAL_ 649 QU_VYAW_VEH 0 "Description for the value '0x0'" 1 "Description for the value '0x1'" ;
VAL_ 649 AyOutStatus 0 "Valid" 1 "Invalid" ;
VAL_ 649 AcceleratorY 16533 "Invalid" ;
VAL_ 649 AcceleratorX 16533 "Invalid" ;
VAL_ 714 MHU_STAT_CoolantLevelStatus 0 "Normal condition" 1 "Low level condition" 2 "Reserved" 3 "Signal Invalid" ;
VAL_ 760 DISP_DATE_WDAY 1 "Monday" 2 "Tuesday" 3 "Wednesday" 4 "Thursday" 5 "Friday" 6 "Saturday" 7 "Sunday" 15 "Signal invalid" ;
VAL_ 760 ST_DISP_CTI_DATE 0 "data not valid" 1 "data valid" 3 "UTC" 5 "winter time" 6 "Manually set time" 7 "summer time" 15 "signal invalid" ;
VAL_ 796 EPS_ADAS_FuncMode 0 "Function Not Active" 1 "APA Mode" 2 "RP Mode" 3 "SM Mode" ;
VAL_ 796 EPS_Drive_Intervention 0 "No Intervention" 1 "Intervention" ;
VAL_ 796 EPS_ADAS_StrAngRes 0 "Inactive" 1 "Active" ;
VAL_ 796 EPS_ADAS_ControlAvailable 0 "Available" 1 "Not Available" ;
VAL_ 796 EPS_TorqueLimitationState 0 "no saturation" 1 "Saturation effective" ;
VAL_ 796 EPS_ADAS_CtrlAbortFeedback 0 "No Abort" 1 "Maneuver terminated" 2 "StrWhlAng out of limit" 3 "StrWhlAng speed out of limit" 4 "Communication failure" 5 "EPS internal error" 6 "Vehicle speed exceeds limits when in control" 7 "Improper handshaking" 8 "Reserved" 9 "Reserved" 10 "Reserved" 11 "Reserved" 12 "Reserved" 13 "Reserved" 14 "Reserved" 15 "Reserved" ;
VAL_ 813 ADAS_ACC_Information 0 "System without error" 1 "Performance Degraded" 2 "Temporary unavailable" 3 "ACC Service Required" ;
VAL_ 813 ADAS_ACC_Main_Mode 0 "ACC Switch Off" 1 "ACC Switch On" ;
VAL_ 813 ADAS_ACC_StandstillReq 0 "No request" 1 "Stop control is required" ;
VAL_ 813 ADAS_ACC_Mode 0 "initialization" 1 "OFF" 2 "Inhibited" 3 "Standby" 4 "Active" 5 "Override" 6 "Brake Only" 7 "Fault" ;
VAL_ 813 ADAS_ACC_IDB_DecCmdAct 0 "No Deceleration" 1 "Deceleration" ;
VAL_ 814 ADAS_AEB_Prefill 0 "No demand" 1 "Demand" ;
VAL_ 814 ADAS_AEB_HBA_Level 0 "Standard threshold" 1 "Lowered threshold 1" 2 "Lowered threshold 2" 3 "Lowered threshold 3" ;
VAL_ 814 ADAS_AEB_HBA_Req 0 "No request" 1 "Request" ;
VAL_ 814 ADAS_AEB_Braking_Progress 0 "No demand" 1 "Demand" ;
VAL_ 814 ADAS_AEB_Hold 0 "No hold" 1 "Hold" ;
VAL_ 814 FCAM_AEB_DBS_Active 0 "DBS Not Activated" 1 "DBS Activated";
VAL_ 815 IDB_ACC_Available_Flag 0 "Not available" 1 "Available" ;
VAL_ 815 IDB_ACC_Deceleration_Flag 0 "Not active" 1 "Active" ;
VAL_ 815 IDB_ACC_Acceleration_Flag 0 "Not active" 1 "Active" ;
VAL_ 815 IDB_RAEB_Active_Flag 0 "Not Active" 1 "Active" ;
VAL_ 815 IDB_RAEB_Available_Flag 0 "Not available" 1 "Available" ;
VAL_ 815 IDB_AEB_Active_Flag 0 "Not active" 1 "Active" ;
VAL_ 815 IDB_AEB_Available_Flag 0 "Not available" 1 "Available" ;
VAL_ 815 IDB_ACC_DriverOverride 0 "No override" 1 "Acceleration pedal override" 2 "Brake pedal override" ;
VAL_ 816 ADAS_EPS_StrConReq 0 "No Request" 1 "Request" ;
VAL_ 816 ADAS_EPS_Status 0 "off" 1 "standby" 2 "Enable" 3 "Active" 4 "Finished" 5 "Suspend" 6 "Abort" 7 "Failed" ;
VAL_ 816 ADAS_EPS_FuncMode 0 "Function Not Active" 1 "FAPA Mode" 2 "RP Mode" 3 "SM Mode" ;
VAL_ 817 ST_FLLV_FUTA_SPAR 0 "No active" 1 "Active" 2 "Reserved" 3 "Signal invalid" ;
VAL_ 890 ADAS_EPS_StrWhe_TOLAct 0 "Deactivate Torque Overlay" 1 "Activate Torque Overlay" 2 " Reserve" 3 "Reserve" ;
VAL_ 890 ADAS_EPS_StrWhe_AOLAct 0 "Deactivate Angle Overlay" 1 "Activate Angle Overlay" 2 " Reserve" 3 "Reserve" ;
VAL_ 891 EPS_ADAS_AOLAct 0 "Deactivation" 1 "Activation" 2 " Reserve" 3 "Reserve" ;
VAL_ 894 EPS_TorqSensorSts 0 "Valid" 1 "Invalid" ;
VAL_ 894 EPS_SteeringTorque 4095 "Invalid" ;
VAL_ 894 EPS_SteeringTorqueValid 0 "Valid" 1 "Invalid" ;
VAL_ 894 EPS_Mode 0 "full assist" 1 "low assist" 2 "no assist" 3 " Invalid" ;
VAL_ 894 EPSAngRespSts 0 "Init (initialization)" 1 "Ready (ready, can support)" 2 "Active" 3 "Error (EPS failure)" ;
